VERSION "HNPBNYYYYYYYYYYYYYYYYYYYYYYYYYYYNNNNNNNNNN/4/%%/4/'%**4NNN///"

NS_ :

BS_:

BU_: ADL Aux_Device CANLogger CTU Central CentralMulti OffboardUDS Predecessor_Node RDC Radar SensorCANopen Simulator TEPM TIM TPMS iTEPM
BO_ 2566881294 Lausch_0 : 8 General_Tester
 SG_ V_RAW_0 : 0|16@1- (1,0) [-32768|32767] "1/512m/s" Vector__XXX
 SG_ N_EDGE_0 : 16|8@1+ (1,0) [0|255] "" Vector__XXX
 SG_ ERR_CTR_0 : 24|8@1- (1,0) [-128|127] "" Vector__XXX
 SG_ V_RAW_1 : 32|16@1- (1,0) [-32768|32767] "1/512m/s" Vector__XXX
 SG_ N_EDGE_1 : 48|8@1+ (1,0) [0|255] "" Vector__XXX
 SG_ ERR_CTR_1 : 56|8@1- (1,0) [-128|127] "" Vector__XXX

BO_ 2566881550 Lausch_1 : 8 General_Tester
 SG_ P21_p : 0|16@1- (1,0) [-32768|32767] "mbar" Vector__XXX
 SG_ P22_p : 16|16@1- (1,0) [-32768|32767] "mbar" Vector__XXX
 SG_ SC_v : 32|16@1- (1,0) [-32768|32767] "2mm/s" Vector__XXX
 SG_ SD_v : 48|16@1- (1,0) [-32768|32767] "2mm/s" Vector__XXX

BO_ 2566881806 Lausch_2 : 8 General_Tester
 SG_ VrefFilter : 0|16@1- (1,0) [-32768|32767] "2mm/s" Vector__XXX
 SG_ VrefStatus : 16|16@1+ (1,0) [0|65535] "" Vector__XXX
 SG_ Vref : 32|16@1- (1,0) [-32768|32767] "2mm/s" Vector__XXX
 SG_ P1_Virt_p : 48|16@1- (1,0) [-32768|32767] "mbar" Vector__XXX

BO_ 2566882062 Lausch_3 : 8 General_Tester
 SG_ P21_Pref : 0|16@1+ (1,0) [0|65535] "mbar" Vector__XXX
 SG_ P22_Pref : 16|16@1+ (1,0) [0|65535] "mbar" Vector__XXX
 SG_ P21_ACT : 32|16@1+ (1,0) [0|65535] "mbar" Vector__XXX
 SG_ P22_ACT : 48|16@1+ (1,0) [0|65535] "mbar" Vector__XXX

BO_ 2566882318 Lausch_4 : 8 General_Tester
 SG_ P21_PCLStatus : 0|8@1+ (1,0) [0|255] "" Vector__XXX
 SG_ P22_PCLStatus : 8|8@1+ (1,0) [0|255] "" Vector__XXX
 SG_ P21_Vcom : 16|8@1- (1,0) [-128|127] "" Vector__XXX
 SG_ P22_Vcom : 24|8@1- (1,0) [-128|127] "" Vector__XXX
 SG_ P21LearnLd : 32|8@1- (1,0) [-128|127] "" Vector__XXX
 SG_ P21LearnEx : 40|8@1- (1,0) [-128|127] "" Vector__XXX
 SG_ P22LearnLd : 48|8@1- (1,0) [-128|127] "" Vector__XXX
 SG_ P22LearnEx : 56|8@1- (1,0) [-128|127] "" Vector__XXX

BO_ 2566882574 Lausch_5 : 8 General_Tester
 SG_ OPDRStatus : 0|8@1+ (1,0) [0|255] "" Vector__XXX
 SG_ SuppStat : 8|8@1+ (1,0) [0|255] "" Vector__XXX
 SG_ OutputCON : 16|16@1+ (1,0) [0|65535] "" Vector__XXX
 SG_ OutputACT : 32|16@1+ (1,0) [0|65535] "" Vector__XXX
 SG_ OutputDEF : 48|16@1+ (1,0) [0|65535] "" Vector__XXX

BO_ 2566882830 Lausch_6 : 8 General_Tester
 SG_ PM_Status : 0|16@1+ (1,0) [0|65535] "" Vector__XXX
 SG_ U_PS : 16|8@1+ (200,0) [0|255] "mV" Vector__XXX
 SG_ U_IGN : 24|8@1+ (200,0) [0|255] "mV" Vector__XXX
 SG_ U_BL : 32|8@1+ (200,0) [0|255] "mV" Vector__XXX
 SG_ PowerState : 40|8@1+ (1,0) [0|255] "" Vector__XXX
 SG_ P2xIMeas : 48|8@1+ (100,0) [0|255] "mA" Vector__XXX
 SG_ AuxIMeas : 56|8@1+ (100,0) [0|255] "mA" Vector__XXX

BO_ 2566883086 Lausch_7 : 8 General_Tester
 SG_ P21_Pdes : 0|16@1+ (1,0) [0|65535] "mbar" Vector__XXX
 SG_ P22_Pdes : 16|16@1+ (1,0) [0|65535] "mbar" Vector__XXX
 SG_ P21_Test : 32|8@1+ (1,0) [0|255] "" Vector__XXX
 SG_ P22_Test : 40|8@1+ (1,0) [0|255] "" Vector__XXX

BO_ 2566883342 Lausch_8 : 8 General_Tester
 SG_ Runtime10ms : 0|16@1+ (1,0) [0|65535] "" Vector__XXX
 SG_ WLRed : 16|1@1+ (1,0) [0|255] "" Vector__XXX
 SG_ WLYellow : 17|1@1+ (1,0) [0|255] "" Vector__XXX
 SG_ WLInfo : 18|1@1+ (1,0) [0|255] "" Vector__XXX
 SG_ P21EBS_CNA : 19|1@1+ (1,0) [0|255] "" Vector__XXX
 SG_ P21BABS_CNA : 20|1@1+ (1,0) [0|255] "" Vector__XXX
 SG_ P21BCKP_CNA : 21|1@1+ (1,0) [0|255] "" Vector__XXX
 SG_ P22EBS_CNA : 22|1@1+ (1,0) [0|255] "" Vector__XXX
 SG_ P22BABS_CNA : 23|1@1+ (1,0) [0|255] "" Vector__XXX
 SG_ P22BCKP_CNA : 24|1@1+ (1,0) [0|255] "" Vector__XXX
 SG_ P2EBS_CNA : 25|1@1+ (1,0) [0|255] "" Vector__XXX
 SG_ P2BABS_CNA : 26|1@1+ (1,0) [0|255] "" Vector__XXX
 SG_ P2BCKP_CNA : 27|1@1+ (1,0) [0|255] "" Vector__XXX
 SG_ WSSC_CNA : 28|1@1+ (1,0) [0|255] "" Vector__XXX
 SG_ WSSD_CNA : 29|1@1+ (1,0) [0|255] "" Vector__XXX
 SG_ WSSE_CNA : 30|1@1+ (1,0) [0|255] "" Vector__XXX
 SG_ WSSF_CNA : 31|1@1+ (1,0) [0|255] "" Vector__XXX
 SG_ WSSA_CNA : 32|1@1+ (1,0) [0|255] "" Vector__XXX
 SG_ WSSB_CNA : 33|1@1+ (1,0) [0|255] "" Vector__XXX
 SG_ US_1 : 40|16@1+ (1,0) [0|65535] "mV" Vector__XXX

BO_ 2566883598 Lausch_9 : 8 General_Tester
 SG_ PS_P21_p : 0|16@1- (1,0) [-32768|32767] "mbar" Vector__XXX
 SG_ PS_P22_p : 16|16@1- (1,0) [-32768|32767] "mbar" Vector__XXX
 SG_ PS_P4_p : 32|16@1- (1,0) [-32768|32767] "mbar" Vector__XXX
 SG_ PS_P1_p : 48|16@1- (1,0) [-32768|32767] "mbar" Vector__XXX

BO_ 2566883854 Lausch_10 : 8 General_Tester
 SG_ PS_P42_p : 0|16@1- (1,0) [-32768|32767] "mbar" Vector__XXX
 SG_ PS_P21_Stat : 16|8@1+ (1,0) [0|255] "" Vector__XXX
 SG_ PS_P22_Stat : 24|8@1+ (1,0) [0|255] "" Vector__XXX
 SG_ PS_P4_Stat : 32|8@1+ (1,0) [0|255] "" Vector__XXX
 SG_ PS_P1_Stat : 40|8@1+ (1,0) [0|255] "" Vector__XXX
 SG_ PS_P42_Stat : 48|8@1+ (1,0) [0|255] "" Vector__XXX

BO_ 2566884110 Lausch_11 : 8 General_Tester
 SG_ P4_p : 0|16@1- (1,0) [-32768|32767] "mbar" Vector__XXX
 SG_ PneuDemand : 16|16@1- (1,0) [-32768|32767] "mbar" Vector__XXX
 SG_ CanDemand : 32|16@1+ (1,0) [0|65535] "mbar" Vector__XXX
 SG_ PdesDriver : 48|16@1+ (1,0) [0|65535] "mbar" Vector__XXX

BO_ 2566884366 Lausch_12 : 8 General_Tester
 SG_ XCHK_TIMER_CALIB : 0|16@1+ (1,0) [0|65535] "" Vector__XXX
 SG_ XCHK_MIN_P_INCR : 16|16@1- (1,0) [-32768|32767] "" Vector__XXX
 SG_ XCHK_CONTROL_STAT : 32|8@1+ (1,0) [0|255] "" Vector__XXX
 SG_ XCHK_RESULT_STAT : 40|8@1+ (1,0) [0|255] "" Vector__XXX
 SG_ XCHK_MASK_FULL : 48|8@1+ (1,0) [0|255] "" Vector__XXX
 SG_ XCHK_MASK_OP : 56|8@1+ (1,0) [0|255] "" Vector__XXX

BO_ 2566884622 Lausch_13 : 8 General_Tester
 SG_ P21_Iterm : 0|16@1+ (1,0) [0|65535] "" Vector__XXX
 SG_ P22_Iterm : 16|16@1+ (1,0) [0|65535] "" Vector__XXX
 SG_ P21_Ppid : 32|16@1+ (1,0) [0|65535] "" Vector__XXX
 SG_ P21_Prcov : 48|16@1+ (1,0) [0|65535] "" Vector__XXX

BO_ 2566884878 Lausch_14 : 8 General_Tester
 SG_ P21_StableTimer : 0|16@1+ (1,0) [0|65535] "" Vector__XXX
 SG_ P22_StableTimer : 16|16@1+ (1,0) [0|65535] "" Vector__XXX
 SG_ PdemCoordp21_Prio : 32|4@1+ (1,0) [0|255] "" Vector__XXX
 SG_ PdemCoordp22_Prio : 36|4@1+ (1,0) [0|255] "" Vector__XXX
 SG_ ABSP21PidStable : 40|1@1+ (1,0) [0|255] "" Vector__XXX
 SG_ ABSP21PidStopped : 41|1@1+ (1,0) [0|255] "" Vector__XXX
 SG_ ABSP21PidAllowOff : 42|1@1+ (1,0) [0|255] "" Vector__XXX
 SG_ ABSP21PidNoLoad : 43|1@1+ (1,0) [0|255] "" Vector__XXX
 SG_ ABSP21PidPdesLimit : 44|1@1+ (1,0) [0|255] "" Vector__XXX
 SG_ ABSP21RcovKeepDownP : 45|1@1+ (1,0) [0|255] "" Vector__XXX
 SG_ ABSP21RcovInshotNow : 46|1@1+ (1,0) [0|255] "" Vector__XXX
 SG_ ABSP21RcovDetectRunup : 47|1@1+ (1,0) [0|255] "" Vector__XXX
 SG_ ABSP22PidStable : 48|1@1+ (1,0) [0|255] "" Vector__XXX
 SG_ ABSP22PidStopped : 49|1@1+ (1,0) [0|255] "" Vector__XXX
 SG_ ABSP22PidAllowOff : 50|1@1+ (1,0) [0|255] "" Vector__XXX
 SG_ ABSP22PidNoLoad : 51|1@1+ (1,0) [0|255] "" Vector__XXX
 SG_ ABSP22PidPdesLimit : 52|1@1+ (1,0) [0|255] "" Vector__XXX
 SG_ ABSP22RcovKeepDownP : 53|1@1+ (1,0) [0|255] "" Vector__XXX
 SG_ ABSP22RcovInshotNow : 54|1@1+ (1,0) [0|255] "" Vector__XXX
 SG_ ABSP22RcovDetectRunup : 55|1@1+ (1,0) [0|255] "" Vector__XXX
 SG_ P21_PrcovTimer : 56|8@1+ (1,0) [0|255] "" Vector__XXX

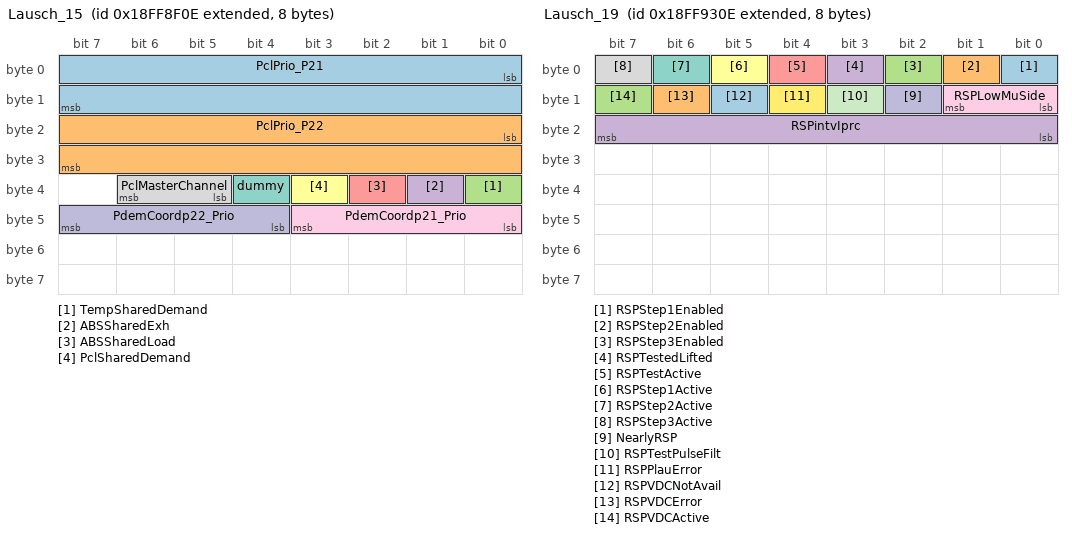
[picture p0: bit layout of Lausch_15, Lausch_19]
BO_ 2566885134 Lausch_15 : 8 General_Tester
 SG_ PclPrio_P21 : 0|16@1+ (1,0) [0|65535] "" Vector__XXX
 SG_ PclPrio_P22 : 16|16@1+ (1,0) [0|65535] "" Vector__XXX
 SG_ TempSharedDemand : 32|1@1+ (1,0) [0|255] "" Vector__XXX
 SG_ ABSSharedExh : 33|1@1+ (1,0) [0|255] "" Vector__XXX
 SG_ ABSSharedLoad : 34|1@1+ (1,0) [0|255] "" Vector__XXX
 SG_ PclSharedDemand : 35|1@1+ (1,0) [0|255] "" Vector__XXX
 SG_ dummy : 36|1@1+ (1,0) [0|255] "" Vector__XXX
 SG_ PclMasterChannel : 37|2@1+ (1,0) [0|255] "" Vector__XXX
 SG_ PdemCoordp21_Prio : 40|4@1+ (1,0) [0|255] "" Vector__XXX
 SG_ PdemCoordp22_Prio : 44|4@1+ (1,0) [0|255] "" Vector__XXX

BO_ 2566885390 Lausch_16 : 8 General_Tester
 SG_ PneuDemVirtDTerm : 0|16@1- (1,0) [-32768|32767] "mbar" Vector__XXX
 SG_ PneuDemandVirtIncr : 16|16@1- (1,0) [-32768|32767] "mbar" Vector__XXX

BO_ 2566885646 Lausch_17 : 8 General_Tester
 SG_ AyFilt : 0|16@1- (1,0) [-32768|32767] "mm/s2" Vector__XXX
 SG_ AyHFilt : 16|16@1- (1,0) [-32768|32767] "mm/s2" Vector__XXX
 SG_ AyLimLeft : 32|16@1- (1,0) [-32768|32767] "mm/s2" Vector__XXX
 SG_ AyLimRight : 48|16@1- (1,0) [-32768|32767] "mm/s2" Vector__XXX

BO_ 2566885902 Lausch_18 : 8 General_Tester
 SG_ dAyWeight : 0|16@1- (1,0) [-32768|32767] "mm/s2" Vector__XXX
 SG_ RSPtUnstabC : 16|8@1- (1,0) [-128|127] "10ms" Vector__XXX
 SG_ RSPtUnstabD : 24|8@1- (1,0) [-128|127] "10ms" Vector__XXX
 SG_ RSPtUnstabE : 32|8@1- (1,0) [-128|127] "10ms" Vector__XXX
 SG_ RSPtUnstabF : 40|8@1- (1,0) [-128|127] "10ms" Vector__XXX
 SG_ RSPtUnstabA : 48|8@1- (1,0) [-128|127] "10ms" Vector__XXX
 SG_ RSPtUnstabB : 56|8@1- (1,0) [-128|127] "10ms" Vector__XXX

BO_ 2566886158 Lausch_19 : 8 General_Tester
 SG_ RSPStep1Enabled : 0|1@1+ (1,0) [0|65535] "bits" Vector__XXX
 SG_ RSPStep2Enabled : 1|1@1+ (1,0) [0|65535] "bits" Vector__XXX
 SG_ RSPStep3Enabled : 2|1@1+ (1,0) [0|65535] "bits" Vector__XXX
 SG_ RSPTestedLifted : 3|1@1+ (1,0) [0|65535] "bits" Vector__XXX
 SG_ RSPTestActive : 4|1@1+ (1,0) [0|65535] "bits" Vector__XXX
 SG_ RSPStep1Active : 5|1@1+ (1,0) [0|65535] "bits" Vector__XXX
 SG_ RSPStep2Active : 6|1@1+ (1,0) [0|65535] "bits" Vector__XXX
 SG_ RSPStep3Active : 7|1@1+ (1,0) [0|65535] "bits" Vector__XXX
 SG_ RSPLowMuSide : 8|2@1+ (1,0) [0|65535] "bits" Vector__XXX
 SG_ NearlyRSP : 10|1@1+ (1,0) [0|65535] "bits" Vector__XXX
 SG_ RSPTestPulseFilt : 11|1@1+ (1,0) [0|65535] "bits" Vector__XXX
 SG_ RSPPlauError : 12|1@1+ (1,0) [0|65535] "bits" Vector__XXX
 SG_ RSPVDCNotAvail : 13|1@1+ (1,0) [0|65535] "bits" Vector__XXX
 SG_ RSPVDCError : 14|1@1+ (1,0) [0|65535] "bits" Vector__XXX
 SG_ RSPVDCActive : 15|1@1+ (1,0) [0|65535] "bits" Vector__XXX
 SG_ RSPintvIprc : 16|8@1- (1,0) [-128|127] "%" Vector__XXX

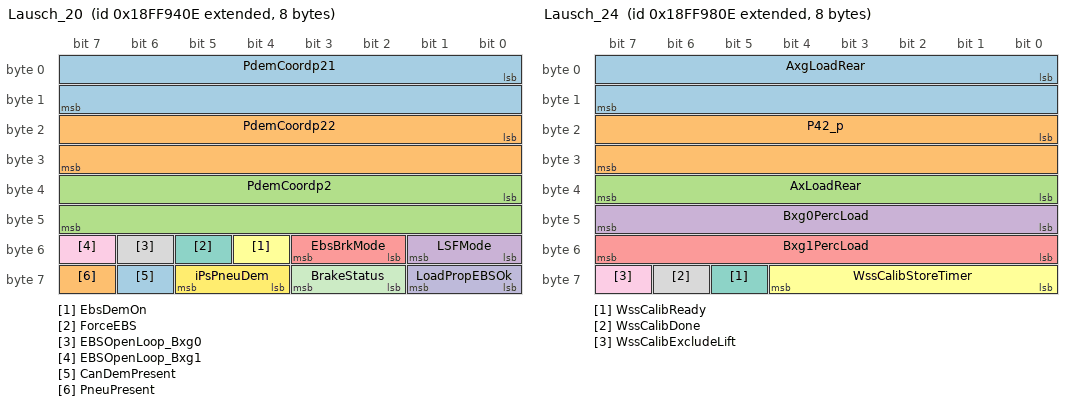
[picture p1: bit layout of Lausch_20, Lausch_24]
BO_ 2566886414 Lausch_20 : 8 General_Tester
 SG_ PdemCoordp21 : 0|16@1+ (1,0) [0|65535] "mbar" Vector__XXX
 SG_ PdemCoordp22 : 16|16@1+ (1,0) [0|65535] "mbar" Vector__XXX
 SG_ PdemCoordp2 : 32|16@1+ (1,0) [0|65535] "mbar" Vector__XXX
 SG_ LSFMode : 48|2@1+ (1,0) [0|255] "" Vector__XXX
 SG_ EbsBrkMode : 50|2@1+ (1,0) [0|255] "" Vector__XXX
 SG_ EbsDemOn : 52|1@1+ (1,0) [0|255] "" Vector__XXX
 SG_ ForceEBS : 53|1@1+ (1,0) [0|255] "" Vector__XXX
 SG_ EBSOpenLoop_Bxg0 : 54|1@1+ (1,0) [0|255] "" Vector__XXX
 SG_ EBSOpenLoop_Bxg1 : 55|1@1+ (1,0) [0|255] "" Vector__XXX
 SG_ LoadPropEBSOk : 56|2@1+ (1,0) [0|255] "" Vector__XXX
 SG_ BrakeStatus : 58|2@1+ (1,0) [0|255] "" Vector__XXX
 SG_ iPsPneuDem : 60|2@1+ (1,0) [0|255] "" Vector__XXX
 SG_ CanDemPresent : 62|1@1+ (1,0) [0|255] "" Vector__XXX
 SG_ PneuPresent : 63|1@1+ (1,0) [0|255] "" Vector__XXX

BO_ 2566886670 Lausch_21 : 8 General_Tester
 SG_ AuxVref : 0|16@1- (1,0) [-32768|32767] "" Vector__XXX
 SG_ SPState : 16|8@1+ (1,0) [0|255] "" Vector__XXX
 SG_ AuxOutputActive : 24|1@1+ (1,0) [0|255] "" Vector__XXX
 SG_ PWStatus : 32|8@1+ (1,0) [0|255] "" Vector__XXX
 SG_ PWCount : 40|8@1+ (1,0) [0|255] "" Vector__XXX
 SG_ PWBrakeCount : 48|8@1+ (1,0) [0|255] "" Vector__XXX
 SG_ StatePW : 56|8@1+ (1,0) [0|255] "" Vector__XXX

BO_ 2566886926 Lausch_22 : 8 General_Tester
 SG_ BLIRequests : 0|8@1+ (1,0) [0|255] "" Vector__XXX
 SG_ BLIInhibition : 8|8@1+ (1,0) [0|255] "" Vector__XXX
 SG_ BLINewInhReq : 16|8@1+ (1,0) [0|255] "" Vector__XXX
 SG_ BLINewRelReq : 24|8@1+ (1,0) [0|255] "" Vector__XXX
 SG_ BLIBLA_Ovr : 32|16@1- (1,0) [-32768|32767] "" Vector__XXX
 SG_ BLITbp : 48|16@1+ (1,0) [0|65535] "" Vector__XXX

BO_ 2566887182 Lausch_23 : 8 General_Tester
 SG_ BLISbp : 0|8@1+ (1,0) [0|255] "" Vector__XXX
 SG_ BLIAuxOvr : 8|1@1+ (1,0) [0|255] "" Vector__XXX
 SG_ BLIBPOvr : 9|1@1+ (1,0) [0|255] "" Vector__XXX
 SG_ BLIOvr2Store : 10|1@1+ (1,0) [0|255] "" Vector__XXX
 SG_ AuxOvrLocalVar : 11|1@1+ (1,0) [0|255] "" Vector__XXX
 SG_ BPOvrLocalVar : 12|1@1+ (1,0) [0|255] "" Vector__XXX
 SG_ BLIinhibitCAN : 13|1@1+ (1,0) [0|255] "" Vector__XXX
 SG_ BLIovrdCAN : 14|1@1+ (1,0) [0|255] "" Vector__XXX
 SG_ SALLogicOutput : 16|1@1+ (1,0) [0|255] "" Vector__XXX
 SG_ BackLightSw : 17|1@1+ (1,0) [0|255] "" Vector__XXX
 SG_ SALABSError : 18|1@1+ (1,0) [0|255] "" Vector__XXX
 SG_ ForceSAL : 19|1@1+ (1,0) [0|255] "" Vector__XXX
 SG_ ISSLogicOutput : 20|1@1+ (1,0) [0|255] "" Vector__XXX
 SG_ RLFOn : 24|1@1+ (1,0) [0|255] "" Vector__XXX
 SG_ LoadChangedInStandstill : 25|1@1+ (1,0) [0|255] "" Vector__XXX
 SG_ PdemRLF : 32|16@1+ (1,0) [0|65535] "" Vector__XXX
 SG_ AuxADLFlagsreserved : 48|1@1+ (1,0) [0|255] "" Vector__XXX
 SG_ AuxADLFlagsinstrerr : 49|1@1+ (1,0) [0|255] "" Vector__XXX
 SG_ AuxADLFlagsvererr : 50|1@1+ (1,0) [0|255] "" Vector__XXX
 SG_ AuxADLFlagschksmerr : 51|1@1+ (1,0) [0|255] "" Vector__XXX
 SG_ AuxADLFlagsproginitcomp : 52|1@1+ (1,0) [0|255] "" Vector__XXX
 SG_ AuxADLFlagsfirstcyclecomp : 53|1@1+ (1,0) [0|255] "" Vector__XXX
 SG_ AuxADLFlagsinstrnoreturn : 54|1@1+ (1,0) [0|255] "" Vector__XXX
 SG_ AuxADLFlagsenablerx : 55|1@1+ (1,0) [0|255] "" Vector__XXX
 SG_ BLS : 56|8@1+ (1,0) [0|255] "" Vector__XXX

BO_ 2566887438 Lausch_24 : 8 General_Tester
 SG_ AxgLoadRear : 0|16@1+ (10,0) [0|65535] "kg" Vector__XXX
 SG_ P42_p : 16|16@1- (1,0) [-32768|32767] "mbar" Vector__XXX
 SG_ AxLoadRear : 32|8@1+ (1,0) [0|255] "%" Vector__XXX
 SG_ Bxg0PercLoad : 40|8@1+ (1,0) [0|255] "%" Vector__XXX
 SG_ Bxg1PercLoad : 48|8@1+ (1,0) [0|255] "%" Vector__XXX
 SG_ WssCalibStoreTimer  : 56|5@1+ (1,0) [0|255] "" Vector__XXX
 SG_ WssCalibReady  : 61|1@1+ (1,0) [0|255] "" Vector__XXX
 SG_ WssCalibDone  : 62|1@1+ (1,0) [0|255] "" Vector__XXX
 SG_ WssCalibExcludeLift  : 63|1@1+ (1,0) [0|255] "" Vector__XXX

BO_ 2566887694 Lausch_25 : 8 General_Tester
 SG_ Level_Rear_RearRight : 0|16@1- (0.125,0) [-32768|32767] "mm" Vector__XXX
 SG_ TargetLevel_Rear_RearRight : 16|16@1- (0.125,0) [-32768|32767] "mm" Vector__XXX
 SG_ LevellingActive : 32|1@1+ (1,0) [0|65535] "bits" Vector__XXX
 SG_ ELC_Prohibited : 33|1@1+ (1,0) [0|65535] "bits" Vector__XXX
 SG_ ELC_TargetChanged : 34|1@1+ (1,0) [0|65535] "bits" Vector__XXX
 SG_ TSR_TriggeredByELC : 35|1@1+ (1,0) [0|65535] "bits" Vector__XXX
 SG_ iLvl_State : 36|2@1+ (1,0) [0|65535] "bits" Vector__XXX
 SG_ LAC1_Active : 38|1@1+ (1,0) [0|65535] "bits" Vector__XXX
 SG_ PneuBackup_Active_0 : 39|1@1+ (1,0) [0|65535] "bits" Vector__XXX
 SG_ PCV_iLvl2_State : 40|2@1+ (1,0) [0|65535] "bits" Vector__XXX
 SG_ LAC2_State : 42|1@1+ (1,0) [0|65535] "bits" Vector__XXX
 SG_ VehicleStandstill : 43|1@1+ (1,0) [0|65535] "bits" Vector__XXX
 SG_ VehicleBraking : 44|1@1+ (1,0) [0|65535] "bits" Vector__XXX
 SG_ LCStandstill : 45|1@1+ (1,0) [0|65535] "bits" Vector__XXX
 SG_ SupPresTooLowForLAC : 46|1@1+ (1,0) [0|65535] "bits" Vector__XXX
 SG_ AboveRTRSpeed : 47|1@1+ (1,0) [0|65535] "bits" Vector__XXX
 SG_ TAMBits : 48|16@1+ (1,0) [0|65535] "bits" Vector__XXX

BO_ 2566887950 Lausch_26 : 8 General_Tester
 SG_ P21_Pref : 0|16@1+ (1,0) [0|65535] "mbar" Vector__XXX
 SG_ P22_Pref : 16|16@1+ (1,0) [0|65535] "mbar" Vector__XXX
 SG_ P21_Pdes : 32|16@1+ (1,0) [0|65535] "mbar" Vector__XXX
 SG_ P22_Pdes : 48|16@1+ (1,0) [0|65535] "mbar" Vector__XXX

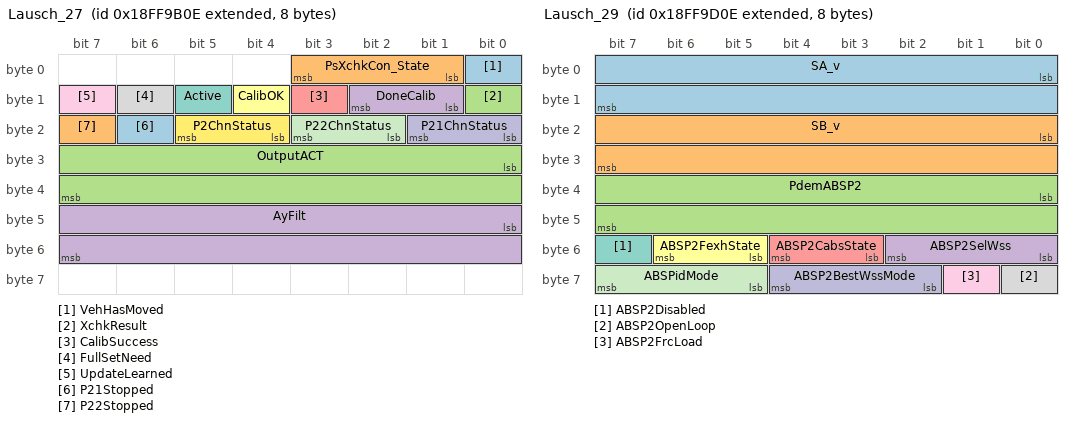
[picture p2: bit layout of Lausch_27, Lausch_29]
BO_ 2566888206 Lausch_27 : 8 General_Tester
 SG_ VehHasMoved  : 0|1@1+ (1,0) [0|255] "" Vector__XXX
 SG_ PsXchkCon_State  : 1|3@1+ (1,0) [0|255] "" Vector__XXX
 SG_ XchkResult  : 8|1@1+ (1,0) [0|255] "" Vector__XXX
 SG_ DoneCalib  : 9|2@1+ (1,0) [0|255] "" Vector__XXX
 SG_ CalibSuccess : 11|1@1+ (1,0) [0|255] "" Vector__XXX
 SG_ CalibOK : 12|1@1+ (1,0) [0|255] "" Vector__XXX
 SG_ Active : 13|1@1+ (1,0) [0|255] "" Vector__XXX
 SG_ FullSetNeed : 14|1@1+ (1,0) [0|255] "" Vector__XXX
 SG_ UpdateLearned : 15|1@1+ (1,0) [0|255] "" Vector__XXX
 SG_ P21ChnStatus  : 16|2@1+ (1,0) [0|255] "" Vector__XXX
 SG_ P22ChnStatus  : 18|2@1+ (1,0) [0|255] "" Vector__XXX
 SG_ P2ChnStatus  : 20|2@1+ (1,0) [0|255] "" Vector__XXX
 SG_ P21Stopped  : 22|1@1+ (1,0) [0|255] "" Vector__XXX
 SG_ P22Stopped  : 23|1@1+ (1,0) [0|255] "" Vector__XXX
 SG_ OutputACT : 24|16@1+ (1,0) [0|65535] "" Vector__XXX
 SG_ AyFilt : 40|16@1- (1,0) [-32768|32767] "" Vector__XXX

BO_ 2566888462 Lausch_28 : 8 General_Tester
 SG_ PdemEbsBxg0 : 0|16@1+ (1,0) [0|65535] "mbar" Vector__XXX
 SG_ PdemEbsBxg1 : 16|16@1+ (1,0) [0|65535] "mbar" Vector__XXX
 SG_ PdemABSP21 : 32|16@1+ (1,0) [0|65535] "mbar" Vector__XXX
 SG_ PdemABSP22 : 48|16@1+ (1,0) [0|65535] "mbar" Vector__XXX

BO_ 2566888718 Lausch_29 : 8 General_Tester
 SG_ SA_v : 0|16@1- (1,0) [-32768|32767] "2mm/s" Vector__XXX
 SG_ SB_v : 16|16@1- (1,0) [-32768|32767] "2mm/s" Vector__XXX
 SG_ PdemABSP2 : 32|16@1+ (1,0) [0|65535] "mbar" Vector__XXX
 SG_ ABSP2SelWss : 48|3@1+ (1,0) [0|255] "" Vector__XXX
 SG_ ABSP2CabsState : 51|2@1+ (1,0) [0|255] "" Vector__XXX
 SG_ ABSP2FexhState : 53|2@1+ (1,0) [0|255] "" Vector__XXX
 SG_ ABSP2Disabled : 55|1@1+ (1,0) [0|255] "" Vector__XXX
 SG_ ABSP2OpenLoop : 56|1@1+ (1,0) [0|255] "" Vector__XXX
 SG_ ABSP2FrcLoad : 57|1@1+ (1,0) [0|255] "" Vector__XXX
 SG_ ABSP2BestWssMode : 58|3@1+ (1,0) [0|255] "" Vector__XXX
 SG_ ABSPidMode : 61|3@1+ (1,0) [0|255] "" Vector__XXX

BO_ 2566888974 Lausch_30 : 8 General_Tester
 SG_ PdemCoordp21 : 0|16@1+ (1,0) [0|65535] "mbar" Vector__XXX
 SG_ PdemCoordp22 : 16|16@1+ (1,0) [0|65535] "mbar" Vector__XXX
 SG_ SE_v : 32|16@1- (1,0) [-32768|32767] "2mm/s" Vector__XXX
 SG_ SF_v : 48|16@1- (1,0) [-32768|32767] "2mm/s" Vector__XXX

BO_ 2566889230 Lausch_31 : 8 General_Tester
 SG_ P4_Stat : 0|8@1+ (1,0) [0|255] "" Vector__XXX
 SG_ EM_P4_Stat : 8|8@1+ (1,0) [0|255] "" Vector__XXX
 SG_ EM_P2_p : 16|16@1- (1,0) [-32768|32767] "mbar" Vector__XXX
 SG_ EM_P4_p : 32|16@1- (1,0) [-32768|32767] "mbar" Vector__XXX
 SG_ EM_P42_p : 48|16@1- (1,0) [-32768|32767] "mbar" Vector__XXX

BO_ 2566889486 Lausch_32 : 8 General_Tester
 SG_ BLMTippingAngFilt : 0|16@1- (1,0) [-32768|32767] "" Vector__XXX
 SG_ BLMAngInhAct : 16|16@1- (1,0) [-32768|32767] "" Vector__XXX
 SG_ BLMCalib : 32|8@1+ (1,0) [0|255] "" Vector__XXX
 SG_ BLMDir : 40|8@1+ (1,0) [0|255] "" Vector__XXX

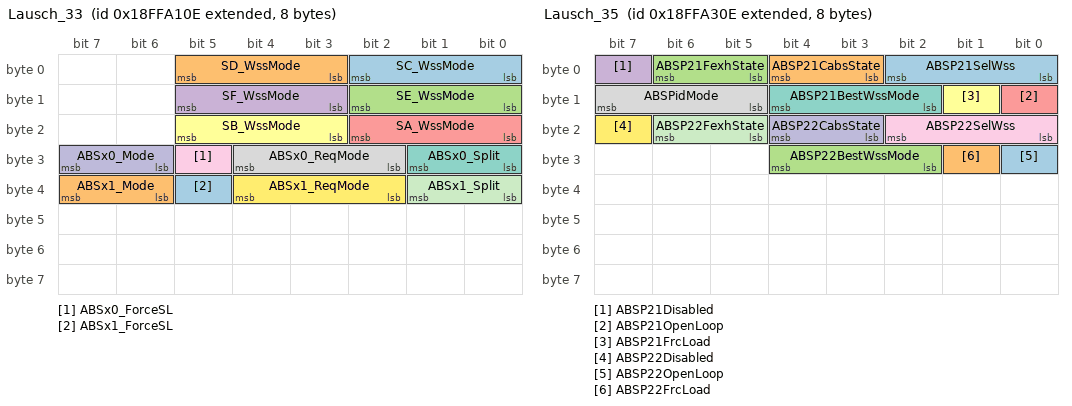
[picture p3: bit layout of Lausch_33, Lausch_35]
BO_ 2566889742 Lausch_33 : 8 General_Tester
 SG_ SC_WssMode : 0|3@1+ (1,0) [0|255] "" Vector__XXX
 SG_ SD_WssMode : 3|3@1+ (1,0) [0|255] "" Vector__XXX
 SG_ SE_WssMode : 8|3@1+ (1,0) [0|255] "" Vector__XXX
 SG_ SF_WssMode : 11|3@1+ (1,0) [0|255] "" Vector__XXX
 SG_ SA_WssMode : 16|3@1+ (1,0) [0|255] "" Vector__XXX
 SG_ SB_WssMode : 19|3@1+ (1,0) [0|255] "" Vector__XXX
 SG_ ABSx0_Split : 24|2@1+ (1,0) [0|255] "" Vector__XXX
 SG_ ABSx0_ReqMode : 26|3@1+ (1,0) [0|255] "" Vector__XXX
 SG_ ABSx0_ForceSL : 29|1@1+ (1,0) [0|255] "" Vector__XXX
 SG_ ABSx0_Mode : 30|2@1+ (1,0) [0|255] "" Vector__XXX
 SG_ ABSx1_Split : 32|2@1+ (1,0) [0|255] "" Vector__XXX
 SG_ ABSx1_ReqMode : 34|3@1+ (1,0) [0|255] "" Vector__XXX
 SG_ ABSx1_ForceSL : 37|1@1+ (1,0) [0|255] "" Vector__XXX
 SG_ ABSx1_Mode : 38|2@1+ (1,0) [0|255] "" Vector__XXX

BO_ 2566889998 Lausch_34 : 8 General_Tester
 SG_ SC_WssTest : 0|8@1+ (1,0) [0|255] "" Vector__XXX
 SG_ SD_WssTest : 8|8@1+ (1,0) [0|255] "" Vector__XXX
 SG_ SE_WssTest : 16|8@1+ (1,0) [0|255] "" Vector__XXX
 SG_ SF_WssTest : 24|8@1+ (1,0) [0|255] "" Vector__XXX
 SG_ SA_WssTest : 32|8@1+ (1,0) [0|255] "" Vector__XXX
 SG_ SB_WssTest : 40|8@1+ (1,0) [0|255] "" Vector__XXX

BO_ 2566890254 Lausch_35 : 8 General_Tester
 SG_ ABSP21SelWss : 0|3@1+ (1,0) [0|255] "" Vector__XXX
 SG_ ABSP21CabsState : 3|2@1+ (1,0) [0|255] "" Vector__XXX
 SG_ ABSP21FexhState : 5|2@1+ (1,0) [0|255] "" Vector__XXX
 SG_ ABSP21Disabled : 7|1@1+ (1,0) [0|255] "" Vector__XXX
 SG_ ABSP21OpenLoop : 8|1@1+ (1,0) [0|255] "" Vector__XXX
 SG_ ABSP21FrcLoad : 9|1@1+ (1,0) [0|255] "" Vector__XXX
 SG_ ABSP21BestWssMode : 10|3@1+ (1,0) [0|255] "" Vector__XXX
 SG_ ABSPidMode : 13|3@1+ (1,0) [0|255] "" Vector__XXX
 SG_ ABSP22SelWss : 16|3@1+ (1,0) [0|255] "" Vector__XXX
 SG_ ABSP22CabsState : 19|2@1+ (1,0) [0|255] "" Vector__XXX
 SG_ ABSP22FexhState : 21|2@1+ (1,0) [0|255] "" Vector__XXX
 SG_ ABSP22Disabled : 23|1@1+ (1,0) [0|255] "" Vector__XXX
 SG_ ABSP22OpenLoop : 24|1@1+ (1,0) [0|255] "" Vector__XXX
 SG_ ABSP22FrcLoad : 25|1@1+ (1,0) [0|255] "" Vector__XXX
 SG_ ABSP22BestWssMode : 26|3@1+ (1,0) [0|255] "" Vector__XXX

BO_ 2566890510 Lausch_36 : 8 General_Tester
 SG_ SC_WssCalibDiamDev : 0|8@1- (1,0) [-128|127] "" Vector__XXX
 SG_ SD_WssCalibDiamDev : 8|8@1- (1,0) [-128|127] "" Vector__XXX
 SG_ SE_WssCalibDiamDev : 16|8@1- (1,0) [-128|127] "" Vector__XXX
 SG_ SF_WssCalibDiamDev : 24|8@1- (1,0) [-128|127] "" Vector__XXX
 SG_ SA_WssCalibDiamDev : 32|8@1- (1,0) [-128|127] "" Vector__XXX
 SG_ SB_WssCalibDiamDev : 40|8@1- (1,0) [-128|127] "" Vector__XXX

BO_ 2566890766 Lausch_37 : 8 General_Tester
 SG_ SC_Airgap : 0|16@1- (1,0) [-32768|32767] "" Vector__XXX
 SG_ SD_Airgap : 16|16@1- (1,0) [-32768|32767] "" Vector__XXX
 SG_ SE_Airgap : 32|16@1- (1,0) [-32768|32767] "" Vector__XXX
 SG_ SF_Airgap : 48|16@1- (1,0) [-32768|32767] "" Vector__XXX

BO_ 2566891022 Lausch_38 : 8 General_Tester
 SG_ SA_Airgap : 0|16@1- (1,0) [-32768|32767] "" Vector__XXX
 SG_ SB_Airgap : 16|16@1- (1,0) [-32768|32767] "" Vector__XXX
 SG_ SC_OverInstallDone : 32|1@1+ (1,0) [0|255] "" Vector__XXX
 SG_ SC_AirgapCheckAct : 33|1@1+ (1,0) [0|255] "" Vector__XXX
 SG_ SC_ConfirmedNoAirgap : 34|1@1+ (1,0) [0|255] "" Vector__XXX
 SG_ SC_airgap_suspect : 35|1@1+ (1,0) [0|255] "" Vector__XXX
 SG_ SD_OverInstallDone : 36|1@1+ (1,0) [0|255] "" Vector__XXX
 SG_ SD_AirgapCheckAct : 37|1@1+ (1,0) [0|255] "" Vector__XXX
 SG_ SD_ConfirmedNoAirgap : 38|1@1+ (1,0) [0|255] "" Vector__XXX
 SG_ SD_airgap_suspect : 39|1@1+ (1,0) [0|255] "" Vector__XXX
 SG_ SE_OverInstallDone : 40|1@1+ (1,0) [0|255] "" Vector__XXX
 SG_ SE_AirgapCheckAct : 41|1@1+ (1,0) [0|255] "" Vector__XXX
 SG_ SE_ConfirmedNoAirgap : 42|1@1+ (1,0) [0|255] "" Vector__XXX
 SG_ SE_airgap_suspect : 43|1@1+ (1,0) [0|255] "" Vector__XXX
 SG_ SF_OverInstallDone : 44|1@1+ (1,0) [0|255] "" Vector__XXX
 SG_ SF_AirgapCheckAct : 45|1@1+ (1,0) [0|255] "" Vector__XXX
 SG_ SF_ConfirmedNoAirgap : 46|1@1+ (1,0) [0|255] "" Vector__XXX
 SG_ SF_airgap_suspect : 47|1@1+ (1,0) [0|255] "" Vector__XXX
 SG_ SA_OverInstallDone : 48|1@1+ (1,0) [0|255] "" Vector__XXX
 SG_ SA_AirgapCheckAct : 49|1@1+ (1,0) [0|255] "" Vector__XXX
 SG_ SA_ConfirmedNoAirgap : 50|1@1+ (1,0) [0|255] "" Vector__XXX
 SG_ SA_airgap_suspect : 51|1@1+ (1,0) [0|255] "" Vector__XXX
 SG_ SB_OverInstallDone : 52|1@1+ (1,0) [0|255] "" Vector__XXX
 SG_ SB_AirgapCheckAct : 53|1@1+ (1,0) [0|255] "" Vector__XXX
 SG_ SB_ConfirmedNoAirgap : 54|1@1+ (1,0) [0|255] "" Vector__XXX
 SG_ SB_airgap_suspect : 55|1@1+ (1,0) [0|255] "" Vector__XXX

BO_ 2566891278 Lausch_39 : 8 General_Tester
 SG_ AxLoadDolly : 0|8@1+ (1,0) [0|255] "%" Vector__XXX
 SG_ AxgLoadDolly : 8|16@1+ (10,0) [0|65535] "kg" Vector__XXX
 SG_ TargetLevel_Front_RearLeft : 24|16@1- (0.125,0) [-32768|32767] "mm" Vector__XXX
 SG_ Level_Front_RearLeft : 40|16@1- (0.125,0) [-32768|32767] "mm" Vector__XXX
 SG_ TargetPercLoad_Sxg0 : 56|8@1+ (1,0) [0|255] "%" Vector__XXX

BO_ 2566891534 Lausch_40 : 8 General_Tester
 SG_ TargetPercLoad_Sxg1 : 0|8@1+ (1,0) [0|255] "%" Vector__XXX
 SG_ TargetPercLoad_Sxg2 : 8|8@1+ (1,0) [0|255] "%" Vector__XXX
 SG_ Sxg0_PercLoad : 16|8@1+ (1,0) [0|255] "%" Vector__XXX
 SG_ Sxg1_PercLoad : 24|8@1+ (1,0) [0|255] "%" Vector__XXX
 SG_ Sxg2_PercLoad : 32|8@1+ (1,0) [0|255] "%" Vector__XXX

BO_ 2566891790 Lausch_41 : 8 General_Tester
 SG_ ABSP21Pmax : 0|16@1+ (1,0) [0|65535] "mbar" Vector__XXX
 SG_ ABSP21Pref : 16|16@1+ (1,0) [0|65535] "mbar" Vector__XXX
 SG_ ABSP21Pact : 32|16@1+ (1,0) [0|65535] "mbar" Vector__XXX
 SG_ ABSP21PrioTimer : 48|8@1+ (1,0) [0|255] "" Vector__XXX

BO_ 2566892046 Lausch_42 : 8 General_Tester
 SG_ ABSP22Pmax : 0|16@1+ (1,0) [0|65535] "mbar" Vector__XXX
 SG_ ABSP22Pref : 16|16@1+ (1,0) [0|65535] "mbar" Vector__XXX
 SG_ ABSP22Pact : 32|16@1+ (1,0) [0|65535] "mbar" Vector__XXX
 SG_ ABSP22PrioTimer : 48|8@1+ (1,0) [0|255] "" Vector__XXX

BO_ 2566892302 Lausch_43 : 8 General_Tester
 SG_ AyOffset : 0|16@1- (1,0) [-32768|32767] "mm/s2" Vector__XXX
 SG_ AyCalc : 16|16@1- (1,0) [-32768|32767] "mm/s2" Vector__XXX
 SG_ TurnSlip_L : 32|8@1- (1,0) [-128|127] "%" Vector__XXX
 SG_ TurnSlip_R : 40|8@1- (1,0) [-128|127] "%" Vector__XXX
 SG_ TurnSlip_RL : 48|8@1- (1,0) [-128|127] "%" Vector__XXX
 SG_ TurnSlip_RR : 56|8@1- (1,0) [-128|127] "%" Vector__XXX

BO_ 2566892558 Lausch_44 : 8 General_Tester
 SG_ P21PrefUncont : 0|16@1- (1,0) [-32768|32767] "mbar" Vector__XXX
 SG_ P21PrefLeak : 16|16@1- (1,0) [-32768|32767] "mbar" Vector__XXX
 SG_ P21PlauInteg : 32|16@1- (1,0) [-32768|32767] "mbar" Vector__XXX
 SG_ P21PlauVActCtr : 48|8@1+ (1,0) [0|255] "" Vector__XXX
 SG_ P21PlauHighCtr : 56|8@1+ (1,0) [0|255] "" Vector__XXX

BO_ 2566892814 Lausch_45 : 8 General_Tester
 SG_ P22PrefUncont : 0|16@1- (1,0) [-32768|32767] "mbar" Vector__XXX
 SG_ P22PrefLeak : 16|16@1- (1,0) [-32768|32767] "mbar" Vector__XXX
 SG_ P22PlauInteg : 32|16@1- (1,0) [-32768|32767] "mbar" Vector__XXX
 SG_ P22PlauVActCtr : 48|8@1+ (1,0) [0|255] "" Vector__XXX
 SG_ P22PlauHighCtr : 56|8@1+ (1,0) [0|255] "" Vector__XXX

BO_ 2566893070 Lausch_46 : 8 General_Tester
 SG_ ValveActCntr_Id : 0|8@1+ (1,0) [0|255] "" Vector__XXX
 SG_ ValveActCntr_Val : 8|32@1+ (1,0) [0|4294967295] "" Vector__XXX

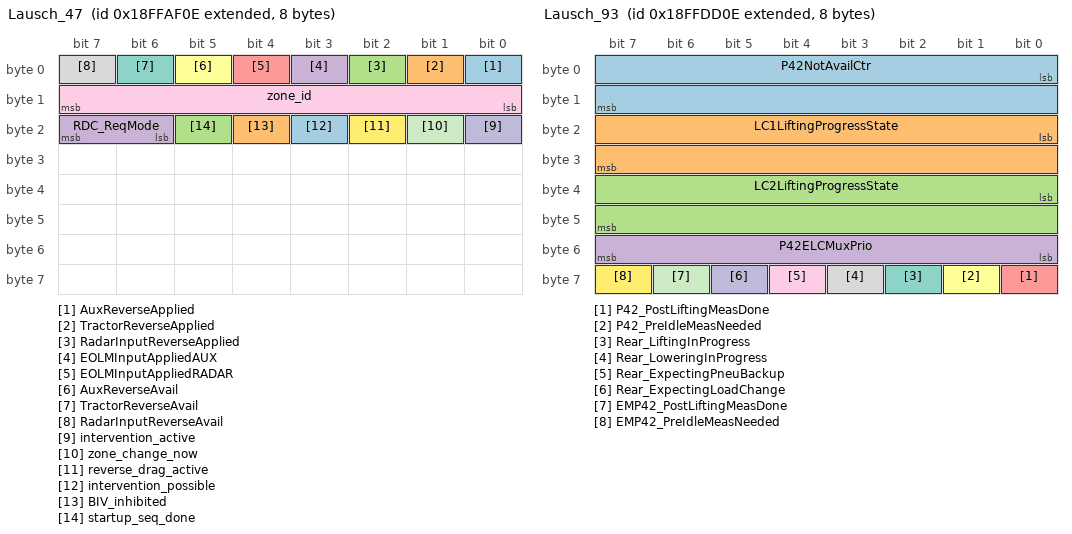
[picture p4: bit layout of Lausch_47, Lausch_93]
BO_ 2566893326 Lausch_47 : 8 General_Tester
 SG_ AuxReverseApplied : 0|1@1+ (1,0) [0|255] "" Vector__XXX
 SG_ TractorReverseApplied : 1|1@1+ (1,0) [0|255] "" Vector__XXX
 SG_ RadarInputReverseApplied : 2|1@1+ (1,0) [0|255] "" Vector__XXX
 SG_ EOLMInputAppliedAUX : 3|1@1+ (1,0) [0|255] "" Vector__XXX
 SG_ EOLMInputAppliedRADAR : 4|1@1+ (1,0) [0|255] "" Vector__XXX
 SG_ AuxReverseAvail : 5|1@1+ (1,0) [0|255] "" Vector__XXX
 SG_ TractorReverseAvail : 6|1@1+ (1,0) [0|255] "" Vector__XXX
 SG_ RadarInputReverseAvail : 7|1@1+ (1,0) [0|255] "" Vector__XXX
 SG_ zone_id : 8|8@1+ (1,0) [0|255] "" Vector__XXX
 SG_ intervention_active : 16|1@1+ (1,0) [0|255] "" Vector__XXX
 SG_ zone_change_now : 17|1@1+ (1,0) [0|255] "" Vector__XXX
 SG_ reverse_drag_active : 18|1@1+ (1,0) [0|255] "" Vector__XXX
 SG_ intervention_possible : 19|1@1+ (1,0) [0|255] "" Vector__XXX
 SG_ BIV_inhibited : 20|1@1+ (1,0) [0|255] "" Vector__XXX
 SG_ startup_seq_done : 21|1@1+ (1,0) [0|255] "" Vector__XXX
 SG_ RDC_ReqMode : 22|2@1+ (1,0) [0|255] "" Vector__XXX

BO_ 2566893582 Lausch_48 : 8 General_Tester
 SG_ iTEPMP_Wh1_State : 0|8@1+ (1,0) [0|255] "" Vector__XXX
 SG_ iTEPMP_Wh2_State : 8|8@1+ (1,0) [0|255] "" Vector__XXX
 SG_ iTEPMP_Press_State : 16|8@1+ (1,0) [0|255] "" Vector__XXX
 SG_ iTEPMP_ModulStatEM : 24|8@1+ (1,0) [0|255] "" Vector__XXX
 SG_ iTEPMP_CommStatus : 32|8@1+ (1,0) [0|255] "" Vector__XXX

BO_ 2566897678 Lausch_64 : 8 General_Tester
 SG_ Port2 : 0|16@1+ (1,0) [0|65535] "" Vector__XXX
 SG_ Port14 : 16|16@1+ (1,0) [0|65535] "" Vector__XXX
 SG_ Port15 : 32|16@1+ (1,0) [0|65535] "" Vector__XXX
 SG_ Port23 : 48|16@1+ (1,0) [0|65535] "" Vector__XXX

BO_ 2566897934 Lausch_65 : 8 General_Tester
 SG_ STAT_A_P4221 : 0|16@1+ (1,0) [0|65535] "" Vector__XXX
 SG_ STAT_A_P2201 : 16|16@1+ (1,0) [0|65535] "" Vector__XXX
 SG_ STAT_A_P4 : 32|16@1+ (1,0) [0|65535] "" Vector__XXX
 SG_ STAT_A_TRI_IN : 48|16@1+ (1,0) [0|65535] "" Vector__XXX

BO_ 2566898190 Lausch_66 : 8 General_Tester
 SG_ STAT_A_US1 : 0|16@1+ (1,0) [0|65535] "" Vector__XXX
 SG_ STAT_A_UBAT : 16|16@1+ (1,0) [0|65535] "" Vector__XXX
 SG_ STAT_A_UBL : 32|16@1+ (1,0) [0|65535] "" Vector__XXX
 SG_ STAT_A_UPS : 48|16@1+ (1,0) [0|65535] "" Vector__XXX

BO_ 2566898446 Lausch_67 : 8 General_Tester
 SG_ STAT_A_ECU_HW_CODE : 0|16@1+ (1,0) [0|65535] "" Vector__XXX
 SG_ STAT_A_I_P2XRET : 16|16@1+ (1,0) [0|65535] "" Vector__XXX
 SG_ STAT_A_I_AUX : 32|16@1+ (1,0) [0|65535] "" Vector__XXX
 SG_ STAT_A_VAR : 48|16@1+ (1,0) [0|65535] "" Vector__XXX

BO_ 2566898702 Lausch_68 : 8 General_Tester
 SG_ STAT_A_WSS_SC : 0|16@1+ (1,0) [0|65535] "" Vector__XXX
 SG_ STAT_A_WSS_SD : 16|16@1+ (1,0) [0|65535] "" Vector__XXX
 SG_ STAT_A_WSS_SE : 32|16@1+ (1,0) [0|65535] "" Vector__XXX
 SG_ STAT_A_WSS_SF : 48|16@1+ (1,0) [0|65535] "" Vector__XXX

BO_ 2566898958 Lausch_69 : 8 General_Tester
 SG_ STAT_A_AUX1 : 0|16@1+ (1,0) [0|65535] "" Vector__XXX
 SG_ STAT_A_AUX2 : 16|16@1+ (1,0) [0|65535] "" Vector__XXX
 SG_ STAT_A_AUX3 : 32|16@1+ (1,0) [0|65535] "" Vector__XXX
 SG_ STAT_A_AUX4 : 48|16@1+ (1,0) [0|65535] "" Vector__XXX

BO_ 2566899214 Lausch_70 : 8 General_Tester
 SG_ STAT_A_AUX5 : 0|16@1+ (1,0) [0|65535] "" Vector__XXX
 SG_ STAT_A_SENS_SUP : 16|16@1+ (1,0) [0|65535] "" Vector__XXX
 SG_ STAT_A_SENS_IN : 32|16@1+ (1,0) [0|65535] "" Vector__XXX
 SG_ STAT_A_GND_H : 48|16@1+ (1,0) [0|65535] "" Vector__XXX

BO_ 2566899470 Lausch_71 : 8 General_Tester
 SG_ SC_v : 0|16@1- (1,0) [-32768|32767] "2mm/s" Vector__XXX
 SG_ SD_v : 16|16@1- (1,0) [-32768|32767] "2mm/s" Vector__XXX
 SG_ Port22 : 32|16@1+ (1,0) [0|65535] "" Vector__XXX
 SG_ Port0 : 48|16@1+ (1,0) [0|65535] "" Vector__XXX

BO_ 2566899726 Lausch_72 : 8 General_Tester
 SG_ ADL_Register1 : 0|16@1+ (1,0) [0|65535] "" Vector__XXX
 SG_ ADL_Register2 : 16|16@1+ (1,0) [0|65535] "" Vector__XXX
 SG_ ADL_Register3 : 32|16@1+ (1,0) [0|65535] "" Vector__XXX
 SG_ ADL_Register4 : 48|16@1+ (1,0) [0|65535] "" Vector__XXX

BO_ 2566899982 Lausch_73 : 8 General_Tester
 SG_ RUNTIME_CPU_LOAD : 0|8@1+ (1,0) [0|255] "%" Vector__XXX
 SG_ RUNTIME_APP_ASIL_B_BASIC_1MS : 8|8@1+ (1,0) [0|255] "%" Vector__XXX
 SG_ RUNTIME_APP_ASIL_B_BASIC_10MS : 16|8@1+ (1,0) [0|255] "%" Vector__XXX
 SG_ RUNTIME_OS_ASIL_B_BASIC_10MS : 24|8@1+ (1,0) [0|255] "%" Vector__XXX
 SG_ RUNTIME_OS_ASIL_B_EXT_10MS : 32|8@1+ (1,0) [0|255] "%" Vector__XXX
 SG_ RUNTIME_APP_ASIL_QM_BASIC_1MS : 40|8@1+ (1,0) [0|255] "%" Vector__XXX
 SG_ RUNTIME_APP_ASIL_QM_BASIC_10MS : 48|8@1+ (1,0) [0|255] "%" Vector__XXX

BO_ 2566900238 Lausch_74 : 8 General_Tester
 SG_ RUNTIME_APP_ASIL_QM_BASIC_20MS : 0|8@1+ (1,0) [0|255] "%" Vector__XXX
 SG_ RUNTIME_APP_ASIL_QM_BASIC_50MS : 8|8@1+ (1,0) [0|255] "%" Vector__XXX
 SG_ RUNTIME_APP_ASIL_QM_EXT_10MS : 16|8@1+ (1,0) [0|255] "%" Vector__XXX
 SG_ RUNTIME_BSW_TASK_10MS : 24|8@1+ (1,0) [0|255] "%" Vector__XXX
 SG_ RUNTIME_BSW_TASK_20MS : 32|8@1+ (1,0) [0|255] "%" Vector__XXX
 SG_ RUNTIME_CANISR_1 : 40|8@1+ (1,0) [0|255] "" Vector__XXX
 SG_ RUNTIME_CANISR_9 : 48|8@1+ (1,0) [0|255] "" Vector__XXX
 SG_ RUNTIME_NVM_READ_ALL : 56|8@1+ (1,0) [0|255] "ms" Vector__XXX

BO_ 2566900494 Lausch_75 : 8 General_Tester
 SG_ RUNTIME_GTMTIM0SR1_ISR : 0|8@1+ (1,0) [0|255] "" Vector__XXX
 SG_ RUNTIME_GTMTIM0SR2_ISR : 8|8@1+ (1,0) [0|255] "" Vector__XXX
 SG_ RUNTIME_GTMTIM0SR3_ISR : 16|8@1+ (1,0) [0|255] "" Vector__XXX
 SG_ RUNTIME_GTMTIM0SR4_ISR : 24|8@1+ (1,0) [0|255] "" Vector__XXX
 SG_ RUNTIME_GTMTOM0SR1_ISR : 32|8@1+ (1,0) [0|255] "" Vector__XXX
 SG_ RUNTIME_GTMTOM0SR2_ISR : 40|8@1+ (1,0) [0|255] "" Vector__XXX
 SG_ RUNTIME_GTMTOM0SR3_ISR : 48|8@1+ (1,0) [0|255] "" Vector__XXX
 SG_ RUNTIME_GTMTOM0SR4_ISR : 56|8@1+ (1,0) [0|255] "" Vector__XXX

BO_ 2566900750 Lausch_76 : 8 General_Tester
 SG_ ADL_Register5 : 0|16@1+ (1,0) [0|65535] "" Vector__XXX
 SG_ ADL_Register6 : 16|16@1+ (1,0) [0|65535] "" Vector__XXX
 SG_ ADL_Register7 : 32|16@1+ (1,0) [0|65535] "" Vector__XXX
 SG_ ADL_Register8 : 48|16@1+ (1,0) [0|65535] "" Vector__XXX

BO_ 2566901006 Lausch_77 : 8 General_Tester
 SG_ ADL_Register9 : 0|16@1+ (1,0) [0|65535] "" Vector__XXX
 SG_ ADL_Register10 : 16|16@1+ (1,0) [0|65535] "" Vector__XXX
 SG_ ADL_Register11 : 32|16@1+ (1,0) [0|65535] "" Vector__XXX
 SG_ ADL_Register12 : 48|16@1+ (1,0) [0|65535] "" Vector__XXX

BO_ 2566901262 Lausch_78 : 8 General_Tester
 SG_ ADL_Register13 : 0|16@1+ (1,0) [0|65535] "" Vector__XXX
 SG_ ADL_Register14 : 16|16@1+ (1,0) [0|65535] "" Vector__XXX
 SG_ ADL_Register15 : 32|16@1+ (1,0) [0|65535] "" Vector__XXX
 SG_ ADL_Register16 : 48|16@1+ (1,0) [0|65535] "" Vector__XXX

BO_ 2566901518 Lausch_79 : 8 General_Tester
 SG_ LdSensModeOffTimer : 0|16@1+ (1,0) [0|65535] "" Vector__XXX
 SG_ LdSensModeOnTimer : 16|8@1+ (1,0) [0|255] "" Vector__XXX
 SG_ NoLadenLineCnt : 24|8@1+ (1,0) [0|255] "" Vector__XXX
 SG_ No_NoBrkAsscnt : 32|8@1+ (1,0) [0|255] "" Vector__XXX
 SG_ HandBrkOnTimer : 40|8@1+ (1,0) [0|255] "" Vector__XXX
 SG_ EBSmChufftestActive : 48|1@1+ (1,0) [0|255] "" Vector__XXX

BO_ 2566901774 Lausch_80 : 8 General_Tester
 SG_ FaultActiveStatus_Byte0_0To15 : 0|16@1+ (1,0) [0|65535] "bits" Vector__XXX
 SG_ FaultActiveStatus_Byte0_16To31 : 16|16@1+ (1,0) [0|65535] "bits" Vector__XXX
 SG_ FaultActiveStatus_Byte1_0To15 : 32|16@1+ (1,0) [0|65535] "bits" Vector__XXX
 SG_ FaultActiveStatus_Byte1_16To31 : 48|16@1+ (1,0) [0|65535] "bits" Vector__XXX

BO_ 2566902030 Lausch_81 : 8 General_Tester
 SG_ FaultActiveStatus_Byte2_0To15 : 0|16@1+ (1,0) [0|65535] "bits" Vector__XXX
 SG_ FaultActiveStatus_Byte2_16To31 : 16|16@1+ (1,0) [0|65535] "bits" Vector__XXX
 SG_ FaultActiveStatus_Byte3_0To15 : 32|16@1+ (1,0) [0|65535] "bits" Vector__XXX
 SG_ FaultActiveStatus_Byte3_16To31 : 48|16@1+ (1,0) [0|65535] "bits" Vector__XXX

BO_ 2566902286 Lausch_82 : 8 General_Tester
 SG_ FaultActiveStatus_Byte4_0To15 : 0|16@1+ (1,0) [0|65535] "bits" Vector__XXX
 SG_ FaultActiveStatus_Byte4_16To31 : 16|16@1+ (1,0) [0|65535] "bits" Vector__XXX
 SG_ FaultActivestatus_Byte5_0To15 : 32|16@1+ (1,0) [0|65535] "bits" Vector__XXX
 SG_ FaultActiveStatus_Byte5_16To31 : 48|16@1+ (1,0) [0|65535] "bits" Vector__XXX

BO_ 2566902542 Lausch_83 : 8 General_Tester
 SG_ FaultActiveStatus_Byte6_0To15 : 0|16@1+ (1,0) [0|65535] "bits" Vector__XXX
 SG_ FaultActiveStatus_Byte6_16To31 : 16|16@1+ (1,0) [0|65535] "bits" Vector__XXX

BO_ 2566902798 Lausch_84 : 8 General_Tester
 SG_ APP_ASIL_B_BASIC_1MS_STACK : 0|8@1+ (1,0) [0|255] "%" Vector__XXX
 SG_ APP_ASIL_B_BASIC_10MS_STACK : 8|8@1+ (1,0) [0|255] "%" Vector__XXX
 SG_ APP_ASIL_QM_BASIC_1MS_STACK : 16|8@1+ (1,0) [0|255] "%" Vector__XXX
 SG_ APP_ASIL_QM_BASIC_10MS_STACK : 24|8@1+ (1,0) [0|255] "%" Vector__XXX
 SG_ APP_ASIL_QM_BASIC_20MS_STACK : 32|8@1+ (1,0) [0|255] "%" Vector__XXX
 SG_ APP_ASIL_QM_BASIC_50MS_STACK : 40|8@1+ (1,0) [0|255] "%" Vector__XXX

BO_ 2566903054 Lausch_85 : 8 General_Tester
 SG_ Port11 : 0|16@1+ (1,0) [0|65535] "" Vector__XXX
 SG_ Port20 : 16|16@1+ (1,0) [0|65535] "" Vector__XXX
 SG_ Port21 : 32|16@1+ (1,0) [0|65535] "" Vector__XXX
 SG_ Port33 : 48|16@1+ (1,0) [0|65535] "" Vector__XXX

BO_ 2566903310 Lausch_86 : 8 General_Tester
 SG_ Port10 : 0|16@1+ (1,0) [0|65535] "" Vector__XXX
 SG_ Port34 : 16|16@1+ (1,0) [0|65535] "" Vector__XXX

BO_ 2566903566 Lausch_87 : 8 General_Tester
 SG_ EMC_EEP_COUNTER_H : 0|16@1+ (1,0) [0|65535] "" Vector__XXX
 SG_ EMC_EEP_COUNTER_L : 16|16@1+ (1,0) [0|65535] "" Vector__XXX
 SG_ EMC_EEP_ERR_COUNTER : 32|8@1+ (1,0) [0|255] "" Vector__XXX
 SG_ EMC_EEP_TIMER : 40|8@1+ (1,0) [0|255] "" Vector__XXX
 SG_ EMC_EEP_STATEM : 48|8@1+ (1,0) [0|255] "" Vector__XXX
 SG_ TT_CAN_EBS11TOCtr : 56|8@1+ (1,0) [0|255] "" Vector__XXX

BO_ 2566903822 Lausch_88 : 8 General_Tester
 SG_ EMC_sfCxIo_Status : 0|8@1+ (1,0) [0|255] "" Vector__XXX
 SG_ EMC_sfCxIo_InhibitState : 8|8@1+ (1,0) [0|255] "" Vector__XXX
 SG_ EMC_sfACCh_Status : 16|8@1+ (1,0) [0|255] "" Vector__XXX
 SG_ EMC_QmMain_WriteStatus : 24|8@1+ (1,0) [0|255] "" Vector__XXX
 SG_ EMC_SfSignal_ReadStatus : 32|8@1+ (1,0) [0|255] "" Vector__XXX
 SG_ EMC_SfMain_ReadStatus : 40|8@1+ (1,0) [0|255] "" Vector__XXX
 SG_ EMC_DTC_AddInfo : 48|16@1+ (1,0) [0|65535] "" Vector__XXX

BO_ 2566904078 Lausch_89 : 8 General_Tester
 SG_ VEH_InpVtgVal : 0|16@1- (1,0) [-32768|32767] "" Vector__XXX
 SG_ VEH_BrkAstPdem : 16|16@1- (1,0) [-32768|32767] "" Vector__XXX
 SG_ VEH_EbsPdesLo : 32|16@1- (1,0) [-32768|32767] "" Vector__XXX
 SG_ VEH_EbsPdesHi : 48|16@1- (1,0) [-32768|32767] "" Vector__XXX

BO_ 2566904334 Lausch_90 : 8 General_Tester
 SG_ VEH_LowVtgErrCtr : 0|8@1+ (1,0) [0|255] "" Vector__XXX
 SG_ VEH_HighVtgErrCtr : 8|8@1+ (1,0) [0|255] "" Vector__XXX
 SG_ VEH_BrkAstErrCtr : 16|8@1+ (1,0) [0|255] "" Vector__XXX
 SG_ VEH_EbsDemErrCtr : 24|8@1+ (1,0) [0|255] "" Vector__XXX

BO_ 2566904590 Lausch_91 : 8 General_Tester
 SG_ P1_p : 0|16@1- (1,0) [-32768|32767] "mbar" Vector__XXX
 SG_ P1_Filt_p : 16|16@1- (1,0) [-32768|32767] "mbar" Vector__XXX
 SG_ P1_Virt_p : 32|16@1- (1,0) [-32768|32767] "mbar" Vector__XXX
 SG_ P1_Virt_t : 48|16@1+ (1,0) [0|65535] "ms" Vector__XXX

BO_ 2566904846 Lausch_92 : 8 General_Tester
 SG_ SensIn_GetVal : 0|16@1- (1,0) [-32768|32767] "mV" Vector__XXX
 SG_ SensSp_GetVal : 16|16@1- (1,0) [-32768|32767] "" Vector__XXX
 SG_ SensIn_RawUnd : 32|16@1+ (1,0) [0|65535] "" Vector__XXX
 SG_ SensIn_XitSt : 48|8@1+ (1,0) [0|255] "" Vector__XXX

BO_ 2566905102 Lausch_93 : 8 General_Tester
 SG_ P42NotAvailCtr : 0|16@1- (1,0) [-32768|32767] "" Vector__XXX
 SG_ LC1LiftingProgressState : 16|16@1+ (1,0) [0|65535] "" Vector__XXX
 SG_ LC2LiftingProgressState : 32|16@1+ (1,0) [0|65535] "" Vector__XXX
 SG_ P42ELCMuxPrio : 48|8@1+ (1,0) [0|255] "" Vector__XXX
 SG_ P42_PostLiftingMeasDone : 56|1@1+ (1,0) [0|255] "" Vector__XXX
 SG_ P42_PreIdleMeasNeeded : 57|1@1+ (1,0) [0|255] "" Vector__XXX
 SG_ Rear_LiftingInProgress : 58|1@1+ (1,0) [0|255] "" Vector__XXX
 SG_ Rear_LoweringInProgress : 59|1@1+ (1,0) [0|255] "" Vector__XXX
 SG_ Rear_ExpectingPneuBackup : 60|1@1+ (1,0) [0|255] "" Vector__XXX
 SG_ Rear_ExpectingLoadChange : 61|1@1+ (1,0) [0|255] "" Vector__XXX
 SG_ EMP42_PostLiftingMeasDone : 62|1@1+ (1,0) [0|255] "" Vector__XXX
 SG_ EMP42_PreIdleMeasNeeded : 63|1@1+ (1,0) [0|255] "" Vector__XXX

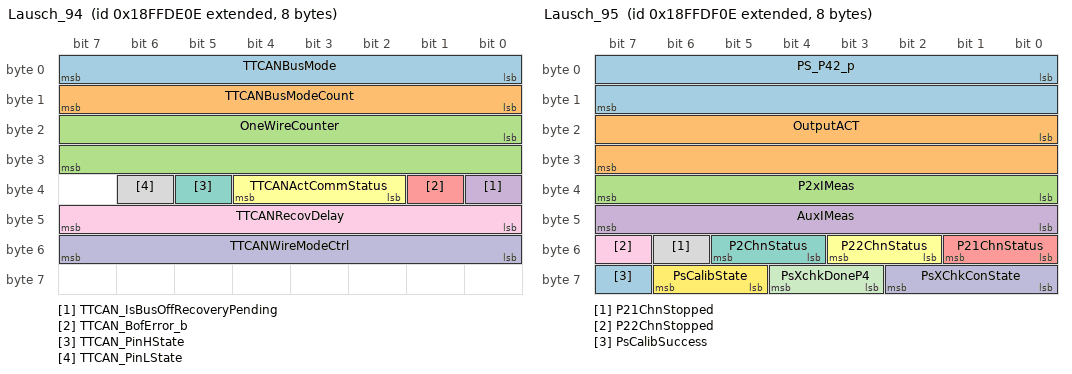
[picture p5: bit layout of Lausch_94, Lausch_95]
BO_ 2566905358 Lausch_94 : 8 General_Tester
 SG_ TTCANBusMode : 0|8@1+ (1,0) [0|255] "" Vector__XXX
 SG_ TTCANBusModeCount : 8|8@1+ (1,0) [0|255] "" Vector__XXX
 SG_ OneWireCounter : 16|16@1+ (1,0) [0|65535] "" Vector__XXX
 SG_ TTCAN_IsBusOffRecoveryPending : 32|1@1+ (1,0) [0|255] "" Vector__XXX
 SG_ TTCAN_BofError_b : 33|1@1+ (1,0) [0|255] "" Vector__XXX
 SG_ TTCANActCommStatus : 34|3@1+ (1,0) [0|255] "" Vector__XXX
 SG_ TTCAN_PinHState : 37|1@1+ (1,0) [0|255] "" Vector__XXX
 SG_ TTCAN_PinLState : 38|1@1+ (1,0) [0|255] "" Vector__XXX
 SG_ TTCANRecovDelay : 40|8@1+ (1,0) [0|255] "" Vector__XXX
 SG_ TTCANWireModeCtrl : 48|8@1+ (1,0) [0|255] "" Vector__XXX

BO_ 2566905614 Lausch_95 : 8 General_Tester
 SG_ PS_P42_p : 0|16@1- (1,0) [-32768|32767] "mbar" Vector__XXX
 SG_ OutputACT : 16|16@1+ (1,0) [0|65535] "" Vector__XXX
 SG_ P2xIMeas : 32|8@1+ (100,0) [0|255] "mA" Vector__XXX
 SG_ AuxIMeas : 40|8@1+ (100,0) [0|255] "mA" Vector__XXX
 SG_ P21ChnStatus : 48|2@1+ (1,0) [0|255] "" Vector__XXX
 SG_ P22ChnStatus : 50|2@1+ (1,0) [0|255] "" Vector__XXX
 SG_ P2ChnStatus : 52|2@1+ (1,0) [0|255] "" Vector__XXX
 SG_ P21ChnStopped : 54|1@1+ (1,0) [0|255] "" Vector__XXX
 SG_ P22ChnStopped : 55|1@1+ (1,0) [0|255] "" Vector__XXX
 SG_ PsXChkConState : 56|3@1+ (1,0) [0|255] "" Vector__XXX
 SG_ PsXchkDoneP4 : 59|2@1+ (1,0) [0|255] "" Vector__XXX
 SG_ PsCalibState : 61|2@1+ (1,0) [0|255] "" Vector__XXX
 SG_ PsCalibSuccess : 63|1@1+ (1,0) [0|255] "" Vector__XXX

BO_ 2564426728 UDSrequest :8 OffboardUDS
 SG_ UDSbyte1_UDSrequest : 0|8@1+ (1,0) [0|255] "" Central
 SG_ UDSbyte2_UDSrequest : 8|8@1+ (1,0) [0|255] "" Central
 SG_ UDSbyte3_UDSrequest : 16|8@1+ (1,0) [0|255] "" Central
 SG_ UDSbyte4_UDSrequest : 24|8@1+ (1,0) [0|255] "" Central
 SG_ UDSbyte5_UDSrequest : 32|8@1+ (1,0) [0|255] "" Central
 SG_ UDSbyte6_UDSrequest : 40|8@1+ (1,0) [0|255] "" Central
 SG_ UDSbyte7_UDSrequest : 48|8@1+ (1,0) [0|255] "" Central
 SG_ UDSbyte8_UDSrequest : 56|8@1+ (1,0) [0|255] "" Central

BO_ 2564426747 UDSrequest_TIM :8 TIM
 SG_ UDSbyte1_UDSrequest_TIM : 0|8@1+ (1,0) [0|255] "" Central
 SG_ UDSbyte2_UDSrequest_TIM : 8|8@1+ (1,0) [0|255] "" Central
 SG_ UDSbyte3_UDSrequest_TIM : 16|8@1+ (1,0) [0|255] "" Central
 SG_ UDSbyte4_UDSrequest_TIM : 24|8@1+ (1,0) [0|255] "" Central
 SG_ UDSbyte5_UDSrequest_TIM : 32|8@1+ (1,0) [0|255] "" Central
 SG_ UDSbyte6_UDSrequest_TIM : 40|8@1+ (1,0) [0|255] "" Central
 SG_ UDSbyte7_UDSrequest_TIM : 48|8@1+ (1,0) [0|255] "" Central
 SG_ UDSbyte8_UDSrequest_TIM : 56|8@1+ (1,0) [0|255] "" Central

BO_ 2631535509 UDSrequest_J1939_CTU :8 CTU
 SG_ UDSbyte1_UDSrequest_J1939_CTU : 0|8@1+ (1,0) [0|255] "" Central
 SG_ UDSbyte2_UDSrequest_J1939_CTU : 8|8@1+ (1,0) [0|255] "" Central
 SG_ UDSbyte3_UDSrequest_J1939_CTU : 16|8@1+ (1,0) [0|255] "" Central
 SG_ UDSbyte4_UDSrequest_J1939_CTU : 24|8@1+ (1,0) [0|255] "" Central
 SG_ UDSbyte5_UDSrequest_J1939_CTU : 32|8@1+ (1,0) [0|255] "" Central
 SG_ UDSbyte6_UDSrequest_J1939_CTU : 40|8@1+ (1,0) [0|255] "" Central
 SG_ UDSbyte7_UDSrequest_J1939_CTU : 48|8@1+ (1,0) [0|255] "" Central
 SG_ UDSbyte8_UDSrequest_J1939_CTU : 56|8@1+ (1,0) [0|255] "" Central

BO_ 2564483083 UDSanswer :8 Central
 SG_ UDSbyte1_UDSanswer : 0|8@1+ (1,0) [0|255] "" OffboardUDS
 SG_ UDSbyte2_UDSanswer : 8|8@1+ (1,0) [0|255] "" OffboardUDS
 SG_ UDSbyte3_UDSanswer : 16|8@1+ (1,0) [0|255] "" OffboardUDS
 SG_ UDSbyte4_UDSanswer : 24|8@1+ (1,0) [0|255] "" OffboardUDS
 SG_ UDSbyte5_UDSanswer : 32|8@1+ (1,0) [0|255] "" OffboardUDS
 SG_ UDSbyte6_UDSanswer : 40|8@1+ (1,0) [0|255] "" OffboardUDS
 SG_ UDSbyte7_UDSanswer : 48|8@1+ (1,0) [0|255] "" OffboardUDS
 SG_ UDSbyte8_UDSanswer : 56|8@1+ (1,0) [0|255] "" OffboardUDS

BO_ 2564487947 UDSanswer_TIM :8 Central
 SG_ UDSbyte1_UDSanswer_TIM : 0|8@1+ (1,0) [0|255] "" TIM
 SG_ UDSbyte2_UDSanswer_TIM : 8|8@1+ (1,0) [0|255] "" TIM
 SG_ UDSbyte3_UDSanswer_TIM : 16|8@1+ (1,0) [0|255] "" TIM
 SG_ UDSbyte4_UDSanswer_TIM : 24|8@1+ (1,0) [0|255] "" TIM
 SG_ UDSbyte5_UDSanswer_TIM : 32|8@1+ (1,0) [0|255] "" TIM
 SG_ UDSbyte6_UDSanswer_TIM : 40|8@1+ (1,0) [0|255] "" TIM
 SG_ UDSbyte7_UDSanswer_TIM : 48|8@1+ (1,0) [0|255] "" TIM
 SG_ UDSbyte8_UDSanswer_TIM : 56|8@1+ (1,0) [0|255] "" TIM

BO_ 2631570699 UDSanswer_J1939_CTU :8 Central
 SG_ UDSbyte1_UDSanswer_J1939_CTU : 0|8@1+ (1,0) [0|255] "" CTU
 SG_ UDSbyte2_UDSanswer_J1939_CTU : 8|8@1+ (1,0) [0|255] "" CTU
 SG_ UDSbyte3_UDSanswer_J1939_CTU : 16|8@1+ (1,0) [0|255] "" CTU
 SG_ UDSbyte4_UDSanswer_J1939_CTU : 24|8@1+ (1,0) [0|255] "" CTU
 SG_ UDSbyte5_UDSanswer_J1939_CTU : 32|8@1+ (1,0) [0|255] "" CTU
 SG_ UDSbyte6_UDSanswer_J1939_CTU : 40|8@1+ (1,0) [0|255] "" CTU
 SG_ UDSbyte7_UDSanswer_J1939_CTU : 48|8@1+ (1,0) [0|255] "" CTU
 SG_ UDSbyte8_UDSanswer_J1939_CTU : 56|8@1+ (1,0) [0|255] "" CTU

BO_ 2559314938 XCP_Cmd1 :8 OffboardUDS
 SG_ XCPCmdB1_XCP_Cmd1 : 0|8@1+ (1,0) [0|255] "" Central
 SG_ XCPCmdB2_XCP_Cmd1 : 8|8@1+ (1,0) [0|255] "" Central
 SG_ XCPCmdB3_XCP_Cmd1 : 16|8@1+ (1,0) [0|255] "" Central
 SG_ XCPCmdB4_XCP_Cmd1 : 24|8@1+ (1,0) [0|255] "" Central
 SG_ XCPCmdB5_XCP_Cmd1 : 32|8@1+ (1,0) [0|255] "" Central
 SG_ XCPCmdB6_XCP_Cmd1 : 40|8@1+ (1,0) [0|255] "" Central
 SG_ XCPCmdB7_XCP_Cmd1 : 48|8@1+ (1,0) [0|255] "" Central
 SG_ XCPCmdB8_XCP_Cmd1 : 56|8@1+ (1,0) [0|255] "" Central

BO_ 2559310347 XCP_Rsp1 :8 Central
 SG_ XCPRspB1_XCP_Rsp1 : 0|8@1+ (1,0) [0|255] "" OffboardUDS
 SG_ XCPRspB2_XCP_Rsp1 : 8|8@1+ (1,0) [0|255] "" OffboardUDS
 SG_ XCPRspB3_XCP_Rsp1 : 16|8@1+ (1,0) [0|255] "" OffboardUDS
 SG_ XCPRspB4_XCP_Rsp1 : 24|8@1+ (1,0) [0|255] "" OffboardUDS
 SG_ XCPRspB5_XCP_Rsp1 : 32|8@1+ (1,0) [0|255] "" OffboardUDS
 SG_ XCPRspB6_XCP_Rsp1 : 40|8@1+ (1,0) [0|255] "" OffboardUDS
 SG_ XCPRspB7_XCP_Rsp1 : 48|8@1+ (1,0) [0|255] "" OffboardUDS
 SG_ XCPRspB8_XCP_Rsp1 : 56|8@1+ (1,0) [0|255] "" OffboardUDS

BO_ 1792 PlantRequest :8 Simulator
 SG_ PlantCloseLoop : 0|1@1+ (1,0) [0|1] "" Central
 SG_ PlantEBSmode : 1|1@1+ (1,0) [0|1] "" Central
 SG_ PlantCommon : 2|1@1+ (1,0) [0|1] "" Central
 SG_ PlantNoStimuli : 3|1@1+ (1,0) [0|1] "" Central
 SG_ PlantNoOffset : 4|1@1+ (1,0) [0|1] "" Central
 SG_ PlantReset : 5|1@1+ (1,0) [0|1] "" Central
 SG_ PlantNoProcess : 6|1@1+ (1,0) [0|1] "" Central
 SG_ PlantActive : 7|1@1+ (1,0) [0|1] "" Central
 SG_ PlantOutputId : 8|4@1+ (1,0) [0|15] "" Central
 SG_ PlantLowTimeRes : 12|1@1+ (1,0) [0|1] "" Central
 SG_ PlantSwitchSlow : 13|1@1+ (1,0) [0|1] "" Central
 SG_ PlantState : 14|1@1+ (1,0) [0|1] "" Central
 SG_ PlantTrigger : 15|1@1+ (1,0) [0|1] "" Central
 SG_ PlantNofPulses : 16|8@1+ (1,0) [0|255] "" Central
 SG_ PlantControlTime : 24|16@1+ (1,0) [0|65535] "" Central
 SG_ PlantPauseTime : 40|8@1+ (1,0) [0|255] "" Central
 SG_ PlantTargetPres : 48|16@1+ (1,0) [0|65535] "" Central

BO_ 1793 PressSim :8 Simulator
 SG_ AccYSim : 0|12@1- (5,0) [-10240|10235] "mm/s2"  Central
 SG_ P21Sim : 12|12@1+ (4,0) [0|16380] "mbar" Central
 SG_ P22Sim : 24|12@1+ (4,0) [0|16380] "mbar" Central
 SG_ P4Sim  : 36|12@1+ (4,0) [0|16380] "mbar" Central
 SG_ P1Sim  : 48|8@1+  (50,0) [0|255] "mbar" Central
 SG_ P42Sim : 56|8@1+  (50,0) [0|255] "mbar" Central

BO_ 1794 CANLauschConf_Rx :8 CANLogger
 SG_ ConfByte1 : 0|8@1+ (1,0) [0|255] "" Central
 SG_ ConfByte2 : 8|8@1+ (1,0) [0|255] "" Central
 SG_ ConfByte3 : 16|8@1+ (1,0) [0|255] "" Central
 SG_ ConfByte4 : 24|8@1+ (1,0) [0|255] "" Central
 SG_ ConfByte5 : 32|8@1+ (1,0) [0|255] "" Central
 SG_ ConfByte6 : 40|8@1+ (1,0) [0|255] "" Central
 SG_ ConfByte7 : 48|8@1+ (1,0) [0|255] "" Central
 SG_ ConfByte8 : 56|8@1+ (1,0) [0|255] "" Central

BO_ 0 TEPM_Command_Tx :8 Central
 SG_ PdemCh1 : 0|8@1+ (50,0) [0|255] "mbar" TEPM
 SG_ PdemCh2 : 8|8@1+ (50,0) [0|255] "mbar" TEPM
 SG_ Aux1Act : 16|1@1+ (1,0) [0|1] "" TEPM
 SG_ Aux1Cap : 17|1@1+ (1,0) [0|1] "" TEPM
 SG_ Aux1OC : 18|1@1+ (1,0) [0|1] "" TEPM
 SG_ Aux1DIn : 19|1@1+ (1,0) [0|1] "" TEPM
 SG_ Aux2Act : 20|1@1+ (1,0) [0|1] "" TEPM
 SG_ Aux2Cap : 21|1@1+ (1,0) [0|1] "" TEPM
 SG_ Aux2OC : 22|1@1+ (1,0) [0|1] "" TEPM
 SG_ Aux2DIn : 23|1@1+ (1,0) [0|1] "" TEPM
 SG_ Aux3Act : 24|1@1+ (1,0) [0|1] "" TEPM
 SG_ Aux3Cap : 25|1@1+ (1,0) [0|1] "" TEPM
 SG_ Aux3OC : 26|1@1+ (1,0) [0|1] "" TEPM
 SG_ Aux3DIn : 27|1@1+ (1,0) [0|1] "" TEPM
 SG_ Aux4Act : 28|1@1+ (1,0) [0|1] "" TEPM
 SG_ Aux4Cap : 29|1@1+ (1,0) [0|1] "" TEPM
 SG_ Aux4OC : 30|1@1+ (1,0) [0|1] "" TEPM
 SG_ Aux4DIn : 31|1@1+ (1,0) [0|1] "" TEPM
 SG_ Aux5Act : 32|1@1+ (1,0) [0|1] "" TEPM
 SG_ Aux5Cap : 33|1@1+ (1,0) [0|1] "" TEPM
 SG_ Aux5OC : 34|1@1+ (1,0) [0|1] "" TEPM
 SG_ Aux5DIn : 35|1@1+ (1,0) [0|1] "" TEPM
 SG_ Aux6Act : 36|1@1+ (1,0) [0|1] "" TEPM
 SG_ Aux6Cap : 37|1@1+ (1,0) [0|1] "" TEPM
 SG_ Aux6OC : 38|1@1+ (1,0) [0|1] "" TEPM
 SG_ Aux6DIn : 39|1@1+ (1,0) [0|1] "" TEPM
 SG_ Aux7Act : 40|1@1+ (1,0) [0|1] "" TEPM
 SG_ Aux7Cap : 41|1@1+ (1,0) [0|1] "" TEPM
 SG_ Aux7OC : 42|1@1+ (1,0) [0|1] "" TEPM
 SG_ Aux7DIn : 43|1@1+ (1,0) [0|1] "" TEPM
 SG_ Aux5PWM : 44|2@1+ (1,0) [0|3] "" TEPM
 SG_ Aux6PWM : 46|2@1+ (1,0) [0|3] "" TEPM
 SG_ Aux12PWM : 48|3@1+ (1,0) [0|7] "" TEPM
 SG_ Aux3PWM : 51|3@1+ (1,0) [0|7] "" TEPM
 SG_ Aux4PWM : 54|2@1+ (1,0) [0|3] "" TEPM
 SG_ VehStnd : 56|1@1+ (1,0) [0|1] "" TEPM
 SG_ AccStEn : 57|1@1+ (1,0) [0|1] "" TEPM
 SG_ PsOfCEn : 58|2@1+ (1,0) [0|3] "" TEPM
 SG_ SSup1Off : 60|1@1+ (1,0) [0|1] "" TEPM
 SG_ SSup2Off : 61|1@1+ (1,0) [0|1] "" TEPM
 SG_ SSup3Off : 62|1@1+ (1,0) [0|1] "" TEPM
 SG_ SSup4Off : 63|1@1+ (1,0) [0|1] "" TEPM

BO_ 272 TEPM_Wheel1_Rx :8 TEPM
 SG_ vRaw0 : 0|16@1+ (1,0) [0|65535] "1/512m/s" Central
 SG_ nEdge0 : 16|8@1+ (1,0) [0|255] "" Central
 SG_ ErrCtr0 : 24|8@1+ (1,0) [0|255] "" Central
 SG_ vRaw1 : 32|16@1+ (1,0) [0|65535] "1/512m/s" Central
 SG_ nEdge1 : 48|8@1+ (1,0) [0|255] "" Central
 SG_ ErrCtr1 : 56|8@1+ (1,0) [0|255] "" Central

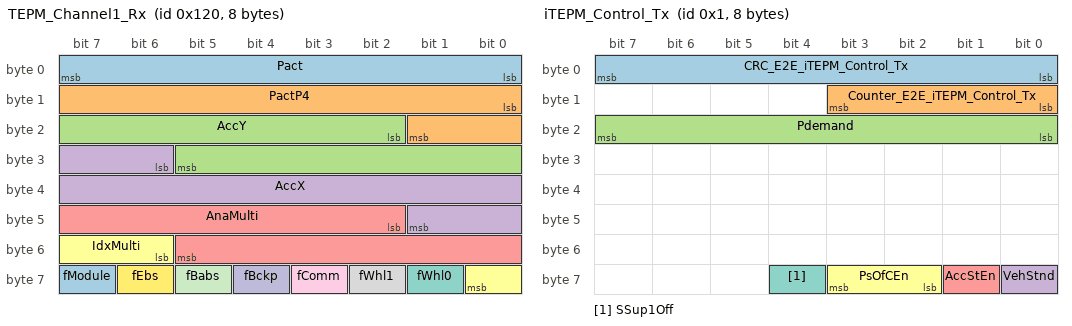
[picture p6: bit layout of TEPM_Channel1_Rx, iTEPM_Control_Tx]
BO_ 288 TEPM_Channel1_Rx :8 TEPM
 SG_ Pact : 0|8@1+ (50,0) [0|255] "mbar" Central
 SG_ PactP4 : 8|10@1+ (10,0) [0|1023] "mbar" Central
 SG_ AccY : 18|12@1+ (10,-20320) [0|4095] "mm/s2" Central
 SG_ AccX : 30|12@1+ (10,-20320) [0|4095] "mm/s2" Central
 SG_ AnaMulti : 42|12@1+ (1,0) [0|4095] "" Central
 SG_ IdxMulti : 54|3@1+ (1,0) [0|7] "" Central
 SG_ fWhl0 : 57|1@1+ (1,0) [0|1] "" Central
 SG_ fWhl1 : 58|1@1+ (1,0) [0|1] "" Central
 SG_ fComm : 59|1@1+ (1,0) [0|1] "" Central
 SG_ fBckp : 60|1@1+ (1,0) [0|1] "" Central
 SG_ fBabs : 61|1@1+ (1,0) [0|1] "" Central
 SG_ fEbs : 62|1@1+ (1,0) [0|1] "" Central
 SG_ fModule : 63|1@1+ (1,0) [0|1] "" Central

BO_ 1 iTEPM_Control_Tx :8 Central
 SG_ CRC_E2E_iTEPM_Control_Tx : 0|8@1+ (1,0) [0|255] "" iTEPM
 SG_ Counter_E2E_iTEPM_Control_Tx : 8|4@1+ (1,0) [0|15] "" iTEPM
 SG_ Pdemand : 16|8@1+ (50,0) [0|255] "mbar" iTEPM
 SG_ VehStnd : 56|1@1+ (1,0) [0|1] "" iTEPM
 SG_ AccStEn : 57|1@1+ (1,0) [0|1] "" iTEPM
 SG_ PsOfCEn : 58|2@1+ (1,0) [0|3] "" iTEPM
 SG_ SSup1Off : 60|1@1+ (1,0) [0|1] "" iTEPM

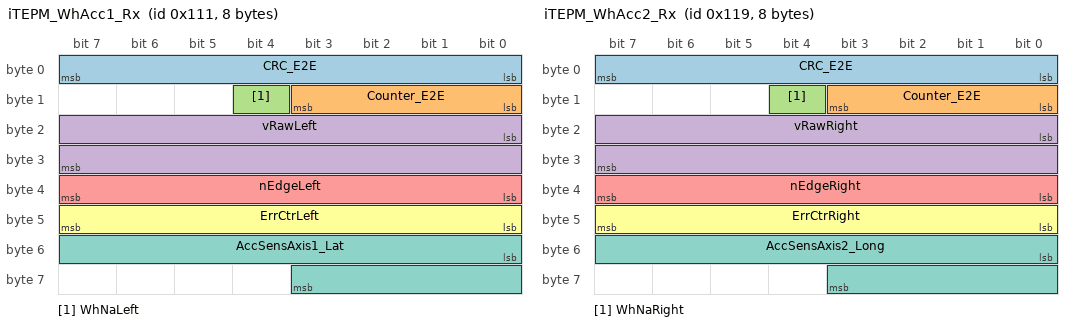
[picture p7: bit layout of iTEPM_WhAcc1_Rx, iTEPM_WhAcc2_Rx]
BO_ 273 iTEPM_WhAcc1_Rx :8 iTEPM
 SG_ CRC_E2E : 0|8@1+ (1,0) [0|255] "" Central
 SG_ Counter_E2E : 8|4@1+ (1,0) [0|15] "" Central
 SG_ WhNaLeft : 12|1@1+ (1,0) [0|1] "" Central
 SG_ vRawLeft : 16|16@1+ (1,0) [0|65535] "1/512m/s" Central
 SG_ nEdgeLeft : 32|8@1+ (1,0) [0|255] "" Central
 SG_ ErrCtrLeft : 40|8@1+ (1,0) [0|255] "" Central
 SG_ AccSensAxis1_Lat : 48|12@1+ (10,-20320) [0|4095] "mm/s2" Central

BO_ 281 iTEPM_WhAcc2_Rx :8 iTEPM
 SG_ CRC_E2E : 0|8@1+ (1,0) [0|255] "" Central
 SG_ Counter_E2E : 8|4@1+ (1,0) [0|15] "" Central
 SG_ WhNaRight : 12|1@1+ (1,0) [0|1] "" Central
 SG_ vRawRight : 16|16@1+ (1,0) [0|65535] "1/512m/s" Central
 SG_ nEdgeRight : 32|8@1+ (1,0) [0|255] "" Central
 SG_ ErrCtrRight : 40|8@1+ (1,0) [0|255] "" Central
 SG_ AccSensAxis2_Long : 48|12@1+ (10,-20320) [0|4095] "mm/s2" Central

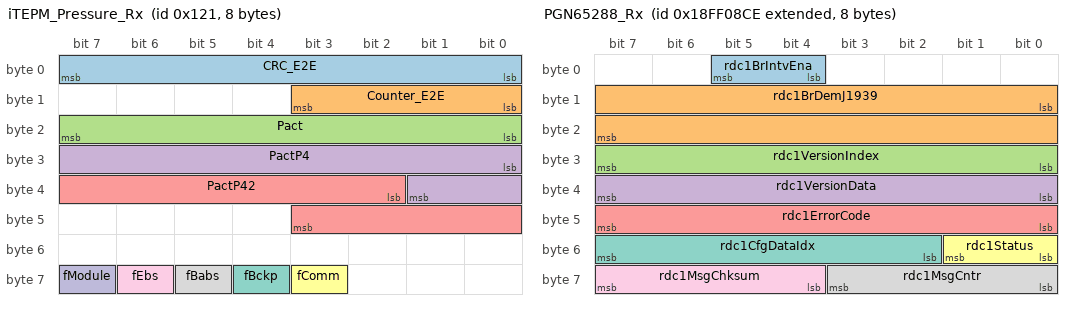
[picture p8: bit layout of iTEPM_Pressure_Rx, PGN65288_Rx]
BO_ 289 iTEPM_Pressure_Rx :8 iTEPM
 SG_ CRC_E2E : 0|8@1+ (1,0) [0|255] "" Central
 SG_ Counter_E2E : 8|4@1+ (1,0) [0|15] "" Central
 SG_ Pact : 16|8@1+ (50,0) [0|255] "mbar" Central
 SG_ PactP4 : 24|10@1+ (10,0) [0|1023] "mbar" Central
 SG_ PactP42 : 34|10@1+ (10,0) [0|1023] "mbar" Central
 SG_ fComm : 59|1@1+ (1,0) [0|1] "" Central
 SG_ fBckp : 60|1@1+ (1,0) [0|1] "" Central
 SG_ fBabs : 61|1@1+ (1,0) [0|1] "" Central
 SG_ fEbs : 62|1@1+ (1,0) [0|1] "" Central
 SG_ fModule : 63|1@1+ (1,0) [0|1] "" Central

BO_ 2566849030 PGN65282_Radar_Rx :8 Radar
 SG_ SensorLocation : 0|8@1+ (1,0) [0|255] "" Central
 SG_ DetectionZone : 8|8@1+ (1,0) [0|255] "" Central
 SG_ FunctionalStatus : 16|8@1+ (1,0) [0|255] "" Central
 SG_ ExtInputState : 24|8@1+ (1,0) [0|255] "" Central
 SG_ DetectionBinStd : 32|8@1+ (1,0) [0|255] "" Central
 SG_ SensTemperature : 40|8@1+ (1,0) [0|255] "" Central
 SG_ LongDistanceX : 48|8@1+ (304.8,0) [0|255] "mm" Central
 SG_ LatDistanceY : 56|8@1+ (304.8,0) [0|255] "mm" Central

BO_ 2566850766 PGN65288_Rx :8 RDC
 SG_ rdc1BrIntvEna : 4|2@1+ (1,0) [0|3] "" Central
 SG_ rdc1BrDemJ1939 : 8|16@1+ (1,0) [0|65535] "mbar" Central
 SG_ rdc1VersionIndex : 24|8@1+ (1,0) [0|255] "" Central
 SG_ rdc1VersionData : 32|8@1+ (1,0) [0|255] "" Central
 SG_ rdc1ErrorCode : 40|8@1+ (1,0) [0|255] "" Central
 SG_ rdc1Status : 48|2@1+ (1,0) [0|3] "" Central
 SG_ rdc1CfgDataIdx : 50|6@1+ (1,0) [0|63] "" Central
 SG_ rdc1MsgCntr : 56|4@1+ (1,0) [0|15] "" Central
 SG_ rdc1MsgChksum : 60|4@1+ (1,0) [0|15] "" Central

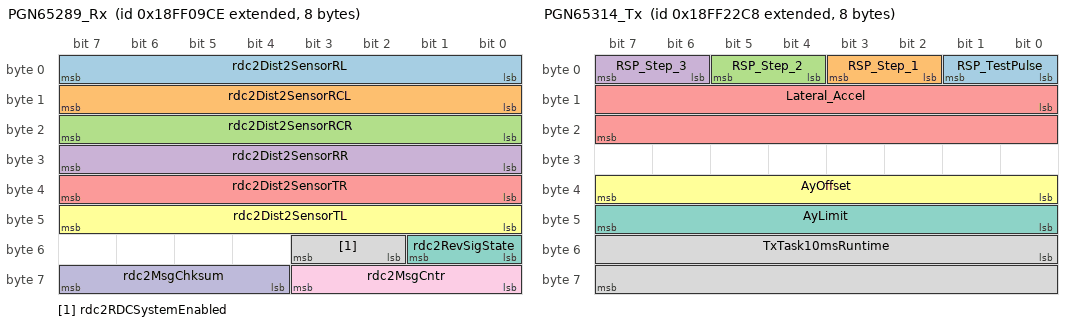
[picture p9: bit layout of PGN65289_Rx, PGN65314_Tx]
BO_ 2566851022 PGN65289_Rx :8 RDC
 SG_ rdc2Dist2SensorRL : 0|8@1+ (50,0) [0|255] "mm" Central
 SG_ rdc2Dist2SensorRCL : 8|8@1+ (50,0) [0|255] "mm" Central
 SG_ rdc2Dist2SensorRCR : 16|8@1+ (50,0) [0|255] "mm" Central
 SG_ rdc2Dist2SensorRR : 24|8@1+ (50,0) [0|255] "mm" Central
 SG_ rdc2Dist2SensorTR : 32|8@1+ (50,0) [0|255] "mm" Central
 SG_ rdc2Dist2SensorTL : 40|8@1+ (50,0) [0|255] "mm" Central
 SG_ rdc2RevSigState : 48|2@1+ (1,0) [0|3] "" Central
 SG_ rdc2RDCSystemEnabled : 50|2@1+ (1,0) [0|3] "" Central
 SG_ rdc2MsgCntr : 56|4@1+ (1,0) [0|15] "" Central
 SG_ rdc2MsgChksum : 60|4@1+ (1,0) [0|15] "" Central

BO_ 2566851016 PGN65289_Tx :8 Central
 SG_ rdc2CfgDataIdx : 2|6@1+ (1,0) [0|63] "" RDC
 SG_ rdc2CfgDataVal : 8|16@1+ (1,0) [0|65535] "" RDC
 SG_ rdc2MsgCntrTx : 56|4@1+ (1,0) [0|15] "" RDC
 SG_ rdc2MsgChksumTx : 60|4@1+ (1,0) [0|15] "" RDC

BO_ 2566851008 PGN65289_Tx_2 :8 CentralMulti
 SG_ rdc2CfgDataIdx : 2|6@1+ (1,0) [0|63] "" RDC
 SG_ rdc2CfgDataVal : 8|16@1+ (1,0) [0|65535] "" RDC
 SG_ rdc2MsgCntrTx : 56|4@1+ (1,0) [0|15] "" RDC
 SG_ rdc2MsgChksumTx : 60|4@1+ (1,0) [0|15] "" RDC

BO_ 2566851000 PGN65289_Tx_3 :8 CentralMulti
 SG_ rdc2CfgDataIdx : 2|6@1+ (1,0) [0|63] "" RDC
 SG_ rdc2CfgDataVal : 8|16@1+ (1,0) [0|65535] "" RDC
 SG_ rdc2MsgCntrTx : 56|4@1+ (1,0) [0|15] "" RDC
 SG_ rdc2MsgChksumTx : 60|4@1+ (1,0) [0|15] "" RDC

BO_ 2566850992 PGN65289_Tx_4 :8 CentralMulti
 SG_ rdc2CfgDataIdx : 2|6@1+ (1,0) [0|63] "" RDC
 SG_ rdc2CfgDataVal : 8|16@1+ (1,0) [0|65535] "" RDC
 SG_ rdc2MsgCntrTx : 56|4@1+ (1,0) [0|15] "" RDC
 SG_ rdc2MsgChksumTx : 60|4@1+ (1,0) [0|15] "" RDC

BO_ 2566850984 PGN65289_Tx_5 :8 CentralMulti
 SG_ rdc2CfgDataIdx : 2|6@1+ (1,0) [0|63] "" RDC
 SG_ rdc2CfgDataVal : 8|16@1+ (1,0) [0|65535] "" RDC
 SG_ rdc2MsgCntrTx : 56|4@1+ (1,0) [0|15] "" RDC
 SG_ rdc2MsgChksumTx : 60|4@1+ (1,0) [0|15] "" RDC

BO_ 2566850976 PGN65289_Tx_6 :8 CentralMulti
 SG_ rdc2CfgDataIdx : 2|6@1+ (1,0) [0|63] "" RDC
 SG_ rdc2CfgDataVal : 8|16@1+ (1,0) [0|65535] "" RDC
 SG_ rdc2MsgCntrTx : 56|4@1+ (1,0) [0|15] "" RDC
 SG_ rdc2MsgChksumTx : 60|4@1+ (1,0) [0|15] "" RDC

BO_ 2566850968 PGN65289_Tx_7 :8 CentralMulti
 SG_ rdc2CfgDataIdx : 2|6@1+ (1,0) [0|63] "" RDC
 SG_ rdc2CfgDataVal : 8|16@1+ (1,0) [0|65535] "" RDC
 SG_ rdc2MsgCntrTx : 56|4@1+ (1,0) [0|15] "" RDC
 SG_ rdc2MsgChksumTx : 60|4@1+ (1,0) [0|15] "" RDC

BO_ 2566850960 PGN65289_Tx_8 :8 CentralMulti
 SG_ rdc2CfgDataIdx : 2|6@1+ (1,0) [0|63] "" RDC
 SG_ rdc2CfgDataVal : 8|16@1+ (1,0) [0|65535] "" RDC
 SG_ rdc2MsgCntrTx : 56|4@1+ (1,0) [0|15] "" RDC
 SG_ rdc2MsgChksumTx : 60|4@1+ (1,0) [0|15] "" RDC

BO_ 2566850952 PGN65289_Tx_9 :8 CentralMulti
 SG_ rdc2CfgDataIdx : 2|6@1+ (1,0) [0|63] "" RDC
 SG_ rdc2CfgDataVal : 8|16@1+ (1,0) [0|65535] "" RDC
 SG_ rdc2MsgCntrTx : 56|4@1+ (1,0) [0|15] "" RDC
 SG_ rdc2MsgChksumTx : 60|4@1+ (1,0) [0|15] "" RDC

BO_ 2566850944 PGN65289_Tx_10 :8 CentralMulti
 SG_ rdc2CfgDataIdx : 2|6@1+ (1,0) [0|63] "" RDC
 SG_ rdc2CfgDataVal : 8|16@1+ (1,0) [0|65535] "" RDC
 SG_ rdc2MsgCntrTx : 56|4@1+ (1,0) [0|15] "" RDC
 SG_ rdc2MsgChksumTx : 60|4@1+ (1,0) [0|15] "" RDC

BO_ 2566851784 PGN65292_Tx :8 Central
 SG_ rdc3DisableReq : 0|2@1+ (1,0) [0|3] "" RDC
 SG_ rdc3TEBSStatus : 2|2@1+ (1,0) [0|3] "" RDC
 SG_ rdc3MsgCntr : 56|4@1+ (1,0) [0|15] "" RDC
 SG_ rdc3MsgChksum : 60|4@1+ (1,0) [0|15] "" RDC

BO_ 2566851776 PGN65292_Tx_2 :8 CentralMulti
 SG_ rdc3DisableReq : 0|2@1+ (1,0) [0|3] "" RDC
 SG_ rdc3TEBSStatus : 2|2@1+ (1,0) [0|3] "" RDC
 SG_ rdc3MsgCntr : 56|4@1+ (1,0) [0|15] "" RDC
 SG_ rdc3MsgChksum : 60|4@1+ (1,0) [0|15] "" RDC

BO_ 2566851768 PGN65292_Tx_3 :8 CentralMulti
 SG_ rdc3DisableReq : 0|2@1+ (1,0) [0|3] "" RDC
 SG_ rdc3TEBSStatus : 2|2@1+ (1,0) [0|3] "" RDC
 SG_ rdc3MsgCntr : 56|4@1+ (1,0) [0|15] "" RDC
 SG_ rdc3MsgChksum : 60|4@1+ (1,0) [0|15] "" RDC

BO_ 2566851760 PGN65292_Tx_4 :8 CentralMulti
 SG_ rdc3DisableReq : 0|2@1+ (1,0) [0|3] "" RDC
 SG_ rdc3TEBSStatus : 2|2@1+ (1,0) [0|3] "" RDC
 SG_ rdc3MsgCntr : 56|4@1+ (1,0) [0|15] "" RDC
 SG_ rdc3MsgChksum : 60|4@1+ (1,0) [0|15] "" RDC

BO_ 2566851752 PGN65292_Tx_5 :8 CentralMulti
 SG_ rdc3DisableReq : 0|2@1+ (1,0) [0|3] "" RDC
 SG_ rdc3TEBSStatus : 2|2@1+ (1,0) [0|3] "" RDC
 SG_ rdc3MsgCntr : 56|4@1+ (1,0) [0|15] "" RDC
 SG_ rdc3MsgChksum : 60|4@1+ (1,0) [0|15] "" RDC

BO_ 2566851744 PGN65292_Tx_6 :8 CentralMulti
 SG_ rdc3DisableReq : 0|2@1+ (1,0) [0|3] "" RDC
 SG_ rdc3TEBSStatus : 2|2@1+ (1,0) [0|3] "" RDC
 SG_ rdc3MsgCntr : 56|4@1+ (1,0) [0|15] "" RDC
 SG_ rdc3MsgChksum : 60|4@1+ (1,0) [0|15] "" RDC

BO_ 2566851736 PGN65292_Tx_7 :8 CentralMulti
 SG_ rdc3DisableReq : 0|2@1+ (1,0) [0|3] "" RDC
 SG_ rdc3TEBSStatus : 2|2@1+ (1,0) [0|3] "" RDC
 SG_ rdc3MsgCntr : 56|4@1+ (1,0) [0|15] "" RDC
 SG_ rdc3MsgChksum : 60|4@1+ (1,0) [0|15] "" RDC

BO_ 2566851728 PGN65292_Tx_8 :8 CentralMulti
 SG_ rdc3DisableReq : 0|2@1+ (1,0) [0|3] "" RDC
 SG_ rdc3TEBSStatus : 2|2@1+ (1,0) [0|3] "" RDC
 SG_ rdc3MsgCntr : 56|4@1+ (1,0) [0|15] "" RDC
 SG_ rdc3MsgChksum : 60|4@1+ (1,0) [0|15] "" RDC

BO_ 2566851720 PGN65292_Tx_9 :8 CentralMulti
 SG_ rdc3DisableReq : 0|2@1+ (1,0) [0|3] "" RDC
 SG_ rdc3TEBSStatus : 2|2@1+ (1,0) [0|3] "" RDC
 SG_ rdc3MsgCntr : 56|4@1+ (1,0) [0|15] "" RDC
 SG_ rdc3MsgChksum : 60|4@1+ (1,0) [0|15] "" RDC

BO_ 2566851712 PGN65292_Tx_10 :8 CentralMulti
 SG_ rdc3DisableReq : 0|2@1+ (1,0) [0|3] "" RDC
 SG_ rdc3TEBSStatus : 2|2@1+ (1,0) [0|3] "" RDC
 SG_ rdc3MsgCntr : 56|4@1+ (1,0) [0|15] "" RDC
 SG_ rdc3MsgChksum : 60|4@1+ (1,0) [0|15] "" RDC

BO_ 2566899968 PGN65481_Rx :8 ADL
 SG_ ADLRxData0 : 0|8@1+ (1,0) [0|255] "" Central
 SG_ ADLRxData1 : 8|8@1+ (1,0) [0|255] "" Central
 SG_ ADLRxData2 : 16|8@1+ (1,0) [0|255] "" Central
 SG_ ADLRxData3 : 24|8@1+ (1,0) [0|255] "" Central
 SG_ ADLRxData4 : 32|8@1+ (1,0) [0|255] "" Central
 SG_ ADLRxData5 : 40|8@1+ (1,0) [0|255] "" Central
 SG_ ADLRxData6 : 48|8@1+ (1,0) [0|255] "" Central
 SG_ ADLRxData7 : 56|8@1+ (1,0) [0|255] "" Central

BO_ 2566899912 PGN65480_Tx :8 Central
 SG_ ADLTxData0 : 0|8@1+ (1,0) [0|255] "" ADL
 SG_ ADLTxData1 : 8|8@1+ (1,0) [0|255] "" ADL
 SG_ ADLTxData2 : 16|8@1+ (1,0) [0|255] "" ADL
 SG_ ADLTxData3 : 24|8@1+ (1,0) [0|255] "" ADL
 SG_ ADLTxData4 : 32|8@1+ (1,0) [0|255] "" ADL
 SG_ ADLTxData5 : 40|8@1+ (1,0) [0|255] "" ADL
 SG_ ADLTxData6 : 48|8@1+ (1,0) [0|255] "" ADL
 SG_ ADLTxData7 : 56|8@1+ (1,0) [0|255] "" ADL

BO_ 2566899904 PGN65480_Tx_2 :8 CentralMulti
 SG_ ADLTxData0 : 0|8@1+ (1,0) [0|255] "" ADL
 SG_ ADLTxData1 : 8|8@1+ (1,0) [0|255] "" ADL
 SG_ ADLTxData2 : 16|8@1+ (1,0) [0|255] "" ADL
 SG_ ADLTxData3 : 24|8@1+ (1,0) [0|255] "" ADL
 SG_ ADLTxData4 : 32|8@1+ (1,0) [0|255] "" ADL
 SG_ ADLTxData5 : 40|8@1+ (1,0) [0|255] "" ADL
 SG_ ADLTxData6 : 48|8@1+ (1,0) [0|255] "" ADL
 SG_ ADLTxData7 : 56|8@1+ (1,0) [0|255] "" ADL

BO_ 2566899896 PGN65480_Tx_3 :8 CentralMulti
 SG_ ADLTxData0 : 0|8@1+ (1,0) [0|255] "" ADL
 SG_ ADLTxData1 : 8|8@1+ (1,0) [0|255] "" ADL
 SG_ ADLTxData2 : 16|8@1+ (1,0) [0|255] "" ADL
 SG_ ADLTxData3 : 24|8@1+ (1,0) [0|255] "" ADL
 SG_ ADLTxData4 : 32|8@1+ (1,0) [0|255] "" ADL
 SG_ ADLTxData5 : 40|8@1+ (1,0) [0|255] "" ADL
 SG_ ADLTxData6 : 48|8@1+ (1,0) [0|255] "" ADL
 SG_ ADLTxData7 : 56|8@1+ (1,0) [0|255] "" ADL

BO_ 2566899888 PGN65480_Tx_4 :8 CentralMulti
 SG_ ADLTxData0 : 0|8@1+ (1,0) [0|255] "" ADL
 SG_ ADLTxData1 : 8|8@1+ (1,0) [0|255] "" ADL
 SG_ ADLTxData2 : 16|8@1+ (1,0) [0|255] "" ADL
 SG_ ADLTxData3 : 24|8@1+ (1,0) [0|255] "" ADL
 SG_ ADLTxData4 : 32|8@1+ (1,0) [0|255] "" ADL
 SG_ ADLTxData5 : 40|8@1+ (1,0) [0|255] "" ADL
 SG_ ADLTxData6 : 48|8@1+ (1,0) [0|255] "" ADL
 SG_ ADLTxData7 : 56|8@1+ (1,0) [0|255] "" ADL

BO_ 2566899880 PGN65480_Tx_5 :8 CentralMulti
 SG_ ADLTxData0 : 0|8@1+ (1,0) [0|255] "" ADL
 SG_ ADLTxData1 : 8|8@1+ (1,0) [0|255] "" ADL
 SG_ ADLTxData2 : 16|8@1+ (1,0) [0|255] "" ADL
 SG_ ADLTxData3 : 24|8@1+ (1,0) [0|255] "" ADL
 SG_ ADLTxData4 : 32|8@1+ (1,0) [0|255] "" ADL
 SG_ ADLTxData5 : 40|8@1+ (1,0) [0|255] "" ADL
 SG_ ADLTxData6 : 48|8@1+ (1,0) [0|255] "" ADL
 SG_ ADLTxData7 : 56|8@1+ (1,0) [0|255] "" ADL

BO_ 2566899872 PGN65480_Tx_6 :8 CentralMulti
 SG_ ADLTxData0 : 0|8@1+ (1,0) [0|255] "" ADL
 SG_ ADLTxData1 : 8|8@1+ (1,0) [0|255] "" ADL
 SG_ ADLTxData2 : 16|8@1+ (1,0) [0|255] "" ADL
 SG_ ADLTxData3 : 24|8@1+ (1,0) [0|255] "" ADL
 SG_ ADLTxData4 : 32|8@1+ (1,0) [0|255] "" ADL
 SG_ ADLTxData5 : 40|8@1+ (1,0) [0|255] "" ADL
 SG_ ADLTxData6 : 48|8@1+ (1,0) [0|255] "" ADL
 SG_ ADLTxData7 : 56|8@1+ (1,0) [0|255] "" ADL

BO_ 2566899864 PGN65480_Tx_7 :8 CentralMulti
 SG_ ADLTxData0 : 0|8@1+ (1,0) [0|255] "" ADL
 SG_ ADLTxData1 : 8|8@1+ (1,0) [0|255] "" ADL
 SG_ ADLTxData2 : 16|8@1+ (1,0) [0|255] "" ADL
 SG_ ADLTxData3 : 24|8@1+ (1,0) [0|255] "" ADL
 SG_ ADLTxData4 : 32|8@1+ (1,0) [0|255] "" ADL
 SG_ ADLTxData5 : 40|8@1+ (1,0) [0|255] "" ADL
 SG_ ADLTxData6 : 48|8@1+ (1,0) [0|255] "" ADL
 SG_ ADLTxData7 : 56|8@1+ (1,0) [0|255] "" ADL

BO_ 2566899856 PGN65480_Tx_8 :8 CentralMulti
 SG_ ADLTxData0 : 0|8@1+ (1,0) [0|255] "" ADL
 SG_ ADLTxData1 : 8|8@1+ (1,0) [0|255] "" ADL
 SG_ ADLTxData2 : 16|8@1+ (1,0) [0|255] "" ADL
 SG_ ADLTxData3 : 24|8@1+ (1,0) [0|255] "" ADL
 SG_ ADLTxData4 : 32|8@1+ (1,0) [0|255] "" ADL
 SG_ ADLTxData5 : 40|8@1+ (1,0) [0|255] "" ADL
 SG_ ADLTxData6 : 48|8@1+ (1,0) [0|255] "" ADL
 SG_ ADLTxData7 : 56|8@1+ (1,0) [0|255] "" ADL

BO_ 2566899848 PGN65480_Tx_9 :8 CentralMulti
 SG_ ADLTxData0 : 0|8@1+ (1,0) [0|255] "" ADL
 SG_ ADLTxData1 : 8|8@1+ (1,0) [0|255] "" ADL
 SG_ ADLTxData2 : 16|8@1+ (1,0) [0|255] "" ADL
 SG_ ADLTxData3 : 24|8@1+ (1,0) [0|255] "" ADL
 SG_ ADLTxData4 : 32|8@1+ (1,0) [0|255] "" ADL
 SG_ ADLTxData5 : 40|8@1+ (1,0) [0|255] "" ADL
 SG_ ADLTxData6 : 48|8@1+ (1,0) [0|255] "" ADL
 SG_ ADLTxData7 : 56|8@1+ (1,0) [0|255] "" ADL

BO_ 2566899840 PGN65480_Tx_10 :8 CentralMulti
 SG_ ADLTxData0 : 0|8@1+ (1,0) [0|255] "" ADL
 SG_ ADLTxData1 : 8|8@1+ (1,0) [0|255] "" ADL
 SG_ ADLTxData2 : 16|8@1+ (1,0) [0|255] "" ADL
 SG_ ADLTxData3 : 24|8@1+ (1,0) [0|255] "" ADL
 SG_ ADLTxData4 : 32|8@1+ (1,0) [0|255] "" ADL
 SG_ ADLTxData5 : 40|8@1+ (1,0) [0|255] "" ADL
 SG_ ADLTxData6 : 48|8@1+ (1,0) [0|255] "" ADL
 SG_ ADLTxData7 : 56|8@1+ (1,0) [0|255] "" ADL

BO_ 2566759880 PGN64933_Tx :8 Central
 SG_ StaDoor1 : 2|2@1+ (1,0) [0|3] "" Vector__XXX

BO_ 2566759872 PGN64933_Tx_2 :8 CentralMulti
 SG_ StaDoor1 : 2|2@1+ (1,0) [0|3] "" Vector__XXX

BO_ 2566759864 PGN64933_Tx_3 :8 CentralMulti
 SG_ StaDoor1 : 2|2@1+ (1,0) [0|3] "" Vector__XXX

BO_ 2566759856 PGN64933_Tx_4 :8 CentralMulti
 SG_ StaDoor1 : 2|2@1+ (1,0) [0|3] "" Vector__XXX

BO_ 2566759848 PGN64933_Tx_5 :8 CentralMulti
 SG_ StaDoor1 : 2|2@1+ (1,0) [0|3] "" Vector__XXX

BO_ 2566759840 PGN64933_Tx_6 :8 CentralMulti
 SG_ StaDoor1 : 2|2@1+ (1,0) [0|3] "" Vector__XXX

BO_ 2566759832 PGN64933_Tx_7 :8 CentralMulti
 SG_ StaDoor1 : 2|2@1+ (1,0) [0|3] "" Vector__XXX

BO_ 2566759824 PGN64933_Tx_8 :8 CentralMulti
 SG_ StaDoor1 : 2|2@1+ (1,0) [0|3] "" Vector__XXX

BO_ 2566759816 PGN64933_Tx_9 :8 CentralMulti
 SG_ StaDoor1 : 2|2@1+ (1,0) [0|3] "" Vector__XXX

BO_ 2566759808 PGN64933_Tx_10 :8 CentralMulti
 SG_ StaDoor1 : 2|2@1+ (1,0) [0|3] "" Vector__XXX

BO_ 2566856904 PGN65312_Tx :8 Central
 SG_ PSys : 0|8@1+ (100,0) [0|255] "mbar" Vector__XXX
 SG_ PPneuDem : 8|8@1+ (100,0) [0|255] "mbar" Vector__XXX
 SG_ PElDemPress : 16|8@1+ (100,0) [0|255] "mbar" Vector__XXX
 SG_ GrossLoadPrc : 24|8@1+ (1,0) [0|255] "%" Vector__XXX
 SG_ PPneuCh0 : 32|8@1+ (100,0) [0|255] "mbar" Vector__XXX
 SG_ PPneuCh1 : 40|8@1+ (100,0) [0|255] "mbar" Vector__XXX
 SG_ PPneuCh2 : 48|8@1+ (100,0) [0|255] "mbar" Vector__XXX

BO_ 2566856896 PGN65312_Tx_2 :8 CentralMulti
 SG_ PSys : 0|8@1+ (100,0) [0|255] "mbar" Vector__XXX
 SG_ PPneuDem : 8|8@1+ (100,0) [0|255] "mbar" Vector__XXX
 SG_ PElDemPress : 16|8@1+ (100,0) [0|255] "mbar" Vector__XXX
 SG_ GrossLoadPrc : 24|8@1+ (1,0) [0|255] "%" Vector__XXX
 SG_ PPneuCh0 : 32|8@1+ (100,0) [0|255] "mbar" Vector__XXX
 SG_ PPneuCh1 : 40|8@1+ (100,0) [0|255] "mbar" Vector__XXX
 SG_ PPneuCh2 : 48|8@1+ (100,0) [0|255] "mbar" Vector__XXX

BO_ 2566856888 PGN65312_Tx_3 :8 CentralMulti
 SG_ PSys : 0|8@1+ (100,0) [0|255] "mbar" Vector__XXX
 SG_ PPneuDem : 8|8@1+ (100,0) [0|255] "mbar" Vector__XXX
 SG_ PElDemPress : 16|8@1+ (100,0) [0|255] "mbar" Vector__XXX
 SG_ GrossLoadPrc : 24|8@1+ (1,0) [0|255] "%" Vector__XXX
 SG_ PPneuCh0 : 32|8@1+ (100,0) [0|255] "mbar" Vector__XXX
 SG_ PPneuCh1 : 40|8@1+ (100,0) [0|255] "mbar" Vector__XXX
 SG_ PPneuCh2 : 48|8@1+ (100,0) [0|255] "mbar" Vector__XXX

BO_ 2566856880 PGN65312_Tx_4 :8 CentralMulti
 SG_ PSys : 0|8@1+ (100,0) [0|255] "mbar" Vector__XXX
 SG_ PPneuDem : 8|8@1+ (100,0) [0|255] "mbar" Vector__XXX
 SG_ PElDemPress : 16|8@1+ (100,0) [0|255] "mbar" Vector__XXX
 SG_ GrossLoadPrc : 24|8@1+ (1,0) [0|255] "%" Vector__XXX
 SG_ PPneuCh0 : 32|8@1+ (100,0) [0|255] "mbar" Vector__XXX
 SG_ PPneuCh1 : 40|8@1+ (100,0) [0|255] "mbar" Vector__XXX
 SG_ PPneuCh2 : 48|8@1+ (100,0) [0|255] "mbar" Vector__XXX

BO_ 2566856872 PGN65312_Tx_5 :8 CentralMulti
 SG_ PSys : 0|8@1+ (100,0) [0|255] "mbar" Vector__XXX
 SG_ PPneuDem : 8|8@1+ (100,0) [0|255] "mbar" Vector__XXX
 SG_ PElDemPress : 16|8@1+ (100,0) [0|255] "mbar" Vector__XXX
 SG_ GrossLoadPrc : 24|8@1+ (1,0) [0|255] "%" Vector__XXX
 SG_ PPneuCh0 : 32|8@1+ (100,0) [0|255] "mbar" Vector__XXX
 SG_ PPneuCh1 : 40|8@1+ (100,0) [0|255] "mbar" Vector__XXX
 SG_ PPneuCh2 : 48|8@1+ (100,0) [0|255] "mbar" Vector__XXX

BO_ 2566856864 PGN65312_Tx_6 :8 CentralMulti
 SG_ PSys : 0|8@1+ (100,0) [0|255] "mbar" Vector__XXX
 SG_ PPneuDem : 8|8@1+ (100,0) [0|255] "mbar" Vector__XXX
 SG_ PElDemPress : 16|8@1+ (100,0) [0|255] "mbar" Vector__XXX
 SG_ GrossLoadPrc : 24|8@1+ (1,0) [0|255] "%" Vector__XXX
 SG_ PPneuCh0 : 32|8@1+ (100,0) [0|255] "mbar" Vector__XXX
 SG_ PPneuCh1 : 40|8@1+ (100,0) [0|255] "mbar" Vector__XXX
 SG_ PPneuCh2 : 48|8@1+ (100,0) [0|255] "mbar" Vector__XXX

BO_ 2566856856 PGN65312_Tx_7 :8 CentralMulti
 SG_ PSys : 0|8@1+ (100,0) [0|255] "mbar" Vector__XXX
 SG_ PPneuDem : 8|8@1+ (100,0) [0|255] "mbar" Vector__XXX
 SG_ PElDemPress : 16|8@1+ (100,0) [0|255] "mbar" Vector__XXX
 SG_ GrossLoadPrc : 24|8@1+ (1,0) [0|255] "%" Vector__XXX
 SG_ PPneuCh0 : 32|8@1+ (100,0) [0|255] "mbar" Vector__XXX
 SG_ PPneuCh1 : 40|8@1+ (100,0) [0|255] "mbar" Vector__XXX
 SG_ PPneuCh2 : 48|8@1+ (100,0) [0|255] "mbar" Vector__XXX

BO_ 2566856848 PGN65312_Tx_8 :8 CentralMulti
 SG_ PSys : 0|8@1+ (100,0) [0|255] "mbar" Vector__XXX
 SG_ PPneuDem : 8|8@1+ (100,0) [0|255] "mbar" Vector__XXX
 SG_ PElDemPress : 16|8@1+ (100,0) [0|255] "mbar" Vector__XXX
 SG_ GrossLoadPrc : 24|8@1+ (1,0) [0|255] "%" Vector__XXX
 SG_ PPneuCh0 : 32|8@1+ (100,0) [0|255] "mbar" Vector__XXX
 SG_ PPneuCh1 : 40|8@1+ (100,0) [0|255] "mbar" Vector__XXX
 SG_ PPneuCh2 : 48|8@1+ (100,0) [0|255] "mbar" Vector__XXX

BO_ 2566856840 PGN65312_Tx_9 :8 CentralMulti
 SG_ PSys : 0|8@1+ (100,0) [0|255] "mbar" Vector__XXX
 SG_ PPneuDem : 8|8@1+ (100,0) [0|255] "mbar" Vector__XXX
 SG_ PElDemPress : 16|8@1+ (100,0) [0|255] "mbar" Vector__XXX
 SG_ GrossLoadPrc : 24|8@1+ (1,0) [0|255] "%" Vector__XXX
 SG_ PPneuCh0 : 32|8@1+ (100,0) [0|255] "mbar" Vector__XXX
 SG_ PPneuCh1 : 40|8@1+ (100,0) [0|255] "mbar" Vector__XXX
 SG_ PPneuCh2 : 48|8@1+ (100,0) [0|255] "mbar" Vector__XXX

BO_ 2566856832 PGN65312_Tx_10 :8 CentralMulti
 SG_ PSys : 0|8@1+ (100,0) [0|255] "mbar" Vector__XXX
 SG_ PPneuDem : 8|8@1+ (100,0) [0|255] "mbar" Vector__XXX
 SG_ PElDemPress : 16|8@1+ (100,0) [0|255] "mbar" Vector__XXX
 SG_ GrossLoadPrc : 24|8@1+ (1,0) [0|255] "%" Vector__XXX
 SG_ PPneuCh0 : 32|8@1+ (100,0) [0|255] "mbar" Vector__XXX
 SG_ PPneuCh1 : 40|8@1+ (100,0) [0|255] "mbar" Vector__XXX
 SG_ PPneuCh2 : 48|8@1+ (100,0) [0|255] "mbar" Vector__XXX

BO_ 2566857160 PGN65313_Tx :8 Central
 SG_ vVeh : 0|8@1+ (1,0) [0|255] "km/h" Vector__XXX
 SG_ vWhl0 : 8|8@1+ (1,0) [0|255] "km/h" Vector__XXX
 SG_ vWhl1 : 16|8@1+ (1,0) [0|255] "km/h" Vector__XXX
 SG_ vWhl2 : 24|8@1+ (1,0) [0|255] "km/h" Vector__XXX
 SG_ vWhl3 : 32|8@1+ (1,0) [0|255] "km/h" Vector__XXX
 SG_ StABSCh0 : 40|8@1+ (1,0) [0|255] "" Vector__XXX
 SG_ StABSCh1 : 48|8@1+ (1,0) [0|255] "" Vector__XXX
 SG_ StABSCh2 : 56|8@1+ (1,0) [0|255] "" Vector__XXX

BO_ 2566857152 PGN65313_Tx_2 :8 CentralMulti
 SG_ vVeh : 0|8@1+ (1,0) [0|255] "km/h" Vector__XXX
 SG_ vWhl0 : 8|8@1+ (1,0) [0|255] "km/h" Vector__XXX
 SG_ vWhl1 : 16|8@1+ (1,0) [0|255] "km/h" Vector__XXX
 SG_ vWhl2 : 24|8@1+ (1,0) [0|255] "km/h" Vector__XXX
 SG_ vWhl3 : 32|8@1+ (1,0) [0|255] "km/h" Vector__XXX
 SG_ StABSCh0 : 40|8@1+ (1,0) [0|255] "" Vector__XXX
 SG_ StABSCh1 : 48|8@1+ (1,0) [0|255] "" Vector__XXX
 SG_ StABSCh2 : 56|8@1+ (1,0) [0|255] "" Vector__XXX

BO_ 2566857144 PGN65313_Tx_3 :8 CentralMulti
 SG_ vVeh : 0|8@1+ (1,0) [0|255] "km/h" Vector__XXX
 SG_ vWhl0 : 8|8@1+ (1,0) [0|255] "km/h" Vector__XXX
 SG_ vWhl1 : 16|8@1+ (1,0) [0|255] "km/h" Vector__XXX
 SG_ vWhl2 : 24|8@1+ (1,0) [0|255] "km/h" Vector__XXX
 SG_ vWhl3 : 32|8@1+ (1,0) [0|255] "km/h" Vector__XXX
 SG_ StABSCh0 : 40|8@1+ (1,0) [0|255] "" Vector__XXX
 SG_ StABSCh1 : 48|8@1+ (1,0) [0|255] "" Vector__XXX
 SG_ StABSCh2 : 56|8@1+ (1,0) [0|255] "" Vector__XXX

BO_ 2566857136 PGN65313_Tx_4 :8 CentralMulti
 SG_ vVeh : 0|8@1+ (1,0) [0|255] "km/h" Vector__XXX
 SG_ vWhl0 : 8|8@1+ (1,0) [0|255] "km/h" Vector__XXX
 SG_ vWhl1 : 16|8@1+ (1,0) [0|255] "km/h" Vector__XXX
 SG_ vWhl2 : 24|8@1+ (1,0) [0|255] "km/h" Vector__XXX
 SG_ vWhl3 : 32|8@1+ (1,0) [0|255] "km/h" Vector__XXX
 SG_ StABSCh0 : 40|8@1+ (1,0) [0|255] "" Vector__XXX
 SG_ StABSCh1 : 48|8@1+ (1,0) [0|255] "" Vector__XXX
 SG_ StABSCh2 : 56|8@1+ (1,0) [0|255] "" Vector__XXX

BO_ 2566857128 PGN65313_Tx_5 :8 CentralMulti
 SG_ vVeh : 0|8@1+ (1,0) [0|255] "km/h" Vector__XXX
 SG_ vWhl0 : 8|8@1+ (1,0) [0|255] "km/h" Vector__XXX
 SG_ vWhl1 : 16|8@1+ (1,0) [0|255] "km/h" Vector__XXX
 SG_ vWhl2 : 24|8@1+ (1,0) [0|255] "km/h" Vector__XXX
 SG_ vWhl3 : 32|8@1+ (1,0) [0|255] "km/h" Vector__XXX
 SG_ StABSCh0 : 40|8@1+ (1,0) [0|255] "" Vector__XXX
 SG_ StABSCh1 : 48|8@1+ (1,0) [0|255] "" Vector__XXX
 SG_ StABSCh2 : 56|8@1+ (1,0) [0|255] "" Vector__XXX

BO_ 2566857120 PGN65313_Tx_6 :8 CentralMulti
 SG_ vVeh : 0|8@1+ (1,0) [0|255] "km/h" Vector__XXX
 SG_ vWhl0 : 8|8@1+ (1,0) [0|255] "km/h" Vector__XXX
 SG_ vWhl1 : 16|8@1+ (1,0) [0|255] "km/h" Vector__XXX
 SG_ vWhl2 : 24|8@1+ (1,0) [0|255] "km/h" Vector__XXX
 SG_ vWhl3 : 32|8@1+ (1,0) [0|255] "km/h" Vector__XXX
 SG_ StABSCh0 : 40|8@1+ (1,0) [0|255] "" Vector__XXX
 SG_ StABSCh1 : 48|8@1+ (1,0) [0|255] "" Vector__XXX
 SG_ StABSCh2 : 56|8@1+ (1,0) [0|255] "" Vector__XXX

BO_ 2566857112 PGN65313_Tx_7 :8 CentralMulti
 SG_ vVeh : 0|8@1+ (1,0) [0|255] "km/h" Vector__XXX
 SG_ vWhl0 : 8|8@1+ (1,0) [0|255] "km/h" Vector__XXX
 SG_ vWhl1 : 16|8@1+ (1,0) [0|255] "km/h" Vector__XXX
 SG_ vWhl2 : 24|8@1+ (1,0) [0|255] "km/h" Vector__XXX
 SG_ vWhl3 : 32|8@1+ (1,0) [0|255] "km/h" Vector__XXX
 SG_ StABSCh0 : 40|8@1+ (1,0) [0|255] "" Vector__XXX
 SG_ StABSCh1 : 48|8@1+ (1,0) [0|255] "" Vector__XXX
 SG_ StABSCh2 : 56|8@1+ (1,0) [0|255] "" Vector__XXX

BO_ 2566857104 PGN65313_Tx_8 :8 CentralMulti
 SG_ vVeh : 0|8@1+ (1,0) [0|255] "km/h" Vector__XXX
 SG_ vWhl0 : 8|8@1+ (1,0) [0|255] "km/h" Vector__XXX
 SG_ vWhl1 : 16|8@1+ (1,0) [0|255] "km/h" Vector__XXX
 SG_ vWhl2 : 24|8@1+ (1,0) [0|255] "km/h" Vector__XXX
 SG_ vWhl3 : 32|8@1+ (1,0) [0|255] "km/h" Vector__XXX
 SG_ StABSCh0 : 40|8@1+ (1,0) [0|255] "" Vector__XXX
 SG_ StABSCh1 : 48|8@1+ (1,0) [0|255] "" Vector__XXX
 SG_ StABSCh2 : 56|8@1+ (1,0) [0|255] "" Vector__XXX

BO_ 2566857096 PGN65313_Tx_9 :8 CentralMulti
 SG_ vVeh : 0|8@1+ (1,0) [0|255] "km/h" Vector__XXX
 SG_ vWhl0 : 8|8@1+ (1,0) [0|255] "km/h" Vector__XXX
 SG_ vWhl1 : 16|8@1+ (1,0) [0|255] "km/h" Vector__XXX
 SG_ vWhl2 : 24|8@1+ (1,0) [0|255] "km/h" Vector__XXX
 SG_ vWhl3 : 32|8@1+ (1,0) [0|255] "km/h" Vector__XXX
 SG_ StABSCh0 : 40|8@1+ (1,0) [0|255] "" Vector__XXX
 SG_ StABSCh1 : 48|8@1+ (1,0) [0|255] "" Vector__XXX
 SG_ StABSCh2 : 56|8@1+ (1,0) [0|255] "" Vector__XXX

BO_ 2566857088 PGN65313_Tx_10 :8 CentralMulti
 SG_ vVeh : 0|8@1+ (1,0) [0|255] "km/h" Vector__XXX
 SG_ vWhl0 : 8|8@1+ (1,0) [0|255] "km/h" Vector__XXX
 SG_ vWhl1 : 16|8@1+ (1,0) [0|255] "km/h" Vector__XXX
 SG_ vWhl2 : 24|8@1+ (1,0) [0|255] "km/h" Vector__XXX
 SG_ vWhl3 : 32|8@1+ (1,0) [0|255] "km/h" Vector__XXX
 SG_ StABSCh0 : 40|8@1+ (1,0) [0|255] "" Vector__XXX
 SG_ StABSCh1 : 48|8@1+ (1,0) [0|255] "" Vector__XXX
 SG_ StABSCh2 : 56|8@1+ (1,0) [0|255] "" Vector__XXX

BO_ 2566857416 PGN65314_Tx :8 Central
 SG_ RSP_TestPulse : 0|2@1+ (1,0) [0|3] "" Vector__XXX
 SG_ RSP_Step_1 : 2|2@1+ (1,0) [0|3] "" Vector__XXX
 SG_ RSP_Step_2 : 4|2@1+ (1,0) [0|3] "" Vector__XXX
 SG_ RSP_Step_3 : 6|2@1+ (1,0) [0|3] "" Vector__XXX
 SG_ Lateral_Accel : 8|16@1+ (1,-32127) [0|65535] "mm/s2" Vector__XXX
 SG_ AyOffset : 32|8@1+ (16,-2048) [0|255] "mm/s2" Vector__XXX
 SG_ AyLimit : 40|8@1+ (32,0) [0|255] "mm/s2" Vector__XXX
 SG_ TxTask10msRuntime : 48|16@1+ (0.8,0) [0|65535] "ms" Vector__XXX

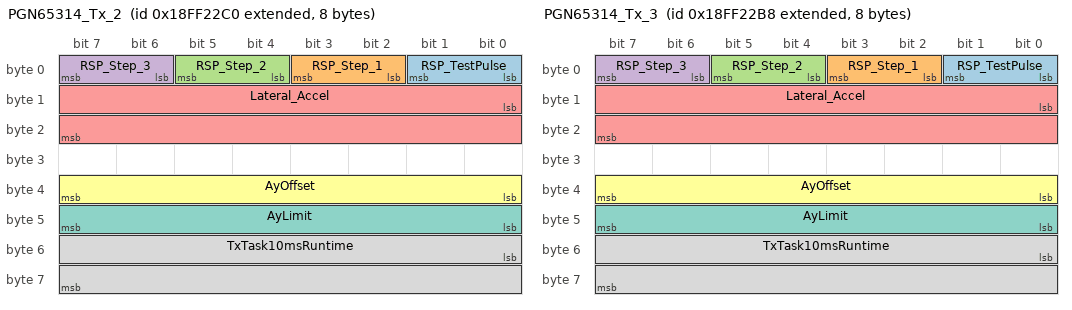
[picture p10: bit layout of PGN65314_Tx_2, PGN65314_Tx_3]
BO_ 2566857408 PGN65314_Tx_2 :8 CentralMulti
 SG_ RSP_TestPulse : 0|2@1+ (1,0) [0|3] "" Vector__XXX
 SG_ RSP_Step_1 : 2|2@1+ (1,0) [0|3] "" Vector__XXX
 SG_ RSP_Step_2 : 4|2@1+ (1,0) [0|3] "" Vector__XXX
 SG_ RSP_Step_3 : 6|2@1+ (1,0) [0|3] "" Vector__XXX
 SG_ Lateral_Accel : 8|16@1+ (1,-32127) [0|65535] "mm/s2" Vector__XXX
 SG_ AyOffset : 32|8@1+ (16,-2048) [0|255] "mm/s2" Vector__XXX
 SG_ AyLimit : 40|8@1+ (32,0) [0|255] "mm/s2" Vector__XXX
 SG_ TxTask10msRuntime : 48|16@1+ (0.8,0) [0|65535] "ms" Vector__XXX

BO_ 2566857400 PGN65314_Tx_3 :8 CentralMulti
 SG_ RSP_TestPulse : 0|2@1+ (1,0) [0|3] "" Vector__XXX
 SG_ RSP_Step_1 : 2|2@1+ (1,0) [0|3] "" Vector__XXX
 SG_ RSP_Step_2 : 4|2@1+ (1,0) [0|3] "" Vector__XXX
 SG_ RSP_Step_3 : 6|2@1+ (1,0) [0|3] "" Vector__XXX
 SG_ Lateral_Accel : 8|16@1+ (1,-32127) [0|65535] "mm/s2" Vector__XXX
 SG_ AyOffset : 32|8@1+ (16,-2048) [0|255] "mm/s2" Vector__XXX
 SG_ AyLimit : 40|8@1+ (32,0) [0|255] "mm/s2" Vector__XXX
 SG_ TxTask10msRuntime : 48|16@1+ (0.8,0) [0|65535] "ms" Vector__XXX

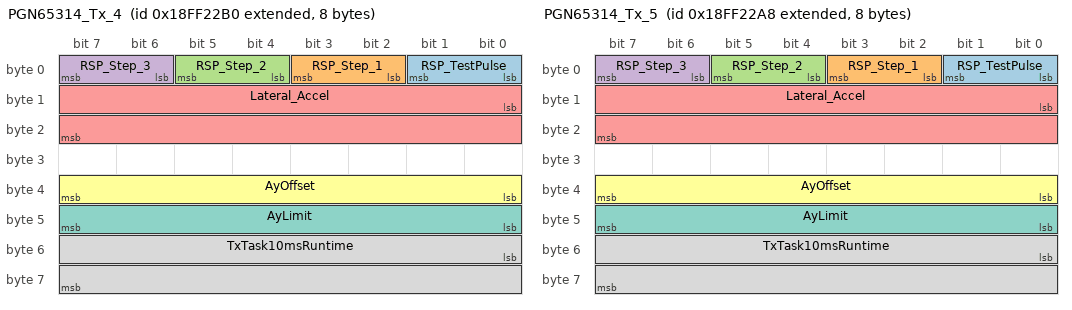
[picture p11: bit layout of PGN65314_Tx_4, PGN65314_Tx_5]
BO_ 2566857392 PGN65314_Tx_4 :8 CentralMulti
 SG_ RSP_TestPulse : 0|2@1+ (1,0) [0|3] "" Vector__XXX
 SG_ RSP_Step_1 : 2|2@1+ (1,0) [0|3] "" Vector__XXX
 SG_ RSP_Step_2 : 4|2@1+ (1,0) [0|3] "" Vector__XXX
 SG_ RSP_Step_3 : 6|2@1+ (1,0) [0|3] "" Vector__XXX
 SG_ Lateral_Accel : 8|16@1+ (1,-32127) [0|65535] "mm/s2" Vector__XXX
 SG_ AyOffset : 32|8@1+ (16,-2048) [0|255] "mm/s2" Vector__XXX
 SG_ AyLimit : 40|8@1+ (32,0) [0|255] "mm/s2" Vector__XXX
 SG_ TxTask10msRuntime : 48|16@1+ (0.8,0) [0|65535] "ms" Vector__XXX

BO_ 2566857384 PGN65314_Tx_5 :8 CentralMulti
 SG_ RSP_TestPulse : 0|2@1+ (1,0) [0|3] "" Vector__XXX
 SG_ RSP_Step_1 : 2|2@1+ (1,0) [0|3] "" Vector__XXX
 SG_ RSP_Step_2 : 4|2@1+ (1,0) [0|3] "" Vector__XXX
 SG_ RSP_Step_3 : 6|2@1+ (1,0) [0|3] "" Vector__XXX
 SG_ Lateral_Accel : 8|16@1+ (1,-32127) [0|65535] "mm/s2" Vector__XXX
 SG_ AyOffset : 32|8@1+ (16,-2048) [0|255] "mm/s2" Vector__XXX
 SG_ AyLimit : 40|8@1+ (32,0) [0|255] "mm/s2" Vector__XXX
 SG_ TxTask10msRuntime : 48|16@1+ (0.8,0) [0|65535] "ms" Vector__XXX

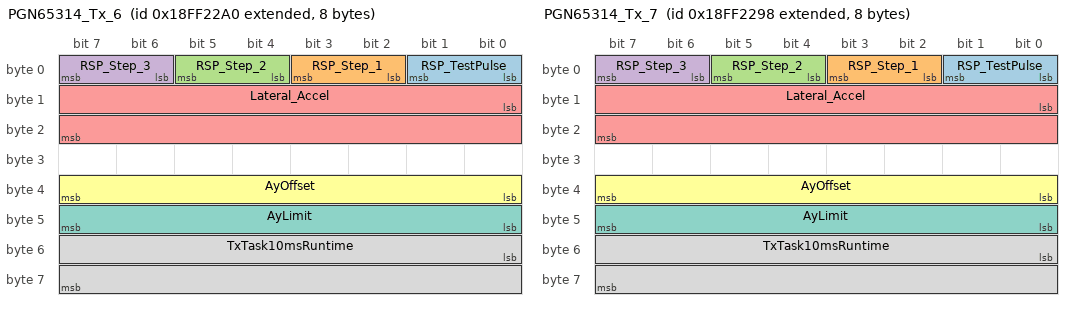
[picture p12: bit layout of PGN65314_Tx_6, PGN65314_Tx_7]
BO_ 2566857376 PGN65314_Tx_6 :8 CentralMulti
 SG_ RSP_TestPulse : 0|2@1+ (1,0) [0|3] "" Vector__XXX
 SG_ RSP_Step_1 : 2|2@1+ (1,0) [0|3] "" Vector__XXX
 SG_ RSP_Step_2 : 4|2@1+ (1,0) [0|3] "" Vector__XXX
 SG_ RSP_Step_3 : 6|2@1+ (1,0) [0|3] "" Vector__XXX
 SG_ Lateral_Accel : 8|16@1+ (1,-32127) [0|65535] "mm/s2" Vector__XXX
 SG_ AyOffset : 32|8@1+ (16,-2048) [0|255] "mm/s2" Vector__XXX
 SG_ AyLimit : 40|8@1+ (32,0) [0|255] "mm/s2" Vector__XXX
 SG_ TxTask10msRuntime : 48|16@1+ (0.8,0) [0|65535] "ms" Vector__XXX

BO_ 2566857368 PGN65314_Tx_7 :8 CentralMulti
 SG_ RSP_TestPulse : 0|2@1+ (1,0) [0|3] "" Vector__XXX
 SG_ RSP_Step_1 : 2|2@1+ (1,0) [0|3] "" Vector__XXX
 SG_ RSP_Step_2 : 4|2@1+ (1,0) [0|3] "" Vector__XXX
 SG_ RSP_Step_3 : 6|2@1+ (1,0) [0|3] "" Vector__XXX
 SG_ Lateral_Accel : 8|16@1+ (1,-32127) [0|65535] "mm/s2" Vector__XXX
 SG_ AyOffset : 32|8@1+ (16,-2048) [0|255] "mm/s2" Vector__XXX
 SG_ AyLimit : 40|8@1+ (32,0) [0|255] "mm/s2" Vector__XXX
 SG_ TxTask10msRuntime : 48|16@1+ (0.8,0) [0|65535] "ms" Vector__XXX

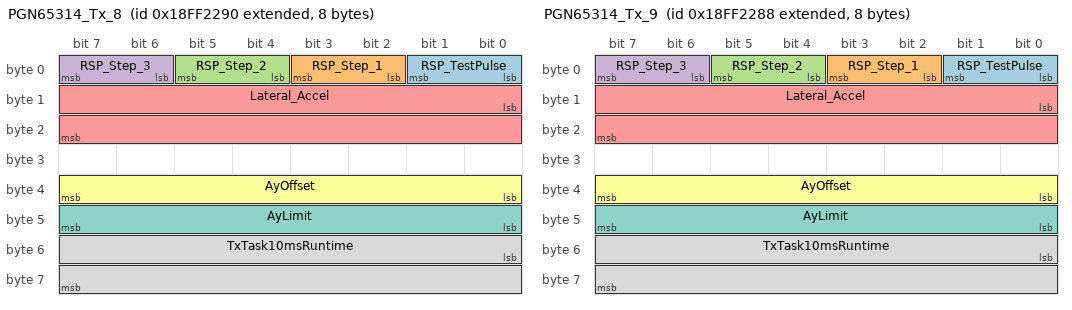
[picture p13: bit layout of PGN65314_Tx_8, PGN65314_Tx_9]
BO_ 2566857360 PGN65314_Tx_8 :8 CentralMulti
 SG_ RSP_TestPulse : 0|2@1+ (1,0) [0|3] "" Vector__XXX
 SG_ RSP_Step_1 : 2|2@1+ (1,0) [0|3] "" Vector__XXX
 SG_ RSP_Step_2 : 4|2@1+ (1,0) [0|3] "" Vector__XXX
 SG_ RSP_Step_3 : 6|2@1+ (1,0) [0|3] "" Vector__XXX
 SG_ Lateral_Accel : 8|16@1+ (1,-32127) [0|65535] "mm/s2" Vector__XXX
 SG_ AyOffset : 32|8@1+ (16,-2048) [0|255] "mm/s2" Vector__XXX
 SG_ AyLimit : 40|8@1+ (32,0) [0|255] "mm/s2" Vector__XXX
 SG_ TxTask10msRuntime : 48|16@1+ (0.8,0) [0|65535] "ms" Vector__XXX

BO_ 2566857352 PGN65314_Tx_9 :8 CentralMulti
 SG_ RSP_TestPulse : 0|2@1+ (1,0) [0|3] "" Vector__XXX
 SG_ RSP_Step_1 : 2|2@1+ (1,0) [0|3] "" Vector__XXX
 SG_ RSP_Step_2 : 4|2@1+ (1,0) [0|3] "" Vector__XXX
 SG_ RSP_Step_3 : 6|2@1+ (1,0) [0|3] "" Vector__XXX
 SG_ Lateral_Accel : 8|16@1+ (1,-32127) [0|65535] "mm/s2" Vector__XXX
 SG_ AyOffset : 32|8@1+ (16,-2048) [0|255] "mm/s2" Vector__XXX
 SG_ AyLimit : 40|8@1+ (32,0) [0|255] "mm/s2" Vector__XXX
 SG_ TxTask10msRuntime : 48|16@1+ (0.8,0) [0|65535] "ms" Vector__XXX

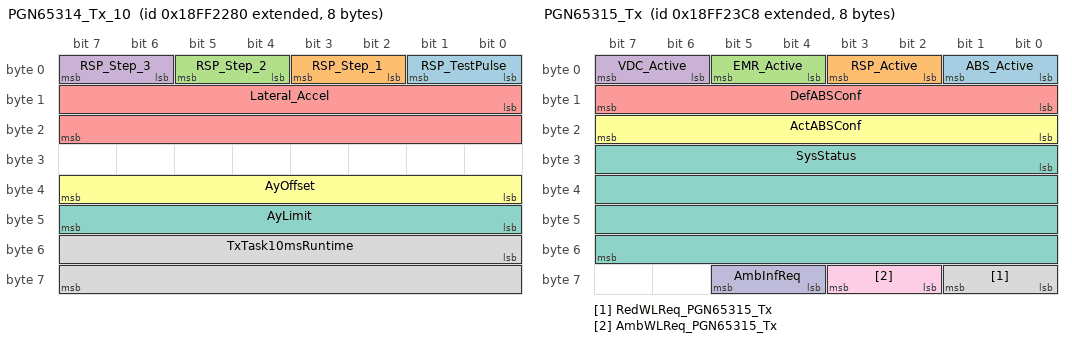
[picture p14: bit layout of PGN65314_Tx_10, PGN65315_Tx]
BO_ 2566857344 PGN65314_Tx_10 :8 CentralMulti
 SG_ RSP_TestPulse : 0|2@1+ (1,0) [0|3] "" Vector__XXX
 SG_ RSP_Step_1 : 2|2@1+ (1,0) [0|3] "" Vector__XXX
 SG_ RSP_Step_2 : 4|2@1+ (1,0) [0|3] "" Vector__XXX
 SG_ RSP_Step_3 : 6|2@1+ (1,0) [0|3] "" Vector__XXX
 SG_ Lateral_Accel : 8|16@1+ (1,-32127) [0|65535] "mm/s2" Vector__XXX
 SG_ AyOffset : 32|8@1+ (16,-2048) [0|255] "mm/s2" Vector__XXX
 SG_ AyLimit : 40|8@1+ (32,0) [0|255] "mm/s2" Vector__XXX
 SG_ TxTask10msRuntime : 48|16@1+ (0.8,0) [0|65535] "ms" Vector__XXX

BO_ 2566857672 PGN65315_Tx :8 Central
 SG_ ABS_Active : 0|2@1+ (1,0) [0|3] "" Vector__XXX
 SG_ RSP_Active : 2|2@1+ (1,0) [0|3] "" Vector__XXX
 SG_ EMR_Active : 4|2@1+ (1,0) [0|3] "" Vector__XXX
 SG_ VDC_Active : 6|2@1+ (1,0) [0|3] "" Vector__XXX
 SG_ DefABSConf : 8|8@1+ (1,0) [0|255] "" Vector__XXX
 SG_ ActABSConf : 16|8@1+ (1,0) [0|255] "" Vector__XXX
 SG_ SysStatus : 24|32@1+ (1,0) [0|4294967295] "" Vector__XXX
 SG_ RedWLReq_PGN65315_Tx : 56|2@1+ (1,0) [0|3] "" Vector__XXX
 SG_ AmbWLReq_PGN65315_Tx : 58|2@1+ (1,0) [0|3] "" Vector__XXX
 SG_ AmbInfReq : 60|2@1+ (1,0) [0|3] "" Vector__XXX

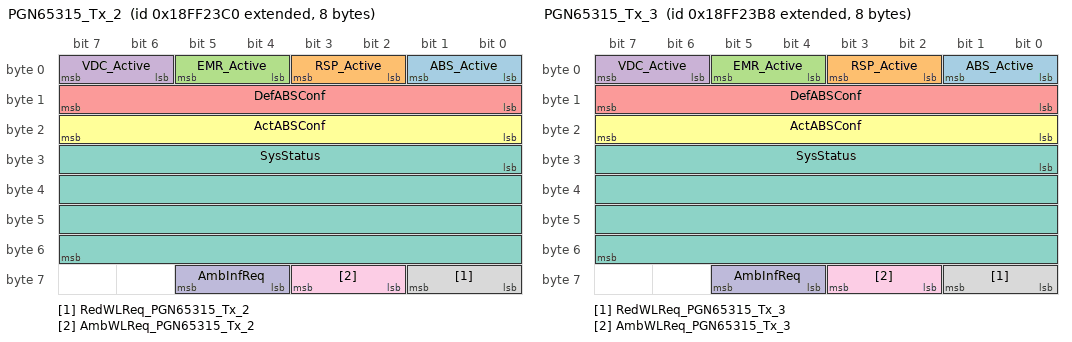
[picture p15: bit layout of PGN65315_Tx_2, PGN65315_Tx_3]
BO_ 2566857664 PGN65315_Tx_2 :8 CentralMulti
 SG_ ABS_Active : 0|2@1+ (1,0) [0|3] "" Vector__XXX
 SG_ RSP_Active : 2|2@1+ (1,0) [0|3] "" Vector__XXX
 SG_ EMR_Active : 4|2@1+ (1,0) [0|3] "" Vector__XXX
 SG_ VDC_Active : 6|2@1+ (1,0) [0|3] "" Vector__XXX
 SG_ DefABSConf : 8|8@1+ (1,0) [0|255] "" Vector__XXX
 SG_ ActABSConf : 16|8@1+ (1,0) [0|255] "" Vector__XXX
 SG_ SysStatus : 24|32@1+ (1,0) [0|4294967295] "" Vector__XXX
 SG_ RedWLReq_PGN65315_Tx_2 : 56|2@1+ (1,0) [0|3] "" Vector__XXX
 SG_ AmbWLReq_PGN65315_Tx_2 : 58|2@1+ (1,0) [0|3] "" Vector__XXX
 SG_ AmbInfReq : 60|2@1+ (1,0) [0|3] "" Vector__XXX

BO_ 2566857656 PGN65315_Tx_3 :8 CentralMulti
 SG_ ABS_Active : 0|2@1+ (1,0) [0|3] "" Vector__XXX
 SG_ RSP_Active : 2|2@1+ (1,0) [0|3] "" Vector__XXX
 SG_ EMR_Active : 4|2@1+ (1,0) [0|3] "" Vector__XXX
 SG_ VDC_Active : 6|2@1+ (1,0) [0|3] "" Vector__XXX
 SG_ DefABSConf : 8|8@1+ (1,0) [0|255] "" Vector__XXX
 SG_ ActABSConf : 16|8@1+ (1,0) [0|255] "" Vector__XXX
 SG_ SysStatus : 24|32@1+ (1,0) [0|4294967295] "" Vector__XXX
 SG_ RedWLReq_PGN65315_Tx_3 : 56|2@1+ (1,0) [0|3] "" Vector__XXX
 SG_ AmbWLReq_PGN65315_Tx_3 : 58|2@1+ (1,0) [0|3] "" Vector__XXX
 SG_ AmbInfReq : 60|2@1+ (1,0) [0|3] "" Vector__XXX

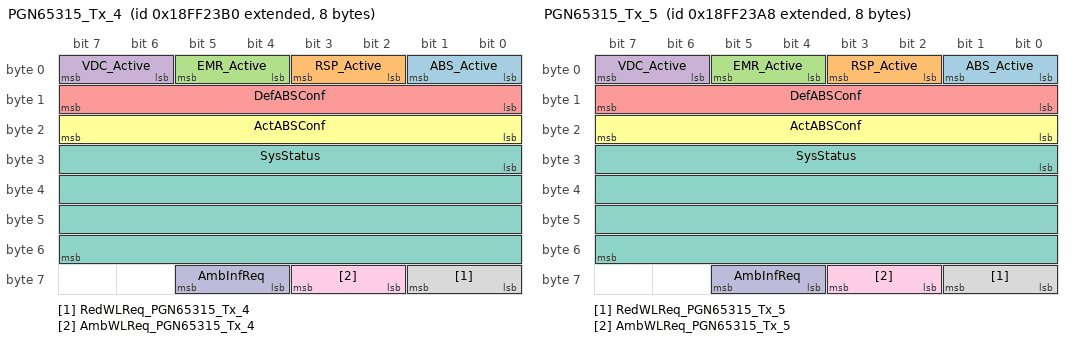
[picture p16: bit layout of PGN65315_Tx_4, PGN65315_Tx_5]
BO_ 2566857648 PGN65315_Tx_4 :8 CentralMulti
 SG_ ABS_Active : 0|2@1+ (1,0) [0|3] "" Vector__XXX
 SG_ RSP_Active : 2|2@1+ (1,0) [0|3] "" Vector__XXX
 SG_ EMR_Active : 4|2@1+ (1,0) [0|3] "" Vector__XXX
 SG_ VDC_Active : 6|2@1+ (1,0) [0|3] "" Vector__XXX
 SG_ DefABSConf : 8|8@1+ (1,0) [0|255] "" Vector__XXX
 SG_ ActABSConf : 16|8@1+ (1,0) [0|255] "" Vector__XXX
 SG_ SysStatus : 24|32@1+ (1,0) [0|4294967295] "" Vector__XXX
 SG_ RedWLReq_PGN65315_Tx_4 : 56|2@1+ (1,0) [0|3] "" Vector__XXX
 SG_ AmbWLReq_PGN65315_Tx_4 : 58|2@1+ (1,0) [0|3] "" Vector__XXX
 SG_ AmbInfReq : 60|2@1+ (1,0) [0|3] "" Vector__XXX

BO_ 2566857640 PGN65315_Tx_5 :8 CentralMulti
 SG_ ABS_Active : 0|2@1+ (1,0) [0|3] "" Vector__XXX
 SG_ RSP_Active : 2|2@1+ (1,0) [0|3] "" Vector__XXX
 SG_ EMR_Active : 4|2@1+ (1,0) [0|3] "" Vector__XXX
 SG_ VDC_Active : 6|2@1+ (1,0) [0|3] "" Vector__XXX
 SG_ DefABSConf : 8|8@1+ (1,0) [0|255] "" Vector__XXX
 SG_ ActABSConf : 16|8@1+ (1,0) [0|255] "" Vector__XXX
 SG_ SysStatus : 24|32@1+ (1,0) [0|4294967295] "" Vector__XXX
 SG_ RedWLReq_PGN65315_Tx_5 : 56|2@1+ (1,0) [0|3] "" Vector__XXX
 SG_ AmbWLReq_PGN65315_Tx_5 : 58|2@1+ (1,0) [0|3] "" Vector__XXX
 SG_ AmbInfReq : 60|2@1+ (1,0) [0|3] "" Vector__XXX

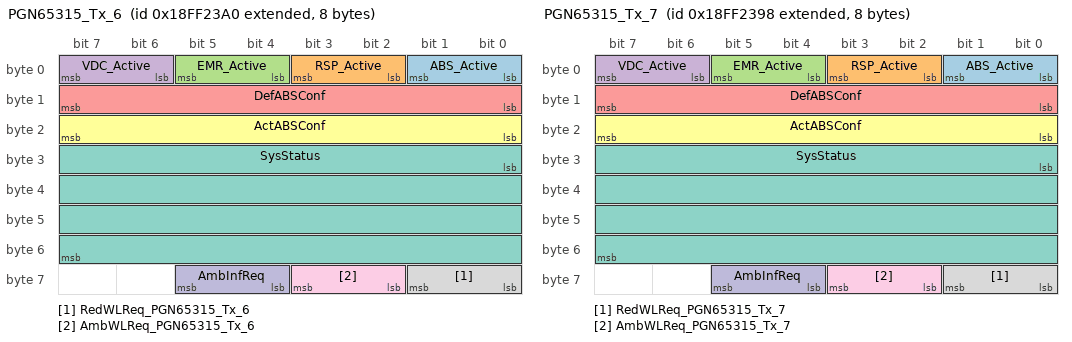
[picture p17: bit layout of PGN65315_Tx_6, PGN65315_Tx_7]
BO_ 2566857632 PGN65315_Tx_6 :8 CentralMulti
 SG_ ABS_Active : 0|2@1+ (1,0) [0|3] "" Vector__XXX
 SG_ RSP_Active : 2|2@1+ (1,0) [0|3] "" Vector__XXX
 SG_ EMR_Active : 4|2@1+ (1,0) [0|3] "" Vector__XXX
 SG_ VDC_Active : 6|2@1+ (1,0) [0|3] "" Vector__XXX
 SG_ DefABSConf : 8|8@1+ (1,0) [0|255] "" Vector__XXX
 SG_ ActABSConf : 16|8@1+ (1,0) [0|255] "" Vector__XXX
 SG_ SysStatus : 24|32@1+ (1,0) [0|4294967295] "" Vector__XXX
 SG_ RedWLReq_PGN65315_Tx_6 : 56|2@1+ (1,0) [0|3] "" Vector__XXX
 SG_ AmbWLReq_PGN65315_Tx_6 : 58|2@1+ (1,0) [0|3] "" Vector__XXX
 SG_ AmbInfReq : 60|2@1+ (1,0) [0|3] "" Vector__XXX

BO_ 2566857624 PGN65315_Tx_7 :8 CentralMulti
 SG_ ABS_Active : 0|2@1+ (1,0) [0|3] "" Vector__XXX
 SG_ RSP_Active : 2|2@1+ (1,0) [0|3] "" Vector__XXX
 SG_ EMR_Active : 4|2@1+ (1,0) [0|3] "" Vector__XXX
 SG_ VDC_Active : 6|2@1+ (1,0) [0|3] "" Vector__XXX
 SG_ DefABSConf : 8|8@1+ (1,0) [0|255] "" Vector__XXX
 SG_ ActABSConf : 16|8@1+ (1,0) [0|255] "" Vector__XXX
 SG_ SysStatus : 24|32@1+ (1,0) [0|4294967295] "" Vector__XXX
 SG_ RedWLReq_PGN65315_Tx_7 : 56|2@1+ (1,0) [0|3] "" Vector__XXX
 SG_ AmbWLReq_PGN65315_Tx_7 : 58|2@1+ (1,0) [0|3] "" Vector__XXX
 SG_ AmbInfReq : 60|2@1+ (1,0) [0|3] "" Vector__XXX

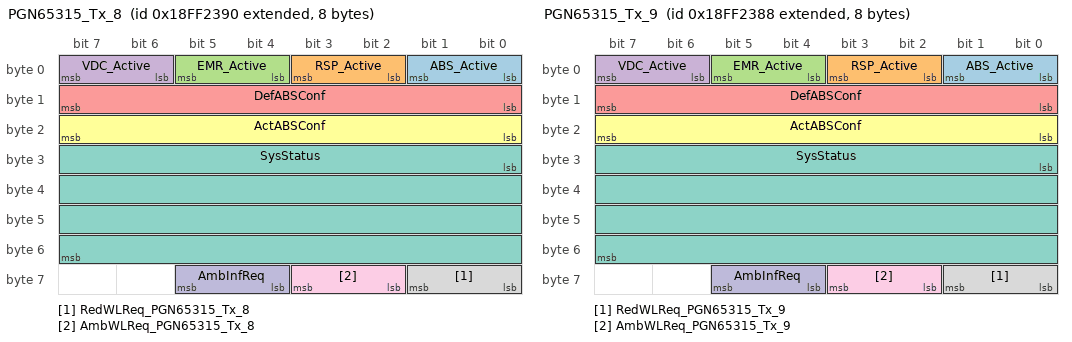
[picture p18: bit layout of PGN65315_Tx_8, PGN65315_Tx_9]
BO_ 2566857616 PGN65315_Tx_8 :8 CentralMulti
 SG_ ABS_Active : 0|2@1+ (1,0) [0|3] "" Vector__XXX
 SG_ RSP_Active : 2|2@1+ (1,0) [0|3] "" Vector__XXX
 SG_ EMR_Active : 4|2@1+ (1,0) [0|3] "" Vector__XXX
 SG_ VDC_Active : 6|2@1+ (1,0) [0|3] "" Vector__XXX
 SG_ DefABSConf : 8|8@1+ (1,0) [0|255] "" Vector__XXX
 SG_ ActABSConf : 16|8@1+ (1,0) [0|255] "" Vector__XXX
 SG_ SysStatus : 24|32@1+ (1,0) [0|4294967295] "" Vector__XXX
 SG_ RedWLReq_PGN65315_Tx_8 : 56|2@1+ (1,0) [0|3] "" Vector__XXX
 SG_ AmbWLReq_PGN65315_Tx_8 : 58|2@1+ (1,0) [0|3] "" Vector__XXX
 SG_ AmbInfReq : 60|2@1+ (1,0) [0|3] "" Vector__XXX

BO_ 2566857608 PGN65315_Tx_9 :8 CentralMulti
 SG_ ABS_Active : 0|2@1+ (1,0) [0|3] "" Vector__XXX
 SG_ RSP_Active : 2|2@1+ (1,0) [0|3] "" Vector__XXX
 SG_ EMR_Active : 4|2@1+ (1,0) [0|3] "" Vector__XXX
 SG_ VDC_Active : 6|2@1+ (1,0) [0|3] "" Vector__XXX
 SG_ DefABSConf : 8|8@1+ (1,0) [0|255] "" Vector__XXX
 SG_ ActABSConf : 16|8@1+ (1,0) [0|255] "" Vector__XXX
 SG_ SysStatus : 24|32@1+ (1,0) [0|4294967295] "" Vector__XXX
 SG_ RedWLReq_PGN65315_Tx_9 : 56|2@1+ (1,0) [0|3] "" Vector__XXX
 SG_ AmbWLReq_PGN65315_Tx_9 : 58|2@1+ (1,0) [0|3] "" Vector__XXX
 SG_ AmbInfReq : 60|2@1+ (1,0) [0|3] "" Vector__XXX

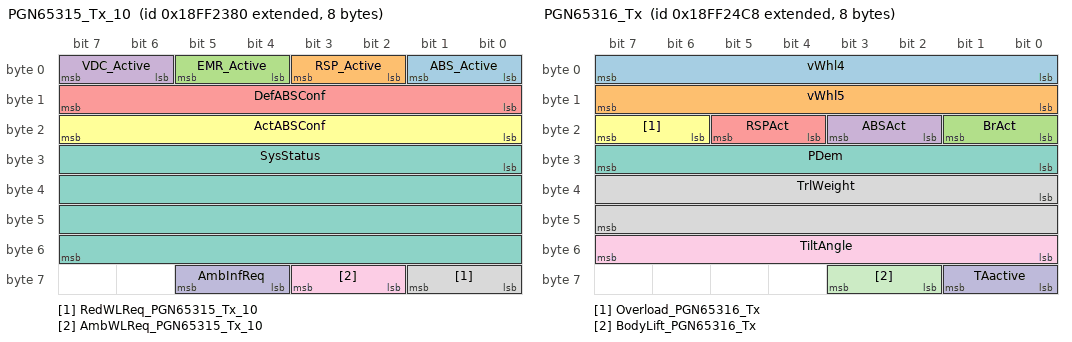
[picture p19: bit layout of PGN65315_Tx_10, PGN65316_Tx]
BO_ 2566857600 PGN65315_Tx_10 :8 CentralMulti
 SG_ ABS_Active : 0|2@1+ (1,0) [0|3] "" Vector__XXX
 SG_ RSP_Active : 2|2@1+ (1,0) [0|3] "" Vector__XXX
 SG_ EMR_Active : 4|2@1+ (1,0) [0|3] "" Vector__XXX
 SG_ VDC_Active : 6|2@1+ (1,0) [0|3] "" Vector__XXX
 SG_ DefABSConf : 8|8@1+ (1,0) [0|255] "" Vector__XXX
 SG_ ActABSConf : 16|8@1+ (1,0) [0|255] "" Vector__XXX
 SG_ SysStatus : 24|32@1+ (1,0) [0|4294967295] "" Vector__XXX
 SG_ RedWLReq_PGN65315_Tx_10 : 56|2@1+ (1,0) [0|3] "" Vector__XXX
 SG_ AmbWLReq_PGN65315_Tx_10 : 58|2@1+ (1,0) [0|3] "" Vector__XXX
 SG_ AmbInfReq : 60|2@1+ (1,0) [0|3] "" Vector__XXX

BO_ 2566857928 PGN65316_Tx :8 Central
 SG_ vWhl4 : 0|8@1+ (1,0) [0|255] "km/h" Vector__XXX
 SG_ vWhl5 : 8|8@1+ (1,0) [0|255] "km/h" Vector__XXX
 SG_ BrAct : 16|2@1+ (1,0) [0|3] "" Vector__XXX
 SG_ ABSAct : 18|2@1+ (1,0) [0|3] "" Vector__XXX
 SG_ RSPAct : 20|2@1+ (1,0) [0|3] "" Vector__XXX
 SG_ Overload_PGN65316_Tx : 22|2@1+ (1,0) [0|3] "" Vector__XXX
 SG_ PDem : 24|8@1+ (100,0) [0|255] "mbar" Vector__XXX
 SG_ TrlWeight : 32|16@1+ (2,0) [0|65535] "kg" Vector__XXX
 SG_ TiltAngle : 48|8@1+ (0.1,0) [0|255] "deg" Vector__XXX
 SG_ TAactive : 56|2@1+ (1,0) [0|3] "" Vector__XXX
 SG_ BodyLift_PGN65316_Tx : 58|2@1+ (1,0) [0|3] "" Vector__XXX

CM_ "This database file is auto-generated by can_procdb.pl";

BA_DEF_ BO_ "DiagConnection" INT 0 65535;
BA_DEF_ BO_ "DiagRequest" ENUM "No","Yes";
BA_DEF_ BO_ "DiagResponse" ENUM "No","Yes";
BA_DEF_ BO_ "GenMsgCycleTime" INT 0 3600000;
BA_DEF_ BO_ "GenMsgILSupport" ENUM "No","Yes";
BA_DEF_ BO_ "GenMsgRequestable" INT 0 1;
BA_DEF_ BO_ "GenMsgSendType" ENUM "cyclic","NotUsed","NotUsed","NotUsed","NotUsed","NotUsed","NotUsed","IfActive","noMsgSendType";
BA_DEF_ BO_ "VFrameFormat" ENUM "StandardCAN","ExtendedCAN","reserved","J1939PG";
BA_DEF_ "Baudrate" INT 0 1000000;
BA_DEF_ "BusType" STRING ;
BA_DEF_ "DBName" STRING ;
BA_DEF_ "DatabaseVersion" STRING ;
BA_DEF_ "GenEnvVarEndingDsp" STRING ;
BA_DEF_ "GenEnvVarEndingSnd" STRING ;
BA_DEF_ "GenEnvVarPrefix" STRING ;
BA_DEF_ "Manufacturer" STRING ;
BA_DEF_ "NmAsrBaseAddress" HEX 0 536870911;
BA_DEF_ "NmAsrCanMsgCycleTime" INT 0 65535;
BA_DEF_ "NmAsrMessageCount" INT 1 256;
BA_DEF_ "NmAsrRepeatMessageTime" INT 1 65535;
BA_DEF_ "NmAsrTimeoutTime" INT 1 65535;
BA_DEF_ "NmAsrWaitBusSleepTime" INT 1 65535;
BA_DEF_ "SAE_J1939_21_SpecVersion" STRING ;
BA_DEF_ "SAE_J1939_71_SpecVersion" STRING ;
BA_DEF_ "SAE_J1939_73_SpecVersion" STRING ;
BA_DEF_ "SAE_J1939_75_SpecVersion" STRING ;
BA_DEF_ "SAE_J1939_81_SpecVersion" STRING ;
BA_DEF_ SG_ "GenSigCycleTime" INT 0 4294967295;
BA_DEF_ SG_ "GenSigEVName" STRING ;
BA_DEF_ SG_ "GenSigILSupport" ENUM "No","Yes";
BA_DEF_ SG_ "GenSigInactiveValue" INT 0 4294967295;
BA_DEF_ SG_ "GenSigSendType" ENUM "Cyclic","OnWrite","OnWriteWithRepetition","OnChange","OnChangeWithRepetition","IfActive","IfActiveWithRepetition","NoSigSendType";
BA_DEF_ SG_ "GenSigStartValue" INT 0 4294967295;
BA_DEF_ SG_ "SigType" ENUM "Default","Range","RangeSigned","ASCII","Discrete","Control","ReferencePGN","DTC","StringDelimiter","StringLength","StringLengthControl";
BA_DEF_ BU_ "NmAsrCanMsgReducedTime" INT 1 65535;
BA_DEF_ BU_ "NmAsrNode" ENUM "No","Yes";
BA_DEF_ BU_ "NmStationAddress" INT 0 255;
BA_DEF_DEF_ "DiagConnection" 0;
BA_DEF_DEF_ "DiagRequest" "No";
BA_DEF_DEF_ "DiagResponse" "No";
BA_DEF_DEF_ "GenMsgCycleTime" 0;
BA_DEF_DEF_ "GenMsgILSupport" "Yes";
BA_DEF_DEF_ "GenMsgRequestable" 1;
BA_DEF_DEF_ "GenMsgSendType" "noMsgSendType";
BA_DEF_DEF_ "VFrameFormat" "J1939PG";
BA_DEF_DEF_ "Baudrate" 500000;
BA_DEF_DEF_ "BusType" "";
BA_DEF_DEF_ "DBName" "CAN";
BA_DEF_DEF_ "DatabaseVersion" "";
BA_DEF_DEF_ "GenEnvVarEndingDsp" "Dsp_";
BA_DEF_DEF_ "GenEnvVarEndingSnd" "_";
BA_DEF_DEF_ "GenEnvVarPrefix" "Env";
BA_DEF_DEF_ "Manufacturer" "Vector";
BA_DEF_DEF_ "NmAsrBaseAddress" 1024;
BA_DEF_DEF_ "NmAsrCanMsgCycleTime" 100;
BA_DEF_DEF_ "NmAsrMessageCount" 64;
BA_DEF_DEF_ "NmAsrRepeatMessageTime" 400;
BA_DEF_DEF_ "NmAsrTimeoutTime" 1000;
BA_DEF_DEF_ "NmAsrWaitBusSleepTime" 750;
BA_DEF_DEF_ "SAE_J1939_21_SpecVersion" "";
BA_DEF_DEF_ "SAE_J1939_71_SpecVersion" "";
BA_DEF_DEF_ "SAE_J1939_73_SpecVersion" "";
BA_DEF_DEF_ "SAE_J1939_75_SpecVersion" "";
BA_DEF_DEF_ "SAE_J1939_81_SpecVersion" "";
BA_DEF_DEF_ "GenSigCycleTime" 0;
BA_DEF_DEF_ "GenSigEVName" "Env@Nodename_@Signame";
BA_DEF_DEF_ "GenSigILSupport" "Yes";
BA_DEF_DEF_ "GenSigInactiveValue" 0;
BA_DEF_DEF_ "GenSigSendType" "NoSigSendType";
BA_DEF_DEF_ "GenSigStartValue" 0;
BA_DEF_DEF_ "SigType" "Default";
BA_DEF_DEF_ "NmAsrCanMsgReducedTime" 50;
BA_DEF_DEF_ "NmAsrNode" "Yes";
BA_DEF_DEF_ "NmStationAddress" 254;
BA_ "BusType" "CAN";
BA_ "DatabaseVersion" "7.6";
BA_ "SAE_J1939_21_SpecVersion" "2006-10";
BA_ "SAE_J1939_71_SpecVersion" "2011-09";
BA_ "SAE_J1939_73_SpecVersion" "2010-10";
BA_ "SAE_J1939_75_SpecVersion" "2005-10";
BA_ "SAE_J1939_81_SpecVersion" "2003-05";

BA_ "DiagRequest" BO_ 2564426728 1;
BA_ "DiagConnection" BO_ 2564426728 59403;
BA_ "VFrameFormat" BO_ 2564426728 1;
BA_ "GenSigSendType" SG_ 2564426728 UDSbyte1_UDSrequest 1;
BA_ "GenSigSendType" SG_ 2564426728 UDSbyte2_UDSrequest 1;
BA_ "GenSigSendType" SG_ 2564426728 UDSbyte3_UDSrequest 1;
BA_ "GenSigSendType" SG_ 2564426728 UDSbyte4_UDSrequest 1;
BA_ "GenSigSendType" SG_ 2564426728 UDSbyte5_UDSrequest 1;
BA_ "GenSigSendType" SG_ 2564426728 UDSbyte6_UDSrequest 1;
BA_ "GenSigSendType" SG_ 2564426728 UDSbyte7_UDSrequest 1;
BA_ "GenSigSendType" SG_ 2564426728 UDSbyte8_UDSrequest 1;
BA_ "GenMsgILSupport" BO_ 2564426728 0;
BA_ "DiagRequest" BO_ 2564426747 1;
BA_ "DiagConnection" BO_ 2564426747 64267;
BA_ "VFrameFormat" BO_ 2564426747 1;
BA_ "GenSigSendType" SG_ 2564426747 UDSbyte1_UDSrequest_TIM 1;
BA_ "GenSigSendType" SG_ 2564426747 UDSbyte2_UDSrequest_TIM 1;
BA_ "GenSigSendType" SG_ 2564426747 UDSbyte3_UDSrequest_TIM 1;
BA_ "GenSigSendType" SG_ 2564426747 UDSbyte4_UDSrequest_TIM 1;
BA_ "GenSigSendType" SG_ 2564426747 UDSbyte5_UDSrequest_TIM 1;
BA_ "GenSigSendType" SG_ 2564426747 UDSbyte6_UDSrequest_TIM 1;
BA_ "GenSigSendType" SG_ 2564426747 UDSbyte7_UDSrequest_TIM 1;
BA_ "GenSigSendType" SG_ 2564426747 UDSbyte8_UDSrequest_TIM 1;
BA_ "GenMsgILSupport" BO_ 2564426747 0;
BA_ "DiagRequest" BO_ 2631535509 1;
BA_ "DiagConnection" BO_ 2631535509 38155;
BA_ "VFrameFormat" BO_ 2631535509 1;
BA_ "GenSigSendType" SG_ 2631535509 UDSbyte1_UDSrequest_J1939_CTU 1;
BA_ "GenSigSendType" SG_ 2631535509 UDSbyte2_UDSrequest_J1939_CTU 1;
BA_ "GenSigSendType" SG_ 2631535509 UDSbyte3_UDSrequest_J1939_CTU 1;
BA_ "GenSigSendType" SG_ 2631535509 UDSbyte4_UDSrequest_J1939_CTU 1;
BA_ "GenSigSendType" SG_ 2631535509 UDSbyte5_UDSrequest_J1939_CTU 1;
BA_ "GenSigSendType" SG_ 2631535509 UDSbyte6_UDSrequest_J1939_CTU 1;
BA_ "GenSigSendType" SG_ 2631535509 UDSbyte7_UDSrequest_J1939_CTU 1;
BA_ "GenSigSendType" SG_ 2631535509 UDSbyte8_UDSrequest_J1939_CTU 1;
BA_ "GenMsgILSupport" BO_ 2631535509 0;
BA_ "DiagResponse" BO_ 2564483083 1;
BA_ "DiagConnection" BO_ 2564483083 59403;
BA_ "VFrameFormat" BO_ 2564483083 1;
BA_ "GenSigSendType" SG_ 2564483083 UDSbyte1_UDSanswer 1;
BA_ "GenSigSendType" SG_ 2564483083 UDSbyte2_UDSanswer 1;
BA_ "GenSigSendType" SG_ 2564483083 UDSbyte3_UDSanswer 1;
BA_ "GenSigSendType" SG_ 2564483083 UDSbyte4_UDSanswer 1;
BA_ "GenSigSendType" SG_ 2564483083 UDSbyte5_UDSanswer 1;
BA_ "GenSigSendType" SG_ 2564483083 UDSbyte6_UDSanswer 1;
BA_ "GenSigSendType" SG_ 2564483083 UDSbyte7_UDSanswer 1;
BA_ "GenSigSendType" SG_ 2564483083 UDSbyte8_UDSanswer 1;
BA_ "GenMsgILSupport" BO_ 2564483083 0;
BA_ "DiagResponse" BO_ 2564487947 1;
BA_ "DiagConnection" BO_ 2564487947 64267;
BA_ "VFrameFormat" BO_ 2564487947 1;
BA_ "GenSigSendType" SG_ 2564487947 UDSbyte1_UDSanswer_TIM 1;
BA_ "GenSigSendType" SG_ 2564487947 UDSbyte2_UDSanswer_TIM 1;
BA_ "GenSigSendType" SG_ 2564487947 UDSbyte3_UDSanswer_TIM 1;
BA_ "GenSigSendType" SG_ 2564487947 UDSbyte4_UDSanswer_TIM 1;
BA_ "GenSigSendType" SG_ 2564487947 UDSbyte5_UDSanswer_TIM 1;
BA_ "GenSigSendType" SG_ 2564487947 UDSbyte6_UDSanswer_TIM 1;
BA_ "GenSigSendType" SG_ 2564487947 UDSbyte7_UDSanswer_TIM 1;
BA_ "GenSigSendType" SG_ 2564487947 UDSbyte8_UDSanswer_TIM 1;
BA_ "GenMsgILSupport" BO_ 2564487947 0;
BA_ "DiagResponse" BO_ 2631570699 1;
BA_ "DiagConnection" BO_ 2631570699 38155;
BA_ "VFrameFormat" BO_ 2631570699 1;
BA_ "GenSigSendType" SG_ 2631570699 UDSbyte1_UDSanswer_J1939_CTU 1;
BA_ "GenSigSendType" SG_ 2631570699 UDSbyte2_UDSanswer_J1939_CTU 1;
BA_ "GenSigSendType" SG_ 2631570699 UDSbyte3_UDSanswer_J1939_CTU 1;
BA_ "GenSigSendType" SG_ 2631570699 UDSbyte4_UDSanswer_J1939_CTU 1;
BA_ "GenSigSendType" SG_ 2631570699 UDSbyte5_UDSanswer_J1939_CTU 1;
BA_ "GenSigSendType" SG_ 2631570699 UDSbyte6_UDSanswer_J1939_CTU 1;
BA_ "GenSigSendType" SG_ 2631570699 UDSbyte7_UDSanswer_J1939_CTU 1;
BA_ "GenSigSendType" SG_ 2631570699 UDSbyte8_UDSanswer_J1939_CTU 1;
BA_ "GenMsgILSupport" BO_ 2631570699 0;
BA_ "VFrameFormat" BO_ 2559314938 1;
BA_ "GenSigSendType" SG_ 2559314938 XCPCmdB1_XCP_Cmd1 1;
BA_ "GenSigSendType" SG_ 2559314938 XCPCmdB2_XCP_Cmd1 1;
BA_ "GenSigSendType" SG_ 2559314938 XCPCmdB3_XCP_Cmd1 1;
BA_ "GenSigSendType" SG_ 2559314938 XCPCmdB4_XCP_Cmd1 1;
BA_ "GenSigSendType" SG_ 2559314938 XCPCmdB5_XCP_Cmd1 1;
BA_ "GenSigSendType" SG_ 2559314938 XCPCmdB6_XCP_Cmd1 1;
BA_ "GenSigSendType" SG_ 2559314938 XCPCmdB7_XCP_Cmd1 1;
BA_ "GenSigSendType" SG_ 2559314938 XCPCmdB8_XCP_Cmd1 1;
BA_ "GenMsgILSupport" BO_ 2559314938 0;
BA_ "VFrameFormat" BO_ 2559310347 1;
BA_ "GenSigSendType" SG_ 2559310347 XCPRspB1_XCP_Rsp1 1;
BA_ "GenSigSendType" SG_ 2559310347 XCPRspB2_XCP_Rsp1 1;
BA_ "GenSigSendType" SG_ 2559310347 XCPRspB3_XCP_Rsp1 1;
BA_ "GenSigSendType" SG_ 2559310347 XCPRspB4_XCP_Rsp1 1;
BA_ "GenSigSendType" SG_ 2559310347 XCPRspB5_XCP_Rsp1 1;
BA_ "GenSigSendType" SG_ 2559310347 XCPRspB6_XCP_Rsp1 1;
BA_ "GenSigSendType" SG_ 2559310347 XCPRspB7_XCP_Rsp1 1;
BA_ "GenSigSendType" SG_ 2559310347 XCPRspB8_XCP_Rsp1 1;
BA_ "GenMsgILSupport" BO_ 2559310347 0;
BA_ "VFrameFormat" BO_ 1792 0;
BA_ "GenSigSendType" SG_ 1792 PlantCloseLoop 1;
BA_ "GenSigSendType" SG_ 1792 PlantEBSmode 1;
BA_ "GenSigSendType" SG_ 1792 PlantCommon 1;
BA_ "GenSigSendType" SG_ 1792 PlantNoStimuli 1;
BA_ "GenSigSendType" SG_ 1792 PlantNoOffset 1;
BA_ "GenSigSendType" SG_ 1792 PlantReset 1;
BA_ "GenSigSendType" SG_ 1792 PlantNoProcess 1;
BA_ "GenSigSendType" SG_ 1792 PlantActive 1;
BA_ "GenSigSendType" SG_ 1792 PlantOutputId 1;
BA_ "GenSigSendType" SG_ 1792 PlantLowTimeRes 1;
BA_ "GenSigSendType" SG_ 1792 PlantSwitchSlow 1;
BA_ "GenSigSendType" SG_ 1792 PlantState 1;
BA_ "GenSigSendType" SG_ 1792 PlantTrigger 1;
BA_ "GenSigSendType" SG_ 1792 PlantNofPulses 1;
BA_ "GenSigSendType" SG_ 1792 PlantControlTime 1;
BA_ "GenSigSendType" SG_ 1792 PlantPauseTime 1;
BA_ "GenSigSendType" SG_ 1792 PlantTargetPres 1;
BA_ "VFrameFormat" BO_ 1793 0;
BA_ "GenSigSendType" SG_ 1793 P21Sim 1;
BA_ "GenSigSendType" SG_ 1793 P22Sim 1;
BA_ "GenSigSendType" SG_ 1793 P4Sim 1;
BA_ "GenSigSendType" SG_ 1793 AccYSim 1;
BA_ "GenSigSendType" SG_ 1793 P1Sim 1;
BA_ "GenSigSendType" SG_ 1793 P42Sim 1;
BA_ "VFrameFormat" BO_ 1794 0;
BA_ "GenSigSendType" SG_ 1794 ConfByte1 1;
BA_ "GenSigSendType" SG_ 1794 ConfByte2 1;
BA_ "GenSigSendType" SG_ 1794 ConfByte3 1;
BA_ "GenSigSendType" SG_ 1794 ConfByte4 1;
BA_ "GenSigSendType" SG_ 1794 ConfByte5 1;
BA_ "GenSigSendType" SG_ 1794 ConfByte6 1;
BA_ "GenSigSendType" SG_ 1794 ConfByte7 1;
BA_ "GenSigSendType" SG_ 1794 ConfByte8 1;
BA_ "VFrameFormat" BO_ 0 0;
BA_ "GenSigSendType" SG_ 0 PdemCh1 1;
BA_ "GenSigSendType" SG_ 0 PdemCh2 1;
BA_ "GenSigSendType" SG_ 0 Aux1Act 1;
BA_ "GenSigSendType" SG_ 0 Aux1Cap 1;
BA_ "GenSigSendType" SG_ 0 Aux1OC 1;
BA_ "GenSigSendType" SG_ 0 Aux1DIn 1;
BA_ "GenSigSendType" SG_ 0 Aux2Act 1;
BA_ "GenSigSendType" SG_ 0 Aux2Cap 1;
BA_ "GenSigSendType" SG_ 0 Aux2OC 1;
BA_ "GenSigSendType" SG_ 0 Aux2DIn 1;
BA_ "GenSigSendType" SG_ 0 Aux3Act 1;
BA_ "GenSigSendType" SG_ 0 Aux3Cap 1;
BA_ "GenSigSendType" SG_ 0 Aux3OC 1;
BA_ "GenSigSendType" SG_ 0 Aux3DIn 1;
BA_ "GenSigSendType" SG_ 0 Aux4Act 1;
BA_ "GenSigSendType" SG_ 0 Aux4Cap 1;
BA_ "GenSigSendType" SG_ 0 Aux4OC 1;
BA_ "GenSigSendType" SG_ 0 Aux4DIn 1;
BA_ "GenSigSendType" SG_ 0 Aux5Act 1;
BA_ "GenSigSendType" SG_ 0 Aux5Cap 1;
BA_ "GenSigSendType" SG_ 0 Aux5OC 1;
BA_ "GenSigSendType" SG_ 0 Aux5DIn 1;
BA_ "GenSigSendType" SG_ 0 Aux6Act 1;
BA_ "GenSigSendType" SG_ 0 Aux6Cap 1;
BA_ "GenSigSendType" SG_ 0 Aux6OC 1;
BA_ "GenSigSendType" SG_ 0 Aux6DIn 1;
BA_ "GenSigSendType" SG_ 0 Aux7Act 1;
BA_ "GenSigSendType" SG_ 0 Aux7Cap 1;
BA_ "GenSigSendType" SG_ 0 Aux7OC 1;
BA_ "GenSigSendType" SG_ 0 Aux7DIn 1;
BA_ "GenSigSendType" SG_ 0 Aux5PWM 1;
BA_ "GenSigSendType" SG_ 0 Aux6PWM 1;
BA_ "GenSigSendType" SG_ 0 Aux12PWM 1;
BA_ "GenSigSendType" SG_ 0 Aux3PWM 1;
BA_ "GenSigSendType" SG_ 0 Aux4PWM 1;
BA_ "GenSigSendType" SG_ 0 VehStnd 1;
BA_ "GenSigSendType" SG_ 0 AccStEn 1;
BA_ "GenSigSendType" SG_ 0 PsOfCEn 1;
BA_ "GenSigSendType" SG_ 0 SSup1Off 1;
BA_ "GenSigSendType" SG_ 0 SSup2Off 1;
BA_ "GenSigSendType" SG_ 0 SSup3Off 1;
BA_ "GenSigSendType" SG_ 0 SSup4Off 1;
BA_ "VFrameFormat" BO_ 272 0;
BA_ "GenSigSendType" SG_ 272 vRaw0 1;
BA_ "GenSigSendType" SG_ 272 nEdge0 1;
BA_ "GenSigSendType" SG_ 272 ErrCtr0 1;
BA_ "GenSigSendType" SG_ 272 vRaw1 1;
BA_ "GenSigSendType" SG_ 272 nEdge1 1;
BA_ "GenSigSendType" SG_ 272 ErrCtr1 1;
BA_ "VFrameFormat" BO_ 288 0;
BA_ "GenSigSendType" SG_ 288 Pact 1;
BA_ "GenSigSendType" SG_ 288 PactP4 1;
BA_ "GenSigInactiveValue" SG_ 288 AccY 2032;
BA_ "GenSigStartValue" SG_ 288 AccY 2032;
BA_ "GenSigSendType" SG_ 288 AccY 1;
BA_ "GenSigInactiveValue" SG_ 288 AccX 2032;
BA_ "GenSigStartValue" SG_ 288 AccX 2032;
BA_ "GenSigSendType" SG_ 288 AccX 1;
BA_ "GenSigSendType" SG_ 288 AnaMulti 1;
BA_ "GenSigSendType" SG_ 288 IdxMulti 1;
BA_ "GenSigSendType" SG_ 288 fWhl0 1;
BA_ "GenSigSendType" SG_ 288 fWhl1 1;
BA_ "GenSigSendType" SG_ 288 fComm 1;
BA_ "GenSigSendType" SG_ 288 fBckp 1;
BA_ "GenSigSendType" SG_ 288 fBabs 1;
BA_ "GenSigSendType" SG_ 288 fEbs 1;
BA_ "GenSigSendType" SG_ 288 fModule 1;
BA_ "VFrameFormat" BO_ 1 0;
BA_ "GenSigSendType" SG_ 1 CRC_E2E_iTEPM_Control_Tx 1;
BA_ "GenSigSendType" SG_ 1 Counter_E2E_iTEPM_Control_Tx 1;
BA_ "GenSigSendType" SG_ 1 Pdemand 1;
BA_ "GenSigSendType" SG_ 1 VehStnd 1;
BA_ "GenSigSendType" SG_ 1 AccStEn 1;
BA_ "GenSigSendType" SG_ 1 PsOfCEn 1;
BA_ "GenSigSendType" SG_ 1 SSup1Off 1;
BA_ "VFrameFormat" BO_ 273 0;
BA_ "GenSigSendType" SG_ 273 CRC_E2E 1;
BA_ "GenSigSendType" SG_ 273 Counter_E2E 1;
BA_ "GenSigSendType" SG_ 273 WhNaLeft 1;
BA_ "GenSigSendType" SG_ 273 vRawLeft 1;
BA_ "GenSigSendType" SG_ 273 nEdgeLeft 1;
BA_ "GenSigSendType" SG_ 273 ErrCtrLeft 1;
BA_ "GenSigInactiveValue" SG_ 273 AccSensAxis1_Lat 2032;
BA_ "GenSigStartValue" SG_ 273 AccSensAxis1_Lat 2032;
BA_ "GenSigSendType" SG_ 273 AccSensAxis1_Lat 1;
BA_ "VFrameFormat" BO_ 281 0;
BA_ "GenSigSendType" SG_ 281 CRC_E2E 1;
BA_ "GenSigSendType" SG_ 281 Counter_E2E 1;
BA_ "GenSigSendType" SG_ 281 WhNaRight 1;
BA_ "GenSigSendType" SG_ 281 vRawRight 1;
BA_ "GenSigSendType" SG_ 281 nEdgeRight 1;
BA_ "GenSigSendType" SG_ 281 ErrCtrRight 1;
BA_ "GenSigInactiveValue" SG_ 281 AccSensAxis2_Long 2032;
BA_ "GenSigStartValue" SG_ 281 AccSensAxis2_Long 2032;
BA_ "GenSigSendType" SG_ 281 AccSensAxis2_Long 1;
BA_ "VFrameFormat" BO_ 289 0;
BA_ "GenSigSendType" SG_ 289 CRC_E2E 1;
BA_ "GenSigSendType" SG_ 289 Counter_E2E 1;
BA_ "GenSigSendType" SG_ 289 Pact 1;
BA_ "GenSigSendType" SG_ 289 PactP4 1;
BA_ "GenSigSendType" SG_ 289 PactP42 1;
BA_ "GenSigSendType" SG_ 289 fComm 1;
BA_ "GenSigSendType" SG_ 289 fBckp 1;
BA_ "GenSigSendType" SG_ 289 fBabs 1;
BA_ "GenSigSendType" SG_ 289 fEbs 1;
BA_ "GenSigSendType" SG_ 289 fModule 1;
BA_ "GenMsgCycleTime" BO_ 2566849030 100;
BA_ "GenMsgSendType" BO_ 2566849030 0;
BA_ "VFrameFormat" BO_ 2566849030 1;
BA_ "GenSigSendType" SG_ 2566849030 SensorLocation 0;
BA_ "GenSigCycleTime" SG_ 2566849030 SensorLocation 100;
BA_ "GenSigSendType" SG_ 2566849030 DetectionZone 0;
BA_ "GenSigCycleTime" SG_ 2566849030 DetectionZone 100;
BA_ "GenSigSendType" SG_ 2566849030 FunctionalStatus 0;
BA_ "GenSigCycleTime" SG_ 2566849030 FunctionalStatus 100;
BA_ "GenSigSendType" SG_ 2566849030 ExtInputState 0;
BA_ "GenSigCycleTime" SG_ 2566849030 ExtInputState 100;
BA_ "GenSigSendType" SG_ 2566849030 DetectionBinStd 0;
BA_ "GenSigCycleTime" SG_ 2566849030 DetectionBinStd 100;
BA_ "GenSigSendType" SG_ 2566849030 SensTemperature 0;
BA_ "GenSigCycleTime" SG_ 2566849030 SensTemperature 100;
BA_ "GenSigSendType" SG_ 2566849030 LongDistanceX 0;
BA_ "GenSigCycleTime" SG_ 2566849030 LongDistanceX 100;
BA_ "GenSigSendType" SG_ 2566849030 LatDistanceY 0;
BA_ "GenSigCycleTime" SG_ 2566849030 LatDistanceY 100;
BA_ "GenMsgCycleTime" BO_ 2566850766 50;
BA_ "GenMsgSendType" BO_ 2566850766 0;
BA_ "VFrameFormat" BO_ 2566850766 1;
BA_ "GenSigSendType" SG_ 2566850766 rdc1BrIntvEna 0;
BA_ "GenSigCycleTime" SG_ 2566850766 rdc1BrIntvEna 50;
BA_ "GenSigSendType" SG_ 2566850766 rdc1BrDemJ1939 0;
BA_ "GenSigCycleTime" SG_ 2566850766 rdc1BrDemJ1939 50;
BA_ "GenSigSendType" SG_ 2566850766 rdc1VersionIndex 0;
BA_ "GenSigCycleTime" SG_ 2566850766 rdc1VersionIndex 50;
BA_ "GenSigSendType" SG_ 2566850766 rdc1VersionData 0;
BA_ "GenSigCycleTime" SG_ 2566850766 rdc1VersionData 50;
BA_ "GenSigSendType" SG_ 2566850766 rdc1ErrorCode 0;
BA_ "GenSigCycleTime" SG_ 2566850766 rdc1ErrorCode 50;
BA_ "GenSigSendType" SG_ 2566850766 rdc1Status 0;
BA_ "GenSigCycleTime" SG_ 2566850766 rdc1Status 50;
BA_ "GenSigSendType" SG_ 2566850766 rdc1CfgDataIdx 0;
BA_ "GenSigCycleTime" SG_ 2566850766 rdc1CfgDataIdx 50;
BA_ "GenSigSendType" SG_ 2566850766 rdc1MsgCntr 0;
BA_ "GenSigCycleTime" SG_ 2566850766 rdc1MsgCntr 50;
BA_ "GenSigSendType" SG_ 2566850766 rdc1MsgChksum 0;
BA_ "GenSigCycleTime" SG_ 2566850766 rdc1MsgChksum 50;
BA_ "GenMsgCycleTime" BO_ 2566851022 50;
BA_ "GenMsgSendType" BO_ 2566851022 0;
BA_ "VFrameFormat" BO_ 2566851022 1;
BA_ "GenSigSendType" SG_ 2566851022 rdc2Dist2SensorRL 0;
BA_ "GenSigCycleTime" SG_ 2566851022 rdc2Dist2SensorRL 50;
BA_ "GenSigSendType" SG_ 2566851022 rdc2Dist2SensorRCL 0;
BA_ "GenSigCycleTime" SG_ 2566851022 rdc2Dist2SensorRCL 50;
BA_ "GenSigSendType" SG_ 2566851022 rdc2Dist2SensorRCR 0;
BA_ "GenSigCycleTime" SG_ 2566851022 rdc2Dist2SensorRCR 50;
BA_ "GenSigSendType" SG_ 2566851022 rdc2Dist2SensorRR 0;
BA_ "GenSigCycleTime" SG_ 2566851022 rdc2Dist2SensorRR 50;
BA_ "GenSigSendType" SG_ 2566851022 rdc2Dist2SensorTR 0;
BA_ "GenSigCycleTime" SG_ 2566851022 rdc2Dist2SensorTR 50;
BA_ "GenSigSendType" SG_ 2566851022 rdc2Dist2SensorTL 0;
BA_ "GenSigCycleTime" SG_ 2566851022 rdc2Dist2SensorTL 50;
BA_ "GenSigSendType" SG_ 2566851022 rdc2RevSigState 0;
BA_ "GenSigCycleTime" SG_ 2566851022 rdc2RevSigState 50;
BA_ "GenSigSendType" SG_ 2566851022 rdc2RDCSystemEnabled 0;
BA_ "GenSigCycleTime" SG_ 2566851022 rdc2RDCSystemEnabled 50;
BA_ "GenSigSendType" SG_ 2566851022 rdc2MsgCntr 0;
BA_ "GenSigCycleTime" SG_ 2566851022 rdc2MsgCntr 50;
BA_ "GenSigSendType" SG_ 2566851022 rdc2MsgChksum 0;
BA_ "GenSigCycleTime" SG_ 2566851022 rdc2MsgChksum 50;
BA_ "VFrameFormat" BO_ 2566851016 1;
BA_ "GenSigSendType" SG_ 2566851016 rdc2CfgDataIdx 1;
BA_ "GenSigSendType" SG_ 2566851016 rdc2CfgDataVal 1;
BA_ "GenSigSendType" SG_ 2566851016 rdc2MsgCntrTx 1;
BA_ "GenSigSendType" SG_ 2566851016 rdc2MsgChksumTx 1;
BA_ "VFrameFormat" BO_ 2566851008 1;
BA_ "GenSigSendType" SG_ 2566851008 rdc2CfgDataIdx 1;
BA_ "GenSigSendType" SG_ 2566851008 rdc2CfgDataVal 1;
BA_ "GenSigSendType" SG_ 2566851008 rdc2MsgCntrTx 1;
BA_ "GenSigSendType" SG_ 2566851008 rdc2MsgChksumTx 1;
BA_ "VFrameFormat" BO_ 2566851000 1;
BA_ "GenSigSendType" SG_ 2566851000 rdc2CfgDataIdx 1;
BA_ "GenSigSendType" SG_ 2566851000 rdc2CfgDataVal 1;
BA_ "GenSigSendType" SG_ 2566851000 rdc2MsgCntrTx 1;
BA_ "GenSigSendType" SG_ 2566851000 rdc2MsgChksumTx 1;
BA_ "VFrameFormat" BO_ 2566850992 1;
BA_ "GenSigSendType" SG_ 2566850992 rdc2CfgDataIdx 1;
BA_ "GenSigSendType" SG_ 2566850992 rdc2CfgDataVal 1;
BA_ "GenSigSendType" SG_ 2566850992 rdc2MsgCntrTx 1;
BA_ "GenSigSendType" SG_ 2566850992 rdc2MsgChksumTx 1;
BA_ "VFrameFormat" BO_ 2566850984 1;
BA_ "GenSigSendType" SG_ 2566850984 rdc2CfgDataIdx 1;
BA_ "GenSigSendType" SG_ 2566850984 rdc2CfgDataVal 1;
BA_ "GenSigSendType" SG_ 2566850984 rdc2MsgCntrTx 1;
BA_ "GenSigSendType" SG_ 2566850984 rdc2MsgChksumTx 1;
BA_ "VFrameFormat" BO_ 2566850976 1;
BA_ "GenSigSendType" SG_ 2566850976 rdc2CfgDataIdx 1;
BA_ "GenSigSendType" SG_ 2566850976 rdc2CfgDataVal 1;
BA_ "GenSigSendType" SG_ 2566850976 rdc2MsgCntrTx 1;
BA_ "GenSigSendType" SG_ 2566850976 rdc2MsgChksumTx 1;
BA_ "VFrameFormat" BO_ 2566850968 1;
BA_ "GenSigSendType" SG_ 2566850968 rdc2CfgDataIdx 1;
BA_ "GenSigSendType" SG_ 2566850968 rdc2CfgDataVal 1;
BA_ "GenSigSendType" SG_ 2566850968 rdc2MsgCntrTx 1;
BA_ "GenSigSendType" SG_ 2566850968 rdc2MsgChksumTx 1;
BA_ "VFrameFormat" BO_ 2566850960 1;
BA_ "GenSigSendType" SG_ 2566850960 rdc2CfgDataIdx 1;
BA_ "GenSigSendType" SG_ 2566850960 rdc2CfgDataVal 1;
BA_ "GenSigSendType" SG_ 2566850960 rdc2MsgCntrTx 1;
BA_ "GenSigSendType" SG_ 2566850960 rdc2MsgChksumTx 1;
BA_ "VFrameFormat" BO_ 2566850952 1;
BA_ "GenSigSendType" SG_ 2566850952 rdc2CfgDataIdx 1;
BA_ "GenSigSendType" SG_ 2566850952 rdc2CfgDataVal 1;
BA_ "GenSigSendType" SG_ 2566850952 rdc2MsgCntrTx 1;
BA_ "GenSigSendType" SG_ 2566850952 rdc2MsgChksumTx 1;
BA_ "VFrameFormat" BO_ 2566850944 1;
BA_ "GenSigSendType" SG_ 2566850944 rdc2CfgDataIdx 1;
BA_ "GenSigSendType" SG_ 2566850944 rdc2CfgDataVal 1;
BA_ "GenSigSendType" SG_ 2566850944 rdc2MsgCntrTx 1;
BA_ "GenSigSendType" SG_ 2566850944 rdc2MsgChksumTx 1;
BA_ "VFrameFormat" BO_ 2566851784 1;
BA_ "GenSigSendType" SG_ 2566851784 rdc3DisableReq 1;
BA_ "GenSigSendType" SG_ 2566851784 rdc3TEBSStatus 1;
BA_ "GenSigSendType" SG_ 2566851784 rdc3MsgCntr 1;
BA_ "GenSigSendType" SG_ 2566851784 rdc3MsgChksum 1;
BA_ "VFrameFormat" BO_ 2566851776 1;
BA_ "GenSigSendType" SG_ 2566851776 rdc3DisableReq 1;
BA_ "GenSigSendType" SG_ 2566851776 rdc3TEBSStatus 1;
BA_ "GenSigSendType" SG_ 2566851776 rdc3MsgCntr 1;
BA_ "GenSigSendType" SG_ 2566851776 rdc3MsgChksum 1;
BA_ "VFrameFormat" BO_ 2566851768 1;
BA_ "GenSigSendType" SG_ 2566851768 rdc3DisableReq 1;
BA_ "GenSigSendType" SG_ 2566851768 rdc3TEBSStatus 1;
BA_ "GenSigSendType" SG_ 2566851768 rdc3MsgCntr 1;
BA_ "GenSigSendType" SG_ 2566851768 rdc3MsgChksum 1;
BA_ "VFrameFormat" BO_ 2566851760 1;
BA_ "GenSigSendType" SG_ 2566851760 rdc3DisableReq 1;
BA_ "GenSigSendType" SG_ 2566851760 rdc3TEBSStatus 1;
BA_ "GenSigSendType" SG_ 2566851760 rdc3MsgCntr 1;
BA_ "GenSigSendType" SG_ 2566851760 rdc3MsgChksum 1;
BA_ "VFrameFormat" BO_ 2566851752 1;
BA_ "GenSigSendType" SG_ 2566851752 rdc3DisableReq 1;
BA_ "GenSigSendType" SG_ 2566851752 rdc3TEBSStatus 1;
BA_ "GenSigSendType" SG_ 2566851752 rdc3MsgCntr 1;
BA_ "GenSigSendType" SG_ 2566851752 rdc3MsgChksum 1;
BA_ "VFrameFormat" BO_ 2566851744 1;
BA_ "GenSigSendType" SG_ 2566851744 rdc3DisableReq 1;
BA_ "GenSigSendType" SG_ 2566851744 rdc3TEBSStatus 1;
BA_ "GenSigSendType" SG_ 2566851744 rdc3MsgCntr 1;
BA_ "GenSigSendType" SG_ 2566851744 rdc3MsgChksum 1;
BA_ "VFrameFormat" BO_ 2566851736 1;
BA_ "GenSigSendType" SG_ 2566851736 rdc3DisableReq 1;
BA_ "GenSigSendType" SG_ 2566851736 rdc3TEBSStatus 1;
BA_ "GenSigSendType" SG_ 2566851736 rdc3MsgCntr 1;
BA_ "GenSigSendType" SG_ 2566851736 rdc3MsgChksum 1;
BA_ "VFrameFormat" BO_ 2566851728 1;
BA_ "GenSigSendType" SG_ 2566851728 rdc3DisableReq 1;
BA_ "GenSigSendType" SG_ 2566851728 rdc3TEBSStatus 1;
BA_ "GenSigSendType" SG_ 2566851728 rdc3MsgCntr 1;
BA_ "GenSigSendType" SG_ 2566851728 rdc3MsgChksum 1;
BA_ "VFrameFormat" BO_ 2566851720 1;
BA_ "GenSigSendType" SG_ 2566851720 rdc3DisableReq 1;
BA_ "GenSigSendType" SG_ 2566851720 rdc3TEBSStatus 1;
BA_ "GenSigSendType" SG_ 2566851720 rdc3MsgCntr 1;
BA_ "GenSigSendType" SG_ 2566851720 rdc3MsgChksum 1;
BA_ "VFrameFormat" BO_ 2566851712 1;
BA_ "GenSigSendType" SG_ 2566851712 rdc3DisableReq 1;
BA_ "GenSigSendType" SG_ 2566851712 rdc3TEBSStatus 1;
BA_ "GenSigSendType" SG_ 2566851712 rdc3MsgCntr 1;
BA_ "GenSigSendType" SG_ 2566851712 rdc3MsgChksum 1;
BA_ "VFrameFormat" BO_ 2566899968 1;
BA_ "GenSigSendType" SG_ 2566899968 ADLRxData0 1;
BA_ "GenSigSendType" SG_ 2566899968 ADLRxData1 1;
BA_ "GenSigSendType" SG_ 2566899968 ADLRxData2 1;
BA_ "GenSigSendType" SG_ 2566899968 ADLRxData3 1;
BA_ "GenSigSendType" SG_ 2566899968 ADLRxData4 1;
BA_ "GenSigSendType" SG_ 2566899968 ADLRxData5 1;
BA_ "GenSigSendType" SG_ 2566899968 ADLRxData6 1;
BA_ "GenSigSendType" SG_ 2566899968 ADLRxData7 1;
BA_ "VFrameFormat" BO_ 2566899912 1;
BA_ "GenSigSendType" SG_ 2566899912 ADLTxData0 1;
BA_ "GenSigSendType" SG_ 2566899912 ADLTxData1 1;
BA_ "GenSigSendType" SG_ 2566899912 ADLTxData2 1;
BA_ "GenSigSendType" SG_ 2566899912 ADLTxData3 1;
BA_ "GenSigSendType" SG_ 2566899912 ADLTxData4 1;
BA_ "GenSigSendType" SG_ 2566899912 ADLTxData5 1;
BA_ "GenSigSendType" SG_ 2566899912 ADLTxData6 1;
BA_ "GenSigSendType" SG_ 2566899912 ADLTxData7 1;
BA_ "VFrameFormat" BO_ 2566899904 1;
BA_ "GenSigSendType" SG_ 2566899904 ADLTxData0 1;
BA_ "GenSigSendType" SG_ 2566899904 ADLTxData1 1;
BA_ "GenSigSendType" SG_ 2566899904 ADLTxData2 1;
BA_ "GenSigSendType" SG_ 2566899904 ADLTxData3 1;
BA_ "GenSigSendType" SG_ 2566899904 ADLTxData4 1;
BA_ "GenSigSendType" SG_ 2566899904 ADLTxData5 1;
BA_ "GenSigSendType" SG_ 2566899904 ADLTxData6 1;
BA_ "GenSigSendType" SG_ 2566899904 ADLTxData7 1;
BA_ "VFrameFormat" BO_ 2566899896 1;
BA_ "GenSigSendType" SG_ 2566899896 ADLTxData0 1;
BA_ "GenSigSendType" SG_ 2566899896 ADLTxData1 1;
BA_ "GenSigSendType" SG_ 2566899896 ADLTxData2 1;
BA_ "GenSigSendType" SG_ 2566899896 ADLTxData3 1;
BA_ "GenSigSendType" SG_ 2566899896 ADLTxData4 1;
BA_ "GenSigSendType" SG_ 2566899896 ADLTxData5 1;
BA_ "GenSigSendType" SG_ 2566899896 ADLTxData6 1;
BA_ "GenSigSendType" SG_ 2566899896 ADLTxData7 1;
BA_ "VFrameFormat" BO_ 2566899888 1;
BA_ "GenSigSendType" SG_ 2566899888 ADLTxData0 1;
BA_ "GenSigSendType" SG_ 2566899888 ADLTxData1 1;
BA_ "GenSigSendType" SG_ 2566899888 ADLTxData2 1;
BA_ "GenSigSendType" SG_ 2566899888 ADLTxData3 1;
BA_ "GenSigSendType" SG_ 2566899888 ADLTxData4 1;
BA_ "GenSigSendType" SG_ 2566899888 ADLTxData5 1;
BA_ "GenSigSendType" SG_ 2566899888 ADLTxData6 1;
BA_ "GenSigSendType" SG_ 2566899888 ADLTxData7 1;
BA_ "VFrameFormat" BO_ 2566899880 1;
BA_ "GenSigSendType" SG_ 2566899880 ADLTxData0 1;
BA_ "GenSigSendType" SG_ 2566899880 ADLTxData1 1;
BA_ "GenSigSendType" SG_ 2566899880 ADLTxData2 1;
BA_ "GenSigSendType" SG_ 2566899880 ADLTxData3 1;
BA_ "GenSigSendType" SG_ 2566899880 ADLTxData4 1;
BA_ "GenSigSendType" SG_ 2566899880 ADLTxData5 1;
BA_ "GenSigSendType" SG_ 2566899880 ADLTxData6 1;
BA_ "GenSigSendType" SG_ 2566899880 ADLTxData7 1;
BA_ "VFrameFormat" BO_ 2566899872 1;
BA_ "GenSigSendType" SG_ 2566899872 ADLTxData0 1;
BA_ "GenSigSendType" SG_ 2566899872 ADLTxData1 1;
BA_ "GenSigSendType" SG_ 2566899872 ADLTxData2 1;
BA_ "GenSigSendType" SG_ 2566899872 ADLTxData3 1;
BA_ "GenSigSendType" SG_ 2566899872 ADLTxData4 1;
BA_ "GenSigSendType" SG_ 2566899872 ADLTxData5 1;
BA_ "GenSigSendType" SG_ 2566899872 ADLTxData6 1;
BA_ "GenSigSendType" SG_ 2566899872 ADLTxData7 1;
BA_ "VFrameFormat" BO_ 2566899864 1;
BA_ "GenSigSendType" SG_ 2566899864 ADLTxData0 1;
BA_ "GenSigSendType" SG_ 2566899864 ADLTxData1 1;
BA_ "GenSigSendType" SG_ 2566899864 ADLTxData2 1;
BA_ "GenSigSendType" SG_ 2566899864 ADLTxData3 1;
BA_ "GenSigSendType" SG_ 2566899864 ADLTxData4 1;
BA_ "GenSigSendType" SG_ 2566899864 ADLTxData5 1;
BA_ "GenSigSendType" SG_ 2566899864 ADLTxData6 1;
BA_ "GenSigSendType" SG_ 2566899864 ADLTxData7 1;
BA_ "VFrameFormat" BO_ 2566899856 1;
BA_ "GenSigSendType" SG_ 2566899856 ADLTxData0 1;
BA_ "GenSigSendType" SG_ 2566899856 ADLTxData1 1;
BA_ "GenSigSendType" SG_ 2566899856 ADLTxData2 1;
BA_ "GenSigSendType" SG_ 2566899856 ADLTxData3 1;
BA_ "GenSigSendType" SG_ 2566899856 ADLTxData4 1;
BA_ "GenSigSendType" SG_ 2566899856 ADLTxData5 1;
BA_ "GenSigSendType" SG_ 2566899856 ADLTxData6 1;
BA_ "GenSigSendType" SG_ 2566899856 ADLTxData7 1;
BA_ "VFrameFormat" BO_ 2566899848 1;
BA_ "GenSigSendType" SG_ 2566899848 ADLTxData0 1;
BA_ "GenSigSendType" SG_ 2566899848 ADLTxData1 1;
BA_ "GenSigSendType" SG_ 2566899848 ADLTxData2 1;
BA_ "GenSigSendType" SG_ 2566899848 ADLTxData3 1;
BA_ "GenSigSendType" SG_ 2566899848 ADLTxData4 1;
BA_ "GenSigSendType" SG_ 2566899848 ADLTxData5 1;
BA_ "GenSigSendType" SG_ 2566899848 ADLTxData6 1;
BA_ "GenSigSendType" SG_ 2566899848 ADLTxData7 1;
BA_ "VFrameFormat" BO_ 2566899840 1;
BA_ "GenSigSendType" SG_ 2566899840 ADLTxData0 1;
BA_ "GenSigSendType" SG_ 2566899840 ADLTxData1 1;
BA_ "GenSigSendType" SG_ 2566899840 ADLTxData2 1;
BA_ "GenSigSendType" SG_ 2566899840 ADLTxData3 1;
BA_ "GenSigSendType" SG_ 2566899840 ADLTxData4 1;
BA_ "GenSigSendType" SG_ 2566899840 ADLTxData5 1;
BA_ "GenSigSendType" SG_ 2566899840 ADLTxData6 1;
BA_ "GenSigSendType" SG_ 2566899840 ADLTxData7 1;
BA_ "VFrameFormat" BO_ 2566759880 1;
BA_ "GenSigSendType" SG_ 2566759880 StaDoor1 1;
BA_ "VFrameFormat" BO_ 2566759872 1;
BA_ "GenSigSendType" SG_ 2566759872 StaDoor1 1;
BA_ "VFrameFormat" BO_ 2566759864 1;
BA_ "GenSigSendType" SG_ 2566759864 StaDoor1 1;
BA_ "VFrameFormat" BO_ 2566759856 1;
BA_ "GenSigSendType" SG_ 2566759856 StaDoor1 1;
BA_ "VFrameFormat" BO_ 2566759848 1;
BA_ "GenSigSendType" SG_ 2566759848 StaDoor1 1;
BA_ "VFrameFormat" BO_ 2566759840 1;
BA_ "GenSigSendType" SG_ 2566759840 StaDoor1 1;
BA_ "VFrameFormat" BO_ 2566759832 1;
BA_ "GenSigSendType" SG_ 2566759832 StaDoor1 1;
BA_ "VFrameFormat" BO_ 2566759824 1;
BA_ "GenSigSendType" SG_ 2566759824 StaDoor1 1;
BA_ "VFrameFormat" BO_ 2566759816 1;
BA_ "GenSigSendType" SG_ 2566759816 StaDoor1 1;
BA_ "VFrameFormat" BO_ 2566759808 1;
BA_ "GenSigSendType" SG_ 2566759808 StaDoor1 1;
BA_ "VFrameFormat" BO_ 2566856904 1;
BA_ "GenSigSendType" SG_ 2566856904 PSys 1;
BA_ "GenSigSendType" SG_ 2566856904 PPneuDem 1;
BA_ "GenSigSendType" SG_ 2566856904 PElDemPress 1;
BA_ "GenSigSendType" SG_ 2566856904 GrossLoadPrc 1;
BA_ "GenSigSendType" SG_ 2566856904 PPneuCh0 1;
BA_ "GenSigSendType" SG_ 2566856904 PPneuCh1 1;
BA_ "GenSigSendType" SG_ 2566856904 PPneuCh2 1;
BA_ "VFrameFormat" BO_ 2566856896 1;
BA_ "GenSigSendType" SG_ 2566856896 PSys 1;
BA_ "GenSigSendType" SG_ 2566856896 PPneuDem 1;
BA_ "GenSigSendType" SG_ 2566856896 PElDemPress 1;
BA_ "GenSigSendType" SG_ 2566856896 GrossLoadPrc 1;
BA_ "GenSigSendType" SG_ 2566856896 PPneuCh0 1;
BA_ "GenSigSendType" SG_ 2566856896 PPneuCh1 1;
BA_ "GenSigSendType" SG_ 2566856896 PPneuCh2 1;
BA_ "VFrameFormat" BO_ 2566856888 1;
BA_ "GenSigSendType" SG_ 2566856888 PSys 1;
BA_ "GenSigSendType" SG_ 2566856888 PPneuDem 1;
BA_ "GenSigSendType" SG_ 2566856888 PElDemPress 1;
BA_ "GenSigSendType" SG_ 2566856888 GrossLoadPrc 1;
BA_ "GenSigSendType" SG_ 2566856888 PPneuCh0 1;
BA_ "GenSigSendType" SG_ 2566856888 PPneuCh1 1;
BA_ "GenSigSendType" SG_ 2566856888 PPneuCh2 1;
BA_ "VFrameFormat" BO_ 2566856880 1;
BA_ "GenSigSendType" SG_ 2566856880 PSys 1;
BA_ "GenSigSendType" SG_ 2566856880 PPneuDem 1;
BA_ "GenSigSendType" SG_ 2566856880 PElDemPress 1;
BA_ "GenSigSendType" SG_ 2566856880 GrossLoadPrc 1;
BA_ "GenSigSendType" SG_ 2566856880 PPneuCh0 1;
BA_ "GenSigSendType" SG_ 2566856880 PPneuCh1 1;
BA_ "GenSigSendType" SG_ 2566856880 PPneuCh2 1;
BA_ "VFrameFormat" BO_ 2566856872 1;
BA_ "GenSigSendType" SG_ 2566856872 PSys 1;
BA_ "GenSigSendType" SG_ 2566856872 PPneuDem 1;
BA_ "GenSigSendType" SG_ 2566856872 PElDemPress 1;
BA_ "GenSigSendType" SG_ 2566856872 GrossLoadPrc 1;
BA_ "GenSigSendType" SG_ 2566856872 PPneuCh0 1;
BA_ "GenSigSendType" SG_ 2566856872 PPneuCh1 1;
BA_ "GenSigSendType" SG_ 2566856872 PPneuCh2 1;
BA_ "VFrameFormat" BO_ 2566856864 1;
BA_ "GenSigSendType" SG_ 2566856864 PSys 1;
BA_ "GenSigSendType" SG_ 2566856864 PPneuDem 1;
BA_ "GenSigSendType" SG_ 2566856864 PElDemPress 1;
BA_ "GenSigSendType" SG_ 2566856864 GrossLoadPrc 1;
BA_ "GenSigSendType" SG_ 2566856864 PPneuCh0 1;
BA_ "GenSigSendType" SG_ 2566856864 PPneuCh1 1;
BA_ "GenSigSendType" SG_ 2566856864 PPneuCh2 1;
BA_ "VFrameFormat" BO_ 2566856856 1;
BA_ "GenSigSendType" SG_ 2566856856 PSys 1;
BA_ "GenSigSendType" SG_ 2566856856 PPneuDem 1;
BA_ "GenSigSendType" SG_ 2566856856 PElDemPress 1;
BA_ "GenSigSendType" SG_ 2566856856 GrossLoadPrc 1;
BA_ "GenSigSendType" SG_ 2566856856 PPneuCh0 1;
BA_ "GenSigSendType" SG_ 2566856856 PPneuCh1 1;
BA_ "GenSigSendType" SG_ 2566856856 PPneuCh2 1;
BA_ "VFrameFormat" BO_ 2566856848 1;
BA_ "GenSigSendType" SG_ 2566856848 PSys 1;
BA_ "GenSigSendType" SG_ 2566856848 PPneuDem 1;
BA_ "GenSigSendType" SG_ 2566856848 PElDemPress 1;
BA_ "GenSigSendType" SG_ 2566856848 GrossLoadPrc 1;
BA_ "GenSigSendType" SG_ 2566856848 PPneuCh0 1;
BA_ "GenSigSendType" SG_ 2566856848 PPneuCh1 1;
BA_ "GenSigSendType" SG_ 2566856848 PPneuCh2 1;
BA_ "VFrameFormat" BO_ 2566856840 1;
BA_ "GenSigSendType" SG_ 2566856840 PSys 1;
BA_ "GenSigSendType" SG_ 2566856840 PPneuDem 1;
BA_ "GenSigSendType" SG_ 2566856840 PElDemPress 1;
BA_ "GenSigSendType" SG_ 2566856840 GrossLoadPrc 1;
BA_ "GenSigSendType" SG_ 2566856840 PPneuCh0 1;
BA_ "GenSigSendType" SG_ 2566856840 PPneuCh1 1;
BA_ "GenSigSendType" SG_ 2566856840 PPneuCh2 1;
BA_ "VFrameFormat" BO_ 2566856832 1;
BA_ "GenSigSendType" SG_ 2566856832 PSys 1;
BA_ "GenSigSendType" SG_ 2566856832 PPneuDem 1;
BA_ "GenSigSendType" SG_ 2566856832 PElDemPress 1;
BA_ "GenSigSendType" SG_ 2566856832 GrossLoadPrc 1;
BA_ "GenSigSendType" SG_ 2566856832 PPneuCh0 1;
BA_ "GenSigSendType" SG_ 2566856832 PPneuCh1 1;
BA_ "GenSigSendType" SG_ 2566856832 PPneuCh2 1;
BA_ "VFrameFormat" BO_ 2566857160 1;
BA_ "GenSigSendType" SG_ 2566857160 vVeh 1;
BA_ "GenSigSendType" SG_ 2566857160 vWhl0 1;
BA_ "GenSigSendType" SG_ 2566857160 vWhl1 1;
BA_ "GenSigSendType" SG_ 2566857160 vWhl2 1;
BA_ "GenSigSendType" SG_ 2566857160 vWhl3 1;
BA_ "GenSigSendType" SG_ 2566857160 StABSCh0 1;
BA_ "GenSigSendType" SG_ 2566857160 StABSCh1 1;
BA_ "GenSigSendType" SG_ 2566857160 StABSCh2 1;
BA_ "VFrameFormat" BO_ 2566857152 1;
BA_ "GenSigSendType" SG_ 2566857152 vVeh 1;
BA_ "GenSigSendType" SG_ 2566857152 vWhl0 1;
BA_ "GenSigSendType" SG_ 2566857152 vWhl1 1;
BA_ "GenSigSendType" SG_ 2566857152 vWhl2 1;
BA_ "GenSigSendType" SG_ 2566857152 vWhl3 1;
BA_ "GenSigSendType" SG_ 2566857152 StABSCh0 1;
BA_ "GenSigSendType" SG_ 2566857152 StABSCh1 1;
BA_ "GenSigSendType" SG_ 2566857152 StABSCh2 1;
BA_ "VFrameFormat" BO_ 2566857144 1;
BA_ "GenSigSendType" SG_ 2566857144 vVeh 1;
BA_ "GenSigSendType" SG_ 2566857144 vWhl0 1;
BA_ "GenSigSendType" SG_ 2566857144 vWhl1 1;
BA_ "GenSigSendType" SG_ 2566857144 vWhl2 1;
BA_ "GenSigSendType" SG_ 2566857144 vWhl3 1;
BA_ "GenSigSendType" SG_ 2566857144 StABSCh0 1;
BA_ "GenSigSendType" SG_ 2566857144 StABSCh1 1;
BA_ "GenSigSendType" SG_ 2566857144 StABSCh2 1;
BA_ "VFrameFormat" BO_ 2566857136 1;
BA_ "GenSigSendType" SG_ 2566857136 vVeh 1;
BA_ "GenSigSendType" SG_ 2566857136 vWhl0 1;
BA_ "GenSigSendType" SG_ 2566857136 vWhl1 1;
BA_ "GenSigSendType" SG_ 2566857136 vWhl2 1;
BA_ "GenSigSendType" SG_ 2566857136 vWhl3 1;
BA_ "GenSigSendType" SG_ 2566857136 StABSCh0 1;
BA_ "GenSigSendType" SG_ 2566857136 StABSCh1 1;
BA_ "GenSigSendType" SG_ 2566857136 StABSCh2 1;
BA_ "VFrameFormat" BO_ 2566857128 1;
BA_ "GenSigSendType" SG_ 2566857128 vVeh 1;
BA_ "GenSigSendType" SG_ 2566857128 vWhl0 1;
BA_ "GenSigSendType" SG_ 2566857128 vWhl1 1;
BA_ "GenSigSendType" SG_ 2566857128 vWhl2 1;
BA_ "GenSigSendType" SG_ 2566857128 vWhl3 1;
BA_ "GenSigSendType" SG_ 2566857128 StABSCh0 1;
BA_ "GenSigSendType" SG_ 2566857128 StABSCh1 1;
BA_ "GenSigSendType" SG_ 2566857128 StABSCh2 1;
BA_ "VFrameFormat" BO_ 2566857120 1;
BA_ "GenSigSendType" SG_ 2566857120 vVeh 1;
BA_ "GenSigSendType" SG_ 2566857120 vWhl0 1;
BA_ "GenSigSendType" SG_ 2566857120 vWhl1 1;
BA_ "GenSigSendType" SG_ 2566857120 vWhl2 1;
BA_ "GenSigSendType" SG_ 2566857120 vWhl3 1;
BA_ "GenSigSendType" SG_ 2566857120 StABSCh0 1;
BA_ "GenSigSendType" SG_ 2566857120 StABSCh1 1;
BA_ "GenSigSendType" SG_ 2566857120 StABSCh2 1;
BA_ "VFrameFormat" BO_ 2566857112 1;
BA_ "GenSigSendType" SG_ 2566857112 vVeh 1;
BA_ "GenSigSendType" SG_ 2566857112 vWhl0 1;
BA_ "GenSigSendType" SG_ 2566857112 vWhl1 1;
BA_ "GenSigSendType" SG_ 2566857112 vWhl2 1;
BA_ "GenSigSendType" SG_ 2566857112 vWhl3 1;
BA_ "GenSigSendType" SG_ 2566857112 StABSCh0 1;
BA_ "GenSigSendType" SG_ 2566857112 StABSCh1 1;
BA_ "GenSigSendType" SG_ 2566857112 StABSCh2 1;
BA_ "VFrameFormat" BO_ 2566857104 1;
BA_ "GenSigSendType" SG_ 2566857104 vVeh 1;
BA_ "GenSigSendType" SG_ 2566857104 vWhl0 1;
BA_ "GenSigSendType" SG_ 2566857104 vWhl1 1;
BA_ "GenSigSendType" SG_ 2566857104 vWhl2 1;
BA_ "GenSigSendType" SG_ 2566857104 vWhl3 1;
BA_ "GenSigSendType" SG_ 2566857104 StABSCh0 1;
BA_ "GenSigSendType" SG_ 2566857104 StABSCh1 1;
BA_ "GenSigSendType" SG_ 2566857104 StABSCh2 1;
BA_ "VFrameFormat" BO_ 2566857096 1;
BA_ "GenSigSendType" SG_ 2566857096 vVeh 1;
BA_ "GenSigSendType" SG_ 2566857096 vWhl0 1;
BA_ "GenSigSendType" SG_ 2566857096 vWhl1 1;
BA_ "GenSigSendType" SG_ 2566857096 vWhl2 1;
BA_ "GenSigSendType" SG_ 2566857096 vWhl3 1;
BA_ "GenSigSendType" SG_ 2566857096 StABSCh0 1;
BA_ "GenSigSendType" SG_ 2566857096 StABSCh1 1;
BA_ "GenSigSendType" SG_ 2566857096 StABSCh2 1;
BA_ "VFrameFormat" BO_ 2566857088 1;
BA_ "GenSigSendType" SG_ 2566857088 vVeh 1;
BA_ "GenSigSendType" SG_ 2566857088 vWhl0 1;
BA_ "GenSigSendType" SG_ 2566857088 vWhl1 1;
BA_ "GenSigSendType" SG_ 2566857088 vWhl2 1;
BA_ "GenSigSendType" SG_ 2566857088 vWhl3 1;
BA_ "GenSigSendType" SG_ 2566857088 StABSCh0 1;
BA_ "GenSigSendType" SG_ 2566857088 StABSCh1 1;
BA_ "GenSigSendType" SG_ 2566857088 StABSCh2 1;
BA_ "VFrameFormat" BO_ 2566857416 1;
BA_ "GenSigSendType" SG_ 2566857416 RSP_TestPulse 1;
BA_ "GenSigSendType" SG_ 2566857416 RSP_Step_1 1;
BA_ "GenSigSendType" SG_ 2566857416 RSP_Step_2 1;
BA_ "GenSigSendType" SG_ 2566857416 RSP_Step_3 1;
BA_ "GenSigInactiveValue" SG_ 2566857416 Lateral_Accel 32127;
BA_ "GenSigStartValue" SG_ 2566857416 Lateral_Accel 32127;
BA_ "GenSigSendType" SG_ 2566857416 Lateral_Accel 1;
BA_ "GenSigInactiveValue" SG_ 2566857416 AyOffset 128;
BA_ "GenSigStartValue" SG_ 2566857416 AyOffset 128;
BA_ "GenSigSendType" SG_ 2566857416 AyOffset 1;
BA_ "GenSigSendType" SG_ 2566857416 AyLimit 1;
BA_ "GenSigSendType" SG_ 2566857416 TxTask10msRuntime 1;
BA_ "VFrameFormat" BO_ 2566857408 1;
BA_ "GenSigSendType" SG_ 2566857408 RSP_TestPulse 1;
BA_ "GenSigSendType" SG_ 2566857408 RSP_Step_1 1;
BA_ "GenSigSendType" SG_ 2566857408 RSP_Step_2 1;
BA_ "GenSigSendType" SG_ 2566857408 RSP_Step_3 1;
BA_ "GenSigInactiveValue" SG_ 2566857408 Lateral_Accel 32127;
BA_ "GenSigStartValue" SG_ 2566857408 Lateral_Accel 32127;
BA_ "GenSigSendType" SG_ 2566857408 Lateral_Accel 1;
BA_ "GenSigInactiveValue" SG_ 2566857408 AyOffset 128;
BA_ "GenSigStartValue" SG_ 2566857408 AyOffset 128;
BA_ "GenSigSendType" SG_ 2566857408 AyOffset 1;
BA_ "GenSigSendType" SG_ 2566857408 AyLimit 1;
BA_ "GenSigSendType" SG_ 2566857408 TxTask10msRuntime 1;
BA_ "VFrameFormat" BO_ 2566857400 1;
BA_ "GenSigSendType" SG_ 2566857400 RSP_TestPulse 1;
BA_ "GenSigSendType" SG_ 2566857400 RSP_Step_1 1;
BA_ "GenSigSendType" SG_ 2566857400 RSP_Step_2 1;
BA_ "GenSigSendType" SG_ 2566857400 RSP_Step_3 1;
BA_ "GenSigInactiveValue" SG_ 2566857400 Lateral_Accel 32127;
BA_ "GenSigStartValue" SG_ 2566857400 Lateral_Accel 32127;
BA_ "GenSigSendType" SG_ 2566857400 Lateral_Accel 1;
BA_ "GenSigInactiveValue" SG_ 2566857400 AyOffset 128;
BA_ "GenSigStartValue" SG_ 2566857400 AyOffset 128;
BA_ "GenSigSendType" SG_ 2566857400 AyOffset 1;
BA_ "GenSigSendType" SG_ 2566857400 AyLimit 1;
BA_ "GenSigSendType" SG_ 2566857400 TxTask10msRuntime 1;
BA_ "VFrameFormat" BO_ 2566857392 1;
BA_ "GenSigSendType" SG_ 2566857392 RSP_TestPulse 1;
BA_ "GenSigSendType" SG_ 2566857392 RSP_Step_1 1;
BA_ "GenSigSendType" SG_ 2566857392 RSP_Step_2 1;
BA_ "GenSigSendType" SG_ 2566857392 RSP_Step_3 1;
BA_ "GenSigInactiveValue" SG_ 2566857392 Lateral_Accel 32127;
BA_ "GenSigStartValue" SG_ 2566857392 Lateral_Accel 32127;
BA_ "GenSigSendType" SG_ 2566857392 Lateral_Accel 1;
BA_ "GenSigInactiveValue" SG_ 2566857392 AyOffset 128;
BA_ "GenSigStartValue" SG_ 2566857392 AyOffset 128;
BA_ "GenSigSendType" SG_ 2566857392 AyOffset 1;
BA_ "GenSigSendType" SG_ 2566857392 AyLimit 1;
BA_ "GenSigSendType" SG_ 2566857392 TxTask10msRuntime 1;
BA_ "VFrameFormat" BO_ 2566857384 1;
BA_ "GenSigSendType" SG_ 2566857384 RSP_TestPulse 1;
BA_ "GenSigSendType" SG_ 2566857384 RSP_Step_1 1;
BA_ "GenSigSendType" SG_ 2566857384 RSP_Step_2 1;
BA_ "GenSigSendType" SG_ 2566857384 RSP_Step_3 1;
BA_ "GenSigInactiveValue" SG_ 2566857384 Lateral_Accel 32127;
BA_ "GenSigStartValue" SG_ 2566857384 Lateral_Accel 32127;
BA_ "GenSigSendType" SG_ 2566857384 Lateral_Accel 1;
BA_ "GenSigInactiveValue" SG_ 2566857384 AyOffset 128;
BA_ "GenSigStartValue" SG_ 2566857384 AyOffset 128;
BA_ "GenSigSendType" SG_ 2566857384 AyOffset 1;
BA_ "GenSigSendType" SG_ 2566857384 AyLimit 1;
BA_ "GenSigSendType" SG_ 2566857384 TxTask10msRuntime 1;
BA_ "VFrameFormat" BO_ 2566857376 1;
BA_ "GenSigSendType" SG_ 2566857376 RSP_TestPulse 1;
BA_ "GenSigSendType" SG_ 2566857376 RSP_Step_1 1;
BA_ "GenSigSendType" SG_ 2566857376 RSP_Step_2 1;
BA_ "GenSigSendType" SG_ 2566857376 RSP_Step_3 1;
BA_ "GenSigInactiveValue" SG_ 2566857376 Lateral_Accel 32127;
BA_ "GenSigStartValue" SG_ 2566857376 Lateral_Accel 32127;
BA_ "GenSigSendType" SG_ 2566857376 Lateral_Accel 1;
BA_ "GenSigInactiveValue" SG_ 2566857376 AyOffset 128;
BA_ "GenSigStartValue" SG_ 2566857376 AyOffset 128;
BA_ "GenSigSendType" SG_ 2566857376 AyOffset 1;
BA_ "GenSigSendType" SG_ 2566857376 AyLimit 1;
BA_ "GenSigSendType" SG_ 2566857376 TxTask10msRuntime 1;
BA_ "VFrameFormat" BO_ 2566857368 1;
BA_ "GenSigSendType" SG_ 2566857368 RSP_TestPulse 1;
BA_ "GenSigSendType" SG_ 2566857368 RSP_Step_1 1;
BA_ "GenSigSendType" SG_ 2566857368 RSP_Step_2 1;
BA_ "GenSigSendType" SG_ 2566857368 RSP_Step_3 1;
BA_ "GenSigInactiveValue" SG_ 2566857368 Lateral_Accel 32127;
BA_ "GenSigStartValue" SG_ 2566857368 Lateral_Accel 32127;
BA_ "GenSigSendType" SG_ 2566857368 Lateral_Accel 1;
BA_ "GenSigInactiveValue" SG_ 2566857368 AyOffset 128;
BA_ "GenSigStartValue" SG_ 2566857368 AyOffset 128;
BA_ "GenSigSendType" SG_ 2566857368 AyOffset 1;
BA_ "GenSigSendType" SG_ 2566857368 AyLimit 1;
BA_ "GenSigSendType" SG_ 2566857368 TxTask10msRuntime 1;
BA_ "VFrameFormat" BO_ 2566857360 1;
BA_ "GenSigSendType" SG_ 2566857360 RSP_TestPulse 1;
BA_ "GenSigSendType" SG_ 2566857360 RSP_Step_1 1;
BA_ "GenSigSendType" SG_ 2566857360 RSP_Step_2 1;
BA_ "GenSigSendType" SG_ 2566857360 RSP_Step_3 1;
BA_ "GenSigInactiveValue" SG_ 2566857360 Lateral_Accel 32127;
BA_ "GenSigStartValue" SG_ 2566857360 Lateral_Accel 32127;
BA_ "GenSigSendType" SG_ 2566857360 Lateral_Accel 1;
BA_ "GenSigInactiveValue" SG_ 2566857360 AyOffset 128;
BA_ "GenSigStartValue" SG_ 2566857360 AyOffset 128;
BA_ "GenSigSendType" SG_ 2566857360 AyOffset 1;
BA_ "GenSigSendType" SG_ 2566857360 AyLimit 1;
BA_ "GenSigSendType" SG_ 2566857360 TxTask10msRuntime 1;
BA_ "VFrameFormat" BO_ 2566857352 1;
BA_ "GenSigSendType" SG_ 2566857352 RSP_TestPulse 1;
BA_ "GenSigSendType" SG_ 2566857352 RSP_Step_1 1;
BA_ "GenSigSendType" SG_ 2566857352 RSP_Step_2 1;
BA_ "GenSigSendType" SG_ 2566857352 RSP_Step_3 1;
BA_ "GenSigInactiveValue" SG_ 2566857352 Lateral_Accel 32127;
BA_ "GenSigStartValue" SG_ 2566857352 Lateral_Accel 32127;
BA_ "GenSigSendType" SG_ 2566857352 Lateral_Accel 1;
BA_ "GenSigInactiveValue" SG_ 2566857352 AyOffset 128;
BA_ "GenSigStartValue" SG_ 2566857352 AyOffset 128;
BA_ "GenSigSendType" SG_ 2566857352 AyOffset 1;
BA_ "GenSigSendType" SG_ 2566857352 AyLimit 1;
BA_ "GenSigSendType" SG_ 2566857352 TxTask10msRuntime 1;
BA_ "VFrameFormat" BO_ 2566857344 1;
BA_ "GenSigSendType" SG_ 2566857344 RSP_TestPulse 1;
BA_ "GenSigSendType" SG_ 2566857344 RSP_Step_1 1;
BA_ "GenSigSendType" SG_ 2566857344 RSP_Step_2 1;
BA_ "GenSigSendType" SG_ 2566857344 RSP_Step_3 1;
BA_ "GenSigInactiveValue" SG_ 2566857344 Lateral_Accel 32127;
BA_ "GenSigStartValue" SG_ 2566857344 Lateral_Accel 32127;
BA_ "GenSigSendType" SG_ 2566857344 Lateral_Accel 1;
BA_ "GenSigInactiveValue" SG_ 2566857344 AyOffset 128;
BA_ "GenSigStartValue" SG_ 2566857344 AyOffset 128;
BA_ "GenSigSendType" SG_ 2566857344 AyOffset 1;
BA_ "GenSigSendType" SG_ 2566857344 AyLimit 1;
BA_ "GenSigSendType" SG_ 2566857344 TxTask10msRuntime 1;
BA_ "VFrameFormat" BO_ 2566857672 1;
BA_ "GenSigSendType" SG_ 2566857672 ABS_Active 1;
BA_ "GenSigSendType" SG_ 2566857672 RSP_Active 1;
BA_ "GenSigSendType" SG_ 2566857672 EMR_Active 1;
BA_ "GenSigSendType" SG_ 2566857672 VDC_Active 1;
BA_ "GenSigSendType" SG_ 2566857672 DefABSConf 1;
BA_ "GenSigSendType" SG_ 2566857672 ActABSConf 1;
BA_ "GenSigSendType" SG_ 2566857672 SysStatus 1;
BA_ "GenSigSendType" SG_ 2566857672 RedWLReq_PGN65315_Tx 1;
BA_ "GenSigSendType" SG_ 2566857672 AmbWLReq_PGN65315_Tx 1;
BA_ "GenSigSendType" SG_ 2566857672 AmbInfReq 1;
BA_ "VFrameFormat" BO_ 2566857664 1;
BA_ "GenSigSendType" SG_ 2566857664 ABS_Active 1;
BA_ "GenSigSendType" SG_ 2566857664 RSP_Active 1;
BA_ "GenSigSendType" SG_ 2566857664 EMR_Active 1;
BA_ "GenSigSendType" SG_ 2566857664 VDC_Active 1;
BA_ "GenSigSendType" SG_ 2566857664 DefABSConf 1;
BA_ "GenSigSendType" SG_ 2566857664 ActABSConf 1;
BA_ "GenSigSendType" SG_ 2566857664 SysStatus 1;
BA_ "GenSigSendType" SG_ 2566857664 RedWLReq_PGN65315_Tx_2 1;
BA_ "GenSigSendType" SG_ 2566857664 AmbWLReq_PGN65315_Tx_2 1;
BA_ "GenSigSendType" SG_ 2566857664 AmbInfReq 1;
BA_ "VFrameFormat" BO_ 2566857656 1;
BA_ "GenSigSendType" SG_ 2566857656 ABS_Active 1;
BA_ "GenSigSendType" SG_ 2566857656 RSP_Active 1;
BA_ "GenSigSendType" SG_ 2566857656 EMR_Active 1;
BA_ "GenSigSendType" SG_ 2566857656 VDC_Active 1;
BA_ "GenSigSendType" SG_ 2566857656 DefABSConf 1;
BA_ "GenSigSendType" SG_ 2566857656 ActABSConf 1;
BA_ "GenSigSendType" SG_ 2566857656 SysStatus 1;
BA_ "GenSigSendType" SG_ 2566857656 RedWLReq_PGN65315_Tx_3 1;
BA_ "GenSigSendType" SG_ 2566857656 AmbWLReq_PGN65315_Tx_3 1;
BA_ "GenSigSendType" SG_ 2566857656 AmbInfReq 1;
BA_ "VFrameFormat" BO_ 2566857648 1;
BA_ "GenSigSendType" SG_ 2566857648 ABS_Active 1;
BA_ "GenSigSendType" SG_ 2566857648 RSP_Active 1;
BA_ "GenSigSendType" SG_ 2566857648 EMR_Active 1;
BA_ "GenSigSendType" SG_ 2566857648 VDC_Active 1;
BA_ "GenSigSendType" SG_ 2566857648 DefABSConf 1;
BA_ "GenSigSendType" SG_ 2566857648 ActABSConf 1;
BA_ "GenSigSendType" SG_ 2566857648 SysStatus 1;
BA_ "GenSigSendType" SG_ 2566857648 RedWLReq_PGN65315_Tx_4 1;
BA_ "GenSigSendType" SG_ 2566857648 AmbWLReq_PGN65315_Tx_4 1;
BA_ "GenSigSendType" SG_ 2566857648 AmbInfReq 1;
BA_ "VFrameFormat" BO_ 2566857640 1;
BA_ "GenSigSendType" SG_ 2566857640 ABS_Active 1;
BA_ "GenSigSendType" SG_ 2566857640 RSP_Active 1;
BA_ "GenSigSendType" SG_ 2566857640 EMR_Active 1;
BA_ "GenSigSendType" SG_ 2566857640 VDC_Active 1;
BA_ "GenSigSendType" SG_ 2566857640 DefABSConf 1;
BA_ "GenSigSendType" SG_ 2566857640 ActABSConf 1;
BA_ "GenSigSendType" SG_ 2566857640 SysStatus 1;
BA_ "GenSigSendType" SG_ 2566857640 RedWLReq_PGN65315_Tx_5 1;
BA_ "GenSigSendType" SG_ 2566857640 AmbWLReq_PGN65315_Tx_5 1;
BA_ "GenSigSendType" SG_ 2566857640 AmbInfReq 1;
BA_ "VFrameFormat" BO_ 2566857632 1;
BA_ "GenSigSendType" SG_ 2566857632 ABS_Active 1;
BA_ "GenSigSendType" SG_ 2566857632 RSP_Active 1;
BA_ "GenSigSendType" SG_ 2566857632 EMR_Active 1;
BA_ "GenSigSendType" SG_ 2566857632 VDC_Active 1;
BA_ "GenSigSendType" SG_ 2566857632 DefABSConf 1;
BA_ "GenSigSendType" SG_ 2566857632 ActABSConf 1;
BA_ "GenSigSendType" SG_ 2566857632 SysStatus 1;
BA_ "GenSigSendType" SG_ 2566857632 RedWLReq_PGN65315_Tx_6 1;
BA_ "GenSigSendType" SG_ 2566857632 AmbWLReq_PGN65315_Tx_6 1;
BA_ "GenSigSendType" SG_ 2566857632 AmbInfReq 1;
BA_ "VFrameFormat" BO_ 2566857624 1;
BA_ "GenSigSendType" SG_ 2566857624 ABS_Active 1;
BA_ "GenSigSendType" SG_ 2566857624 RSP_Active 1;
BA_ "GenSigSendType" SG_ 2566857624 EMR_Active 1;
BA_ "GenSigSendType" SG_ 2566857624 VDC_Active 1;
BA_ "GenSigSendType" SG_ 2566857624 DefABSConf 1;
BA_ "GenSigSendType" SG_ 2566857624 ActABSConf 1;
BA_ "GenSigSendType" SG_ 2566857624 SysStatus 1;
BA_ "GenSigSendType" SG_ 2566857624 RedWLReq_PGN65315_Tx_7 1;
BA_ "GenSigSendType" SG_ 2566857624 AmbWLReq_PGN65315_Tx_7 1;
BA_ "GenSigSendType" SG_ 2566857624 AmbInfReq 1;
BA_ "VFrameFormat" BO_ 2566857616 1;
BA_ "GenSigSendType" SG_ 2566857616 ABS_Active 1;
BA_ "GenSigSendType" SG_ 2566857616 RSP_Active 1;
BA_ "GenSigSendType" SG_ 2566857616 EMR_Active 1;
BA_ "GenSigSendType" SG_ 2566857616 VDC_Active 1;
BA_ "GenSigSendType" SG_ 2566857616 DefABSConf 1;
BA_ "GenSigSendType" SG_ 2566857616 ActABSConf 1;
BA_ "GenSigSendType" SG_ 2566857616 SysStatus 1;
BA_ "GenSigSendType" SG_ 2566857616 RedWLReq_PGN65315_Tx_8 1;
BA_ "GenSigSendType" SG_ 2566857616 AmbWLReq_PGN65315_Tx_8 1;
BA_ "GenSigSendType" SG_ 2566857616 AmbInfReq 1;
BA_ "VFrameFormat" BO_ 2566857608 1;
BA_ "GenSigSendType" SG_ 2566857608 ABS_Active 1;
BA_ "GenSigSendType" SG_ 2566857608 RSP_Active 1;
BA_ "GenSigSendType" SG_ 2566857608 EMR_Active 1;
BA_ "GenSigSendType" SG_ 2566857608 VDC_Active 1;
BA_ "GenSigSendType" SG_ 2566857608 DefABSConf 1;
BA_ "GenSigSendType" SG_ 2566857608 ActABSConf 1;
BA_ "GenSigSendType" SG_ 2566857608 SysStatus 1;
BA_ "GenSigSendType" SG_ 2566857608 RedWLReq_PGN65315_Tx_9 1;
BA_ "GenSigSendType" SG_ 2566857608 AmbWLReq_PGN65315_Tx_9 1;
BA_ "GenSigSendType" SG_ 2566857608 AmbInfReq 1;
BA_ "VFrameFormat" BO_ 2566857600 1;
BA_ "GenSigSendType" SG_ 2566857600 ABS_Active 1;
BA_ "GenSigSendType" SG_ 2566857600 RSP_Active 1;
BA_ "GenSigSendType" SG_ 2566857600 EMR_Active 1;
BA_ "GenSigSendType" SG_ 2566857600 VDC_Active 1;
BA_ "GenSigSendType" SG_ 2566857600 DefABSConf 1;
BA_ "GenSigSendType" SG_ 2566857600 ActABSConf 1;
BA_ "GenSigSendType" SG_ 2566857600 SysStatus 1;
BA_ "GenSigSendType" SG_ 2566857600 RedWLReq_PGN65315_Tx_10 1;
BA_ "GenSigSendType" SG_ 2566857600 AmbWLReq_PGN65315_Tx_10 1;
BA_ "GenSigSendType" SG_ 2566857600 AmbInfReq 1;
BA_ "VFrameFormat" BO_ 2566857928 1;
BA_ "GenSigSendType" SG_ 2566857928 vWhl4 1;
BA_ "GenSigSendType" SG_ 2566857928 vWhl5 1;
BA_ "GenSigSendType" SG_ 2566857928 BrAct 1;
BA_ "GenSigSendType" SG_ 2566857928 ABSAct 1;
BA_ "GenSigSendType" SG_ 2566857928 RSPAct 1;
BA_ "GenSigSendType" SG_ 2566857928 Overload_PGN65316_Tx 1;
BA_ "GenSigSendType" SG_ 2566857928 PDem 1;
BA_ "GenSigSendType" SG_ 2566857928 TrlWeight 1;
BA_ "GenSigSendType" SG_ 2566857928 TiltAngle 1;
BA_ "GenSigSendType" SG_ 2566857928 TAactive 1;
BA_ "GenSigSendType" SG_ 2566857928 BodyLift_PGN65316_Tx 1;
BA_ "NmAsrNode" BU_ ADL 0;
BA_ "NmAsrNode" BU_ Aux_Device 0;
BA_ "NmAsrNode" BU_ CANLogger 0;
BA_ "NmAsrNode" BU_ CTU 0;
BA_ "NmAsrNode" BU_ Central 0;
BA_ "NmAsrNode" BU_ CentralMulti 0;
BA_ "NmAsrNode" BU_ OffboardUDS 0;
BA_ "NmAsrNode" BU_ Predecessor_Node 0;
BA_ "NmAsrNode" BU_ RDC 0;
BA_ "NmAsrNode" BU_ Radar 0;
BA_ "NmAsrNode" BU_ SensorCANopen 0;
BA_ "NmAsrNode" BU_ Simulator 0;
BA_ "NmAsrNode" BU_ TEPM 0;
BA_ "NmAsrNode" BU_ TIM 0;
BA_ "NmAsrNode" BU_ TPMS 0;
BA_ "NmAsrNode" BU_ iTEPM 0;
SIG_GROUP_ 1794 AUTO_SG_CANLauschConf_Rx 1 : ConfByte1 ConfByte2 ConfByte3 ConfByte4 ConfByte5 ConfByte6 ConfByte7 ConfByte8;
SIG_GROUP_ 2566759880 AUTO_SG_PGN64933_Tx 1 : StaDoor1;
SIG_GROUP_ 2566759808 AUTO_SG_PGN64933_Tx_10 1 : StaDoor1;
SIG_GROUP_ 2566759872 AUTO_SG_PGN64933_Tx_2 1 : StaDoor1;
SIG_GROUP_ 2566759864 AUTO_SG_PGN64933_Tx_3 1 : StaDoor1;
SIG_GROUP_ 2566759856 AUTO_SG_PGN64933_Tx_4 1 : StaDoor1;
SIG_GROUP_ 2566759848 AUTO_SG_PGN64933_Tx_5 1 : StaDoor1;
SIG_GROUP_ 2566759840 AUTO_SG_PGN64933_Tx_6 1 : StaDoor1;
SIG_GROUP_ 2566759832 AUTO_SG_PGN64933_Tx_7 1 : StaDoor1;
SIG_GROUP_ 2566759824 AUTO_SG_PGN64933_Tx_8 1 : StaDoor1;
SIG_GROUP_ 2566759816 AUTO_SG_PGN64933_Tx_9 1 : StaDoor1;
SIG_GROUP_ 2566849030 AUTO_SG_PGN65282_Radar_Rx 1 : SensorLocation DetectionZone FunctionalStatus ExtInputState DetectionBinStd SensTemperature LongDistanceX LatDistanceY;
SIG_GROUP_ 2566850766 AUTO_SG_PGN65288_Rx 1 : rdc1BrIntvEna rdc1BrDemJ1939 rdc1VersionIndex rdc1VersionData rdc1ErrorCode rdc1Status rdc1CfgDataIdx rdc1MsgCntr rdc1MsgChksum;
SIG_GROUP_ 2566851022 AUTO_SG_PGN65289_Rx 1 : rdc2Dist2SensorRL rdc2Dist2SensorRCL rdc2Dist2SensorRCR rdc2Dist2SensorRR rdc2Dist2SensorTR rdc2Dist2SensorTL rdc2RevSigState rdc2RDCSystemEnabled rdc2MsgCntr rdc2MsgChksum;
SIG_GROUP_ 2566851016 AUTO_SG_PGN65289_Tx 1 : rdc2CfgDataIdx rdc2CfgDataVal rdc2MsgCntrTx rdc2MsgChksumTx;
SIG_GROUP_ 2566850944 AUTO_SG_PGN65289_Tx_10 1 : rdc2CfgDataIdx rdc2CfgDataVal rdc2MsgCntrTx rdc2MsgChksumTx;
SIG_GROUP_ 2566851008 AUTO_SG_PGN65289_Tx_2 1 : rdc2CfgDataIdx rdc2CfgDataVal rdc2MsgCntrTx rdc2MsgChksumTx;
SIG_GROUP_ 2566851000 AUTO_SG_PGN65289_Tx_3 1 : rdc2CfgDataIdx rdc2CfgDataVal rdc2MsgCntrTx rdc2MsgChksumTx;
SIG_GROUP_ 2566850992 AUTO_SG_PGN65289_Tx_4 1 : rdc2CfgDataIdx rdc2CfgDataVal rdc2MsgCntrTx rdc2MsgChksumTx;
SIG_GROUP_ 2566850984 AUTO_SG_PGN65289_Tx_5 1 : rdc2CfgDataIdx rdc2CfgDataVal rdc2MsgCntrTx rdc2MsgChksumTx;
SIG_GROUP_ 2566850976 AUTO_SG_PGN65289_Tx_6 1 : rdc2CfgDataIdx rdc2CfgDataVal rdc2MsgCntrTx rdc2MsgChksumTx;
SIG_GROUP_ 2566850968 AUTO_SG_PGN65289_Tx_7 1 : rdc2CfgDataIdx rdc2CfgDataVal rdc2MsgCntrTx rdc2MsgChksumTx;
SIG_GROUP_ 2566850960 AUTO_SG_PGN65289_Tx_8 1 : rdc2CfgDataIdx rdc2CfgDataVal rdc2MsgCntrTx rdc2MsgChksumTx;
SIG_GROUP_ 2566850952 AUTO_SG_PGN65289_Tx_9 1 : rdc2CfgDataIdx rdc2CfgDataVal rdc2MsgCntrTx rdc2MsgChksumTx;
SIG_GROUP_ 2566851784 AUTO_SG_PGN65292_Tx 1 : rdc3DisableReq rdc3TEBSStatus rdc3MsgCntr rdc3MsgChksum;
SIG_GROUP_ 2566851712 AUTO_SG_PGN65292_Tx_10 1 : rdc3DisableReq rdc3TEBSStatus rdc3MsgCntr rdc3MsgChksum;
SIG_GROUP_ 2566851776 AUTO_SG_PGN65292_Tx_2 1 : rdc3DisableReq rdc3TEBSStatus rdc3MsgCntr rdc3MsgChksum;
SIG_GROUP_ 2566851768 AUTO_SG_PGN65292_Tx_3 1 : rdc3DisableReq rdc3TEBSStatus rdc3MsgCntr rdc3MsgChksum;
SIG_GROUP_ 2566851760 AUTO_SG_PGN65292_Tx_4 1 : rdc3DisableReq rdc3TEBSStatus rdc3MsgCntr rdc3MsgChksum;
SIG_GROUP_ 2566851752 AUTO_SG_PGN65292_Tx_5 1 : rdc3DisableReq rdc3TEBSStatus rdc3MsgCntr rdc3MsgChksum;
SIG_GROUP_ 2566851744 AUTO_SG_PGN65292_Tx_6 1 : rdc3DisableReq rdc3TEBSStatus rdc3MsgCntr rdc3MsgChksum;
SIG_GROUP_ 2566851736 AUTO_SG_PGN65292_Tx_7 1 : rdc3DisableReq rdc3TEBSStatus rdc3MsgCntr rdc3MsgChksum;
SIG_GROUP_ 2566851728 AUTO_SG_PGN65292_Tx_8 1 : rdc3DisableReq rdc3TEBSStatus rdc3MsgCntr rdc3MsgChksum;
SIG_GROUP_ 2566851720 AUTO_SG_PGN65292_Tx_9 1 : rdc3DisableReq rdc3TEBSStatus rdc3MsgCntr rdc3MsgChksum;
SIG_GROUP_ 2566856904 AUTO_SG_PGN65312_Tx 1 : PSys PPneuDem PElDemPress GrossLoadPrc PPneuCh0 PPneuCh1 PPneuCh2;
SIG_GROUP_ 2566856832 AUTO_SG_PGN65312_Tx_10 1 : PSys PPneuDem PElDemPress GrossLoadPrc PPneuCh0 PPneuCh1 PPneuCh2;
SIG_GROUP_ 2566856896 AUTO_SG_PGN65312_Tx_2 1 : PSys PPneuDem PElDemPress GrossLoadPrc PPneuCh0 PPneuCh1 PPneuCh2;
SIG_GROUP_ 2566856888 AUTO_SG_PGN65312_Tx_3 1 : PSys PPneuDem PElDemPress GrossLoadPrc PPneuCh0 PPneuCh1 PPneuCh2;
SIG_GROUP_ 2566856880 AUTO_SG_PGN65312_Tx_4 1 : PSys PPneuDem PElDemPress GrossLoadPrc PPneuCh0 PPneuCh1 PPneuCh2;
SIG_GROUP_ 2566856872 AUTO_SG_PGN65312_Tx_5 1 : PSys PPneuDem PElDemPress GrossLoadPrc PPneuCh0 PPneuCh1 PPneuCh2;
SIG_GROUP_ 2566856864 AUTO_SG_PGN65312_Tx_6 1 : PSys PPneuDem PElDemPress GrossLoadPrc PPneuCh0 PPneuCh1 PPneuCh2;
SIG_GROUP_ 2566856856 AUTO_SG_PGN65312_Tx_7 1 : PSys PPneuDem PElDemPress GrossLoadPrc PPneuCh0 PPneuCh1 PPneuCh2;
SIG_GROUP_ 2566856848 AUTO_SG_PGN65312_Tx_8 1 : PSys PPneuDem PElDemPress GrossLoadPrc PPneuCh0 PPneuCh1 PPneuCh2;
SIG_GROUP_ 2566856840 AUTO_SG_PGN65312_Tx_9 1 : PSys PPneuDem PElDemPress GrossLoadPrc PPneuCh0 PPneuCh1 PPneuCh2;
SIG_GROUP_ 2566857160 AUTO_SG_PGN65313_Tx 1 : vVeh vWhl0 vWhl1 vWhl2 vWhl3 StABSCh0 StABSCh1 StABSCh2;
SIG_GROUP_ 2566857088 AUTO_SG_PGN65313_Tx_10 1 : vVeh vWhl0 vWhl1 vWhl2 vWhl3 StABSCh0 StABSCh1 StABSCh2;
SIG_GROUP_ 2566857152 AUTO_SG_PGN65313_Tx_2 1 : vVeh vWhl0 vWhl1 vWhl2 vWhl3 StABSCh0 StABSCh1 StABSCh2;
SIG_GROUP_ 2566857144 AUTO_SG_PGN65313_Tx_3 1 : vVeh vWhl0 vWhl1 vWhl2 vWhl3 StABSCh0 StABSCh1 StABSCh2;
SIG_GROUP_ 2566857136 AUTO_SG_PGN65313_Tx_4 1 : vVeh vWhl0 vWhl1 vWhl2 vWhl3 StABSCh0 StABSCh1 StABSCh2;
SIG_GROUP_ 2566857128 AUTO_SG_PGN65313_Tx_5 1 : vVeh vWhl0 vWhl1 vWhl2 vWhl3 StABSCh0 StABSCh1 StABSCh2;
SIG_GROUP_ 2566857120 AUTO_SG_PGN65313_Tx_6 1 : vVeh vWhl0 vWhl1 vWhl2 vWhl3 StABSCh0 StABSCh1 StABSCh2;
SIG_GROUP_ 2566857112 AUTO_SG_PGN65313_Tx_7 1 : vVeh vWhl0 vWhl1 vWhl2 vWhl3 StABSCh0 StABSCh1 StABSCh2;
SIG_GROUP_ 2566857104 AUTO_SG_PGN65313_Tx_8 1 : vVeh vWhl0 vWhl1 vWhl2 vWhl3 StABSCh0 StABSCh1 StABSCh2;
SIG_GROUP_ 2566857096 AUTO_SG_PGN65313_Tx_9 1 : vVeh vWhl0 vWhl1 vWhl2 vWhl3 StABSCh0 StABSCh1 StABSCh2;
SIG_GROUP_ 2566857416 AUTO_SG_PGN65314_Tx 1 : RSP_TestPulse RSP_Step_1 RSP_Step_2 RSP_Step_3 Lateral_Accel AyOffset AyLimit TxTask10msRuntime;
SIG_GROUP_ 2566857344 AUTO_SG_PGN65314_Tx_10 1 : RSP_TestPulse RSP_Step_1 RSP_Step_2 RSP_Step_3 Lateral_Accel AyOffset AyLimit TxTask10msRuntime;
SIG_GROUP_ 2566857408 AUTO_SG_PGN65314_Tx_2 1 : RSP_TestPulse RSP_Step_1 RSP_Step_2 RSP_Step_3 Lateral_Accel AyOffset AyLimit TxTask10msRuntime;
SIG_GROUP_ 2566857400 AUTO_SG_PGN65314_Tx_3 1 : RSP_TestPulse RSP_Step_1 RSP_Step_2 RSP_Step_3 Lateral_Accel AyOffset AyLimit TxTask10msRuntime;
SIG_GROUP_ 2566857392 AUTO_SG_PGN65314_Tx_4 1 : RSP_TestPulse RSP_Step_1 RSP_Step_2 RSP_Step_3 Lateral_Accel AyOffset AyLimit TxTask10msRuntime;
SIG_GROUP_ 2566857384 AUTO_SG_PGN65314_Tx_5 1 : RSP_TestPulse RSP_Step_1 RSP_Step_2 RSP_Step_3 Lateral_Accel AyOffset AyLimit TxTask10msRuntime;
SIG_GROUP_ 2566857376 AUTO_SG_PGN65314_Tx_6 1 : RSP_TestPulse RSP_Step_1 RSP_Step_2 RSP_Step_3 Lateral_Accel AyOffset AyLimit TxTask10msRuntime;
SIG_GROUP_ 2566857368 AUTO_SG_PGN65314_Tx_7 1 : RSP_TestPulse RSP_Step_1 RSP_Step_2 RSP_Step_3 Lateral_Accel AyOffset AyLimit TxTask10msRuntime;
SIG_GROUP_ 2566857360 AUTO_SG_PGN65314_Tx_8 1 : RSP_TestPulse RSP_Step_1 RSP_Step_2 RSP_Step_3 Lateral_Accel AyOffset AyLimit TxTask10msRuntime;
SIG_GROUP_ 2566857352 AUTO_SG_PGN65314_Tx_9 1 : RSP_TestPulse RSP_Step_1 RSP_Step_2 RSP_Step_3 Lateral_Accel AyOffset AyLimit TxTask10msRuntime;
SIG_GROUP_ 2566857672 AUTO_SG_PGN65315_Tx 1 : ABS_Active RSP_Active EMR_Active VDC_Active DefABSConf ActABSConf SysStatus RedWLReq_PGN65315_Tx AmbWLReq_PGN65315_Tx AmbInfReq;
SIG_GROUP_ 2566857600 AUTO_SG_PGN65315_Tx_10 1 : ABS_Active RSP_Active EMR_Active VDC_Active DefABSConf ActABSConf SysStatus RedWLReq_PGN65315_Tx_10 AmbWLReq_PGN65315_Tx_10 AmbInfReq;
SIG_GROUP_ 2566857664 AUTO_SG_PGN65315_Tx_2 1 : ABS_Active RSP_Active EMR_Active VDC_Active DefABSConf ActABSConf SysStatus RedWLReq_PGN65315_Tx_2 AmbWLReq_PGN65315_Tx_2 AmbInfReq;
SIG_GROUP_ 2566857656 AUTO_SG_PGN65315_Tx_3 1 : ABS_Active RSP_Active EMR_Active VDC_Active DefABSConf ActABSConf SysStatus RedWLReq_PGN65315_Tx_3 AmbWLReq_PGN65315_Tx_3 AmbInfReq;
SIG_GROUP_ 2566857648 AUTO_SG_PGN65315_Tx_4 1 : ABS_Active RSP_Active EMR_Active VDC_Active DefABSConf ActABSConf SysStatus RedWLReq_PGN65315_Tx_4 AmbWLReq_PGN65315_Tx_4 AmbInfReq;
SIG_GROUP_ 2566857640 AUTO_SG_PGN65315_Tx_5 1 : ABS_Active RSP_Active EMR_Active VDC_Active DefABSConf ActABSConf SysStatus RedWLReq_PGN65315_Tx_5 AmbWLReq_PGN65315_Tx_5 AmbInfReq;
SIG_GROUP_ 2566857632 AUTO_SG_PGN65315_Tx_6 1 : ABS_Active RSP_Active EMR_Active VDC_Active DefABSConf ActABSConf SysStatus RedWLReq_PGN65315_Tx_6 AmbWLReq_PGN65315_Tx_6 AmbInfReq;
SIG_GROUP_ 2566857624 AUTO_SG_PGN65315_Tx_7 1 : ABS_Active RSP_Active EMR_Active VDC_Active DefABSConf ActABSConf SysStatus RedWLReq_PGN65315_Tx_7 AmbWLReq_PGN65315_Tx_7 AmbInfReq;
SIG_GROUP_ 2566857616 AUTO_SG_PGN65315_Tx_8 1 : ABS_Active RSP_Active EMR_Active VDC_Active DefABSConf ActABSConf SysStatus RedWLReq_PGN65315_Tx_8 AmbWLReq_PGN65315_Tx_8 AmbInfReq;
SIG_GROUP_ 2566857608 AUTO_SG_PGN65315_Tx_9 1 : ABS_Active RSP_Active EMR_Active VDC_Active DefABSConf ActABSConf SysStatus RedWLReq_PGN65315_Tx_9 AmbWLReq_PGN65315_Tx_9 AmbInfReq;
SIG_GROUP_ 2566857928 AUTO_SG_PGN65316_Tx 1 : vWhl4 vWhl5 BrAct ABSAct RSPAct Overload_PGN65316_Tx PDem TrlWeight TiltAngle TAactive BodyLift_PGN65316_Tx;
SIG_GROUP_ 2566899912 AUTO_SG_PGN65480_Tx 1 : ADLTxData0 ADLTxData1 ADLTxData2 ADLTxData3 ADLTxData4 ADLTxData5 ADLTxData6 ADLTxData7;
SIG_GROUP_ 2566899840 AUTO_SG_PGN65480_Tx_10 1 : ADLTxData0 ADLTxData1 ADLTxData2 ADLTxData3 ADLTxData4 ADLTxData5 ADLTxData6 ADLTxData7;
SIG_GROUP_ 2566899904 AUTO_SG_PGN65480_Tx_2 1 : ADLTxData0 ADLTxData1 ADLTxData2 ADLTxData3 ADLTxData4 ADLTxData5 ADLTxData6 ADLTxData7;
SIG_GROUP_ 2566899896 AUTO_SG_PGN65480_Tx_3 1 : ADLTxData0 ADLTxData1 ADLTxData2 ADLTxData3 ADLTxData4 ADLTxData5 ADLTxData6 ADLTxData7;
SIG_GROUP_ 2566899888 AUTO_SG_PGN65480_Tx_4 1 : ADLTxData0 ADLTxData1 ADLTxData2 ADLTxData3 ADLTxData4 ADLTxData5 ADLTxData6 ADLTxData7;
SIG_GROUP_ 2566899880 AUTO_SG_PGN65480_Tx_5 1 : ADLTxData0 ADLTxData1 ADLTxData2 ADLTxData3 ADLTxData4 ADLTxData5 ADLTxData6 ADLTxData7;
SIG_GROUP_ 2566899872 AUTO_SG_PGN65480_Tx_6 1 : ADLTxData0 ADLTxData1 ADLTxData2 ADLTxData3 ADLTxData4 ADLTxData5 ADLTxData6 ADLTxData7;
SIG_GROUP_ 2566899864 AUTO_SG_PGN65480_Tx_7 1 : ADLTxData0 ADLTxData1 ADLTxData2 ADLTxData3 ADLTxData4 ADLTxData5 ADLTxData6 ADLTxData7;
SIG_GROUP_ 2566899856 AUTO_SG_PGN65480_Tx_8 1 : ADLTxData0 ADLTxData1 ADLTxData2 ADLTxData3 ADLTxData4 ADLTxData5 ADLTxData6 ADLTxData7;
SIG_GROUP_ 2566899848 AUTO_SG_PGN65480_Tx_9 1 : ADLTxData0 ADLTxData1 ADLTxData2 ADLTxData3 ADLTxData4 ADLTxData5 ADLTxData6 ADLTxData7;
SIG_GROUP_ 2566899968 AUTO_SG_PGN65481_Rx 1 : ADLRxData0 ADLRxData1 ADLRxData2 ADLRxData3 ADLRxData4 ADLRxData5 ADLRxData6 ADLRxData7;
SIG_GROUP_ 1792 AUTO_SG_PlantRequest 1 : PlantCloseLoop PlantEBSmode PlantCommon PlantNoStimuli PlantNoOffset PlantReset PlantNoProcess PlantActive PlantOutputId PlantLowTimeRes PlantSwitchSlow PlantState PlantTrigger PlantNofPulses PlantControlTime PlantPauseTime PlantTargetPres;
SIG_GROUP_ 1793 AUTO_SG_PressSim 1 : P21Sim P22Sim P4Sim AccYSim P1Sim P42Sim;
SIG_GROUP_ 288 AUTO_SG_TEPM_Channel1_Rx 1 : Pact PactP4 AccY AccX AnaMulti IdxMulti fWhl0 fWhl1 fComm fBckp fBabs fEbs fModule;
SIG_GROUP_ 0 AUTO_SG_TEPM_Command_Tx 1 : PdemCh1 PdemCh2 Aux1Act Aux1Cap Aux1OC Aux1DIn Aux2Act Aux2Cap Aux2OC Aux2DIn Aux3Act Aux3Cap Aux3OC Aux3DIn Aux4Act Aux4Cap Aux4OC Aux4DIn Aux5Act Aux5Cap Aux5OC Aux5DIn Aux6Act Aux6Cap Aux6OC Aux6DIn Aux7Act Aux7Cap Aux7OC Aux7DIn Aux5PWM Aux6PWM Aux12PWM Aux3PWM Aux4PWM VehStnd AccStEn PsOfCEn SSup1Off SSup2Off SSup3Off SSup4Off;
SIG_GROUP_ 272 AUTO_SG_TEPM_Wheel1_Rx 1 : vRaw0 nEdge0 ErrCtr0 vRaw1 nEdge1 ErrCtr1;
SIG_GROUP_ 2564483083 AUTO_SG_UDSanswer 1 : UDSbyte1_UDSanswer UDSbyte2_UDSanswer UDSbyte3_UDSanswer UDSbyte4_UDSanswer UDSbyte5_UDSanswer UDSbyte6_UDSanswer UDSbyte7_UDSanswer UDSbyte8_UDSanswer;
SIG_GROUP_ 2631570699 AUTO_SG_UDSanswer_J1939_CTU 1 : UDSbyte1_UDSanswer_J1939_CTU UDSbyte2_UDSanswer_J1939_CTU UDSbyte3_UDSanswer_J1939_CTU UDSbyte4_UDSanswer_J1939_CTU UDSbyte5_UDSanswer_J1939_CTU UDSbyte6_UDSanswer_J1939_CTU UDSbyte7_UDSanswer_J1939_CTU UDSbyte8_UDSanswer_J1939_CTU;
SIG_GROUP_ 2564487947 AUTO_SG_UDSanswer_TIM 1 : UDSbyte1_UDSanswer_TIM UDSbyte2_UDSanswer_TIM UDSbyte3_UDSanswer_TIM UDSbyte4_UDSanswer_TIM UDSbyte5_UDSanswer_TIM UDSbyte6_UDSanswer_TIM UDSbyte7_UDSanswer_TIM UDSbyte8_UDSanswer_TIM;
SIG_GROUP_ 2564426728 AUTO_SG_UDSrequest 1 : UDSbyte1_UDSrequest UDSbyte2_UDSrequest UDSbyte3_UDSrequest UDSbyte4_UDSrequest UDSbyte5_UDSrequest UDSbyte6_UDSrequest UDSbyte7_UDSrequest UDSbyte8_UDSrequest;
SIG_GROUP_ 2631535509 AUTO_SG_UDSrequest_J1939_CTU 1 : UDSbyte1_UDSrequest_J1939_CTU UDSbyte2_UDSrequest_J1939_CTU UDSbyte3_UDSrequest_J1939_CTU UDSbyte4_UDSrequest_J1939_CTU UDSbyte5_UDSrequest_J1939_CTU UDSbyte6_UDSrequest_J1939_CTU UDSbyte7_UDSrequest_J1939_CTU UDSbyte8_UDSrequest_J1939_CTU;
SIG_GROUP_ 2564426747 AUTO_SG_UDSrequest_TIM 1 : UDSbyte1_UDSrequest_TIM UDSbyte2_UDSrequest_TIM UDSbyte3_UDSrequest_TIM UDSbyte4_UDSrequest_TIM UDSbyte5_UDSrequest_TIM UDSbyte6_UDSrequest_TIM UDSbyte7_UDSrequest_TIM UDSbyte8_UDSrequest_TIM;
SIG_GROUP_ 2559314938 AUTO_SG_XCP_Cmd1 1 : XCPCmdB1_XCP_Cmd1 XCPCmdB2_XCP_Cmd1 XCPCmdB3_XCP_Cmd1 XCPCmdB4_XCP_Cmd1 XCPCmdB5_XCP_Cmd1 XCPCmdB6_XCP_Cmd1 XCPCmdB7_XCP_Cmd1 XCPCmdB8_XCP_Cmd1;
SIG_GROUP_ 2559310347 AUTO_SG_XCP_Rsp1 1 : XCPRspB1_XCP_Rsp1 XCPRspB2_XCP_Rsp1 XCPRspB3_XCP_Rsp1 XCPRspB4_XCP_Rsp1 XCPRspB5_XCP_Rsp1 XCPRspB6_XCP_Rsp1 XCPRspB7_XCP_Rsp1 XCPRspB8_XCP_Rsp1;
SIG_GROUP_ 1 AUTO_SG_iTEPM_Control_Tx 1 : CRC_E2E_iTEPM_Control_Tx Counter_E2E_iTEPM_Control_Tx Pdemand VehStnd AccStEn PsOfCEn SSup1Off;
SIG_GROUP_ 289 AUTO_SG_iTEPM_Pressure_Rx 1 : CRC_E2E Counter_E2E Pact PactP4 PactP42 fComm fBckp fBabs fEbs fModule;
SIG_GROUP_ 273 AUTO_SG_iTEPM_WhAcc1_Rx 1 : CRC_E2E Counter_E2E WhNaLeft vRawLeft nEdgeLeft ErrCtrLeft AccSensAxis1_Lat;
SIG_GROUP_ 281 AUTO_SG_iTEPM_WhAcc2_Rx 1 : CRC_E2E Counter_E2E WhNaRight vRawRight nEdgeRight ErrCtrRight AccSensAxis2_Long;
